AUTOSAR XML (schema 4-2-2)
standard types defined: boolean, sint16, uint16, uint8, Boolean, SInt16, UInt16, UInt8
package /Constants
  34 x constant specification:
    IV_CREPE: value-spec={short-label=IV_CREPE, fields=[0, 0, 0, 0]}
    IV_ChPress: value-spec=0
    IV_ChTemp: value-spec=0
    IV_CompPress: value-spec=0
    IV_CompTemp: value-spec=0
    IV_ERV1Cmd: value-spec={short-label=IV_ERV1Cmd, fields=[FALSE, 0]}
    IV_ERV1State: value-spec={short-label=IV_ERV1State, fields=[0, 0, 0]}
    IV_ERV2Cmd: value-spec={short-label=IV_ERV2Cmd, fields=[FALSE, 0]}
    IV_ERV2State: value-spec={short-label=IV_ERV2State, fields=[0, 0, 0]}
    IV_ERV3Cmd: value-spec={short-label=IV_ERV3Cmd, fields=[FALSE, 0]}
    IV_ERV3State: value-spec={short-label=IV_ERV3State, fields=[0, 0, 0]}
    IV_EVAPPress: value-spec=0
    IV_EVAPTemp: value-spec=0
    IV_EXV1Cmd: value-spec={short-label=IV_EXV1Cmd, fields=[FALSE, 0]}
    IV_EXV1State: value-spec={short-label=IV_EXV1State, fields=[0, 0, 0]}
    IV_EXV2Cmd: value-spec={short-label=IV_EXV2Cmd, fields=[FALSE, 0]}
    IV_EXV2State: value-spec={short-label=IV_EXV2State, fields=[0, 0, 0]}
    IV_EXV3Cmd: value-spec={short-label=IV_EXV3Cmd, fields=[FALSE, 0]}
    IV_EXV3State: value-spec={short-label=IV_EXV3State, fields=[0, 0, 0]}
    IV_EXV4Cmd: value-spec={short-label=IV_EXV4Cmd, fields=[FALSE, 0]}
    IV_EXV4State: value-spec={short-label=IV_EXV4State, fields=[0, 0, 0]}
    IV_Ext: value-spec={short-label=IV_Ext, fields=[0, 0, 0, 0, 0, 0, 0]}
    IV_HTPC_CH: value-spec={short-label=IV_HTPC_CH, fields=[FALSE, 0, 0, 0]}
    IV_HTPC_Comp: value-spec={short-label=IV_HTPC_Comp, fields=[FALSE, FALSE]}
    IV_HTPC_ICDS: value-spec={short-label=IV_HTPC_ICDS, fields=0}
    IV_HTPC_NBI: value-spec={short-label=IV_HTPC_NBI, fields=[0, 0, 0, 0]}
    IV_HTPC_OHX: value-spec={short-label=IV_HTPC_OHX, fields=[FALSE, 0, 0]}
    IV_HVEC2HTPC: value-spec={short-label=IV_HVEC2HTPC, fields=[FALSE, FALSE, 0, 0, 0, 0]}
    IV_HvecCmd: value-spec={short-label=IV_HvecCmd, fields=[FALSE, 0]}
    IV_ICDSPress: value-spec=0
    IV_ICDSTemp: value-spec=0
    IV_OHXPress: value-spec=0
    IV_OHXTemp: value-spec=0
    IV_SUCRE: value-spec={short-label=IV_SUCRE, fields=[FALSE, 0, 0, 0, 0, 0, 0, 0, 0, 0, 0, 0, 0, 0, 0]}
package /DataTypeMappingSets
  237 x data type mapping set:
    DTMS_APDT_AlertState: data-type-map{application-data-type=APDT_AlertState, implementation-data-type=DT_AlertState}
    DTMS_APDT_AvailState: data-type-map{application-data-type=APDT_AvailState, implementation-data-type=DT_AvailState}
    DTMS_APDT_CREPE_rOpFSF: data-type-map{application-data-type=APDT_CREPE_rOpFSF, implementation-data-type=DT_CREPE_rOpFSF}
    DTMS_APDT_CREPE_spdAirEstim: data-type-map{application-data-type=APDT_CREPE_spdAirEstim, implementation-data-type=DT_CREPE_spdAirEstim}
    DTMS_APDT_CREPE_tEstimWaInpChil: data-type-map{application-data-type=APDT_CREPE_tEstimWaInpChil, implementation-data-type=DT_CREPE_tEstimWaInpChil}
    DTMS_APDT_CREPE_volfEstimWaChil: data-type-map{application-data-type=APDT_CREPE_volfEstimWaChil, implementation-data-type=DT_CREPE_volfEstimWaChil}
    DTMS_APDT_ChPress: data-type-map{application-data-type=APDT_ChPress, implementation-data-type=DT_ChPress}
    DTMS_APDT_ChTemp: data-type-map{application-data-type=APDT_ChTemp, implementation-data-type=DT_ChTemp}
    DTMS_APDT_CmptMode: data-type-map{application-data-type=APDT_CmptMode, implementation-data-type=DT_CmptMode}
    DTMS_APDT_CmptMode1: data-type-map{application-data-type=APDT_CmptMode1, implementation-data-type=DT_CmptMode1}
    DTMS_APDT_CmptMode_AcSpport10_del: data-type-map{application-data-type=APDT_CmptMode_AcSpport10_del, implementation-data-type=DT_CmptMode_AcSpport10_del}
    DTMS_APDT_CmptMode_ChSupport12_del: data-type-map{application-data-type=APDT_CmptMode_ChSupport12_del, implementation-data-type=DT_CmptMode_ChSupport12_del}
    DTMS_APDT_CmptMode_Comp4: data-type-map{application-data-type=APDT_CmptMode_Comp4, implementation-data-type=DT_CmptMode_Comp4}
    DTMS_APDT_CmptMode_Erv1_5: data-type-map{application-data-type=APDT_CmptMode_Erv1_5, implementation-data-type=DT_CmptMode_Erv1_5}
    DTMS_APDT_CmptMode_Erv2_6: data-type-map{application-data-type=APDT_CmptMode_Erv2_6, implementation-data-type=DT_CmptMode_Erv2_6}
    DTMS_APDT_CmptMode_Erv3_7: data-type-map{application-data-type=APDT_CmptMode_Erv3_7, implementation-data-type=DT_CmptMode_Erv3_7}
    DTMS_APDT_CmptMode_ExvAc0: data-type-map{application-data-type=APDT_CmptMode_ExvAc0, implementation-data-type=DT_CmptMode_ExvAc0}
    DTMS_APDT_CmptMode_ExvByPass1: data-type-map{application-data-type=APDT_CmptMode_ExvByPass1, implementation-data-type=DT_CmptMode_ExvByPass1}
    DTMS_APDT_CmptMode_ExvCh2: data-type-map{application-data-type=APDT_CmptMode_ExvCh2, implementation-data-type=DT_CmptMode_ExvCh2}
    DTMS_APDT_CmptMode_ExvOhx3: data-type-map{application-data-type=APDT_CmptMode_ExvOhx3, implementation-data-type=DT_CmptMode_ExvOhx3}
    DTMS_APDT_CmptMode_IcdsSupport11: data-type-map{application-data-type=APDT_CmptMode_IcdsSupport11, implementation-data-type=DT_CmptMode_IcdsSupport11}
    DTMS_APDT_CmptMode_Null8: data-type-map{application-data-type=APDT_CmptMode_Null8, implementation-data-type=DT_CmptMode_Null8}
    DTMS_APDT_CmptMode_Null9: data-type-map{application-data-type=APDT_CmptMode_Null9, implementation-data-type=DT_CmptMode_Null9}
    DTMS_APDT_CmptMode_OhxSupport13: data-type-map{application-data-type=APDT_CmptMode_OhxSupport13, implementation-data-type=DT_CmptMode_OhxSupport13}
    DTMS_APDT_CmptUsCapState: data-type-map{application-data-type=APDT_CmptUsCapState, implementation-data-type=DT_CmptUsCapState}
    DTMS_APDT_CmptWorkMode: data-type-map{application-data-type=APDT_CmptWorkMode, implementation-data-type=DT_CmptWorkMode}
    DTMS_APDT_CompPress: data-type-map{application-data-type=APDT_CompPress, implementation-data-type=DT_CompPress}
    DTMS_APDT_CompTemp: data-type-map{application-data-type=APDT_CompTemp, implementation-data-type=DT_CompTemp}
    DTMS_APDT_CpId: data-type-map{application-data-type=APDT_CpId, implementation-data-type=DT_CpId}
    DTMS_APDT_CpPara: data-type-map{application-data-type=APDT_CpPara, implementation-data-type=DT_CpPara}
    DTMS_APDT_CpType: data-type-map{application-data-type=APDT_CpType, implementation-data-type=DT_CpType}
    DTMS_APDT_CpValue: data-type-map{application-data-type=APDT_CpValue, implementation-data-type=DT_CpValue}
    DTMS_APDT_CpValueState: data-type-map{application-data-type=APDT_CpValueState, implementation-data-type=DT_CpValueState}
    DTMS_APDT_CpWorkMode: data-type-map{application-data-type=APDT_CpWorkMode, implementation-data-type=DT_CpWorkMode}
    DTMS_APDT_CtrlMode: data-type-map{application-data-type=APDT_CtrlMode, implementation-data-type=DT_CtrlMode}
    DTMS_APDT_CtrlUsCapState: data-type-map{application-data-type=APDT_CtrlUsCapState, implementation-data-type=DT_CtrlUsCapState}
    DTMS_APDT_EVAPPress: data-type-map{application-data-type=APDT_EVAPPress, implementation-data-type=DT_EVAPPress}
    DTMS_APDT_EVAPTemp: data-type-map{application-data-type=APDT_EVAPTemp, implementation-data-type=DT_EVAPTemp}
    DTMS_APDT_Ext_bHeatPmpCf1: data-type-map{application-data-type=APDT_Ext_bHeatPmpCf1, implementation-data-type=DT_Ext_bHeatPmpCf1}
    DTMS_APDT_Ext_bPwrlimitCmpr: data-type-map{application-data-type=APDT_Ext_bPwrlimitCmpr, implementation-data-type=DT_Ext_bPwrlimitCmpr}
    DTMS_APDT_Ext_bStallCmpr: data-type-map{application-data-type=APDT_Ext_bStallCmpr, implementation-data-type=DT_Ext_bStallCmpr}
    DTMS_APDT_Ext_iCmpr: data-type-map{application-data-type=APDT_Ext_iCmpr, implementation-data-type=DT_Ext_iCmpr}
    DTMS_APDT_Ext_mfAirFanEvapEst: data-type-map{application-data-type=APDT_Ext_mfAirFanEvapEst, implementation-data-type=DT_Ext_mfAirFanEvapEst}
    DTMS_APDT_Ext_mfAirFanICndsEst: data-type-map{application-data-type=APDT_Ext_mfAirFanICndsEst, implementation-data-type=DT_Ext_mfAirFanICndsEst}
    DTMS_APDT_Ext_nCmpr: data-type-map{application-data-type=APDT_Ext_nCmpr, implementation-data-type=DT_Ext_nCmpr}
    DTMS_APDT_Ext_rERV{1..3}Mes: data-type-map{application-data-type=APDT_Ext_rERV{1..3}Mes, implementation-data-type=DT_Ext_rERV{1..3}Mes}
    DTMS_APDT_Ext_rEXV{1..4}Mes: data-type-map{application-data-type=APDT_Ext_rEXV{1..4}Mes, implementation-data-type=DT_Ext_rEXV{1..4}Mes}
    DTMS_APDT_Ext_stERV{1..3}: data-type-map{application-data-type=APDT_Ext_stERV{1..3}, implementation-data-type=DT_Ext_stERV{1..3}}
    DTMS_APDT_Ext_stEXV{1..4}: data-type-map{application-data-type=APDT_Ext_stEXV{1..4}, implementation-data-type=DT_Ext_stEXV{1..4}}
    DTMS_APDT_Ext_stHeatPmpTypCf: data-type-map{application-data-type=APDT_Ext_stHeatPmpTypCf, implementation-data-type=DT_Ext_stHeatPmpTypCf}
    DTMS_APDT_Ext_stRefriTypCf: data-type-map{application-data-type=APDT_Ext_stRefriTypCf, implementation-data-type=DT_Ext_stRefriTypCf}
    DTMS_APDT_Ext_stRefriTypCf1: data-type-map{application-data-type=APDT_Ext_stRefriTypCf1, implementation-data-type=DT_Ext_stRefriTypCf1}
    DTMS_APDT_Ext_tAirInpEvaEst: data-type-map{application-data-type=APDT_Ext_tAirInpEvaEst, implementation-data-type=DT_Ext_tAirInpEvaEst}
    DTMS_APDT_Ext_tAirMes: data-type-map{application-data-type=APDT_Ext_tAirMes, implementation-data-type=DT_Ext_tAirMes}
    DTMS_APDT_Ext_tAirMes1: data-type-map{application-data-type=APDT_Ext_tAirMes1, implementation-data-type=DT_Ext_tAirMes1}
    DTMS_APDT_Ext_tInvCmpr: data-type-map{application-data-type=APDT_Ext_tInvCmpr, implementation-data-type=DT_Ext_tInvCmpr}
    DTMS_APDT_Ext_typERV{1..3}: data-type-map{application-data-type=APDT_Ext_typERV{1..3}, implementation-data-type=DT_Ext_typERV{1..3}}
    DTMS_APDT_Ext_typEXV{1..4}: data-type-map{application-data-type=APDT_Ext_typEXV{1..4}, implementation-data-type=DT_Ext_typEXV{1..4}}
    DTMS_APDT_Ext_uCmpr: data-type-map{application-data-type=APDT_Ext_uCmpr, implementation-data-type=DT_Ext_uCmpr}
    DTMS_APDT_Ext_vehspd: data-type-map{application-data-type=APDT_Ext_vehspd, implementation-data-type=DT_Ext_vehspd}
    DTMS_APDT_Ext_vehspd1: data-type-map{application-data-type=APDT_Ext_vehspd1, implementation-data-type=DT_Ext_vehspd1}
    DTMS_APDT_FlowRateEstim: data-type-map{application-data-type=APDT_FlowRateEstim, implementation-data-type=DT_FlowRateEstim}
    DTMS_APDT_FullFilState: data-type-map{application-data-type=APDT_FullFilState, implementation-data-type=DT_FullFilState}
    DTMS_APDT_HTPC_bAcvCmprReq: data-type-map{application-data-type=APDT_HTPC_bAcvCmprReq, implementation-data-type=DT_HTPC_bAcvCmprReq}
    DTMS_APDT_HTPC_bClsFSFReq: data-type-map{application-data-type=APDT_HTPC_bClsFSFReq, implementation-data-type=DT_HTPC_bClsFSFReq}
    DTMS_APDT_HTPC_bDeicingReq: data-type-map{application-data-type=APDT_HTPC_bDeicingReq, implementation-data-type=DT_HTPC_bDeicingReq}
    DTMS_APDT_HTPC_bERV{1..3}InitReq: data-type-map{application-data-type=APDT_HTPC_bERV{1..3}InitReq, implementation-data-type=DT_HTPC_bERV{1..3}InitReq}
    DTMS_APDT_HTPC_bEXV{1..4}InitReq: data-type-map{application-data-type=APDT_HTPC_bEXV{1..4}InitReq, implementation-data-type=DT_HTPC_bEXV{1..4}InitReq}
    DTMS_APDT_HTPC_bHBoostReq: data-type-map{application-data-type=APDT_HTPC_bHBoostReq, implementation-data-type=DT_HTPC_bHBoostReq}
    DTMS_APDT_HTPC_bspdCmprMaxLim: data-type-map{application-data-type=APDT_HTPC_bspdCmprMaxLim, implementation-data-type=DT_HTPC_bspdCmprMaxLim}
    DTMS_APDT_HTPC_bspdCmprMinLim: data-type-map{application-data-type=APDT_HTPC_bspdCmprMinLim, implementation-data-type=DT_HTPC_bspdCmprMinLim}
    DTMS_APDT_HTPC_nCmprSp: data-type-map{application-data-type=APDT_HTPC_nCmprSp, implementation-data-type=DT_HTPC_nCmprSp}
    DTMS_APDT_HTPC_pwrCndsEstim: data-type-map{application-data-type=APDT_HTPC_pwrCndsEstim, implementation-data-type=DT_HTPC_pwrCndsEstim}
    DTMS_APDT_HTPC_pwrEvapEstim: data-type-map{application-data-type=APDT_HTPC_pwrEvapEstim, implementation-data-type=DT_HTPC_pwrEvapEstim}
    DTMS_APDT_HTPC_rERV{1..3}Req: data-type-map{application-data-type=APDT_HTPC_rERV{1..3}Req, implementation-data-type=DT_HTPC_rERV{1..3}Req}
    DTMS_APDT_HTPC_rEXV{1..4}Req: data-type-map{application-data-type=APDT_HTPC_rEXV{1..4}Req, implementation-data-type=DT_HTPC_rEXV{1..4}Req}
    DTMS_APDT_HTPC_rHVWHSp: data-type-map{application-data-type=APDT_HTPC_rHVWHSp, implementation-data-type=DT_HTPC_rHVWHSp}
    DTMS_APDT_HTPC_spdAirCndSp: data-type-map{application-data-type=APDT_HTPC_spdAirCndSp, implementation-data-type=DT_HTPC_spdAirCndSp}
    DTMS_APDT_HTPC_stFctHeatPmp: data-type-map{application-data-type=APDT_HTPC_stFctHeatPmp, implementation-data-type=DT_HTPC_stFctHeatPmp}
    DTMS_APDT_HTPC_stOHXestim: data-type-map{application-data-type=APDT_HTPC_stOHXestim, implementation-data-type=DT_HTPC_stOHXestim}
    DTMS_APDT_HTPC_tAirOutICoEstim: data-type-map{application-data-type=APDT_HTPC_tAirOutICoEstim, implementation-data-type=DT_HTPC_tAirOutICoEstim}
    DTMS_APDT_HTPC_tWaChilInTrg: data-type-map{application-data-type=APDT_HTPC_tWaChilInTrg, implementation-data-type=DT_HTPC_tWaChilInTrg}
    DTMS_APDT_HTPC_volfWaChilSp: data-type-map{application-data-type=APDT_HTPC_volfWaChilSp, implementation-data-type=DT_HTPC_volfWaChilSp}
    DTMS_APDT_ICDSPress: data-type-map{application-data-type=APDT_ICDSPress, implementation-data-type=DT_ICDSPress}
    DTMS_APDT_ICDSTemp: data-type-map{application-data-type=APDT_ICDSTemp, implementation-data-type=DT_ICDSTemp}
    DTMS_APDT_LoadLevel: data-type-map{application-data-type=APDT_LoadLevel, implementation-data-type=DT_LoadLevel}
    DTMS_APDT_LoadLevelState: data-type-map{application-data-type=APDT_LoadLevelState, implementation-data-type=DT_LoadLevelState}
    DTMS_APDT_LoadPwrRuning: data-type-map{application-data-type=APDT_LoadPwrRuning, implementation-data-type=DT_LoadPwrRuning}
    DTMS_APDT_NextMode: data-type-map{application-data-type=APDT_NextMode, implementation-data-type=DT_NextMode}
    DTMS_APDT_NtfDevState: data-type-map{application-data-type=APDT_NtfDevState, implementation-data-type=DT_NtfDevState}
    DTMS_APDT_NtfPosState: data-type-map{application-data-type=APDT_NtfPosState, implementation-data-type=DT_NtfPosState}
    DTMS_APDT_NtfSensorState: data-type-map{application-data-type=APDT_NtfSensorState, implementation-data-type=DT_NtfSensorState}
    DTMS_APDT_NtfSpdState: data-type-map{application-data-type=APDT_NtfSpdState, implementation-data-type=DT_NtfSpdState}
    DTMS_APDT_OHXPress: data-type-map{application-data-type=APDT_OHXPress, implementation-data-type=DT_OHXPress}
    DTMS_APDT_OHXTemp: data-type-map{application-data-type=APDT_OHXTemp, implementation-data-type=DT_OHXTemp}
    DTMS_APDT_OverallCondenPwr: data-type-map{application-data-type=APDT_OverallCondenPwr, implementation-data-type=DT_OverallCondenPwr}
    DTMS_APDT_OverallEvapPwr: data-type-map{application-data-type=APDT_OverallEvapPwr, implementation-data-type=DT_OverallEvapPwr}
    DTMS_APDT_PPos: data-type-map{application-data-type=APDT_PPos, implementation-data-type=DT_PPos}
    DTMS_APDT_PValue: data-type-map{application-data-type=APDT_PValue, implementation-data-type=DT_PValue}
    DTMS_APDT_PidParaId: data-type-map{application-data-type=APDT_PidParaId, implementation-data-type=DT_PidParaId}
    DTMS_APDT_PwrUpperLimit: data-type-map{application-data-type=APDT_PwrUpperLimit, implementation-data-type=DT_PwrUpperLimit}
    DTMS_APDT_RefrigFlowVolEstim: data-type-map{application-data-type=APDT_RefrigFlowVolEstim, implementation-data-type=DT_RefrigFlowVolEstim}
    DTMS_APDT_RefrigLackStatus: data-type-map{application-data-type=APDT_RefrigLackStatus, implementation-data-type=DT_RefrigLackStatus}
    DTMS_APDT_ReqMode: data-type-map{application-data-type=APDT_ReqMode, implementation-data-type=DT_ReqMode}
    DTMS_APDT_SMax: data-type-map{application-data-type=APDT_SMax, implementation-data-type=DT_SMax}
    DTMS_APDT_SMin: data-type-map{application-data-type=APDT_SMin, implementation-data-type=DT_SMin}
    DTMS_APDT_SPos: data-type-map{application-data-type=APDT_SPos, implementation-data-type=DT_SPos}
    DTMS_APDT_SPosLowerLimit: data-type-map{application-data-type=APDT_SPosLowerLimit, implementation-data-type=DT_SPosLowerLimit}
    DTMS_APDT_SPosUpperLimit: data-type-map{application-data-type=APDT_SPosUpperLimit, implementation-data-type=DT_SPosUpperLimit}
    DTMS_APDT_SUCRE_bDeIcingAuthor: data-type-map{application-data-type=APDT_SUCRE_bDeIcingAuthor, implementation-data-type=DT_SUCRE_bDeIcingAuthor}
    DTMS_APDT_SUCRE_fintempsensor: data-type-map{application-data-type=APDT_SUCRE_fintempsensor, implementation-data-type=DT_SUCRE_fintempsensor}
    DTMS_APDT_SUCRE_nCmprMaxSp: data-type-map{application-data-type=APDT_SUCRE_nCmprMaxSp, implementation-data-type=DT_SUCRE_nCmprMaxSp}
    DTMS_APDT_SUCRE_pwrCmprMaxSp: data-type-map{application-data-type=APDT_SUCRE_pwrCmprMaxSp, implementation-data-type=DT_SUCRE_pwrCmprMaxSp}
    DTMS_APDT_SUCRE_pwrHVWHMaxSp: data-type-map{application-data-type=APDT_SUCRE_pwrHVWHMaxSp, implementation-data-type=DT_SUCRE_pwrHVWHMaxSp}
    DTMS_APDT_SUCRE_rHVWHAct: data-type-map{application-data-type=APDT_SUCRE_rHVWHAct, implementation-data-type=DT_SUCRE_rHVWHAct}
    DTMS_APDT_SUCRE_stHeatPmpModReq: data-type-map{application-data-type=APDT_SUCRE_stHeatPmpModReq, implementation-data-type=DT_SUCRE_stHeatPmpModReq}
    DTMS_APDT_SUCRE_tAirOutEvaSp: data-type-map{application-data-type=APDT_SUCRE_tAirOutEvaSp, implementation-data-type=DT_SUCRE_tAirOutEvaSp}
    DTMS_APDT_SUCRE_tAirOutEvapOfs: data-type-map{application-data-type=APDT_SUCRE_tAirOutEvapOfs, implementation-data-type=DT_SUCRE_tAirOutEvapOfs}
    DTMS_APDT_SUCRE_tAirOutICoSp: data-type-map{application-data-type=APDT_SUCRE_tAirOutICoSp, implementation-data-type=DT_SUCRE_tAirOutICoSp}
    DTMS_APDT_SUCRE_tAirOutIEvaMes: data-type-map{application-data-type=APDT_SUCRE_tAirOutIEvaMes, implementation-data-type=DT_SUCRE_tAirOutIEvaMes}
    DTMS_APDT_SUCRE_tWaOutChilMaxSp: data-type-map{application-data-type=APDT_SUCRE_tWaOutChilMaxSp, implementation-data-type=DT_SUCRE_tWaOutChilMaxSp}
    DTMS_APDT_SUCRE_tWaOutChilMes: data-type-map{application-data-type=APDT_SUCRE_tWaOutChilMes, implementation-data-type=DT_SUCRE_tWaOutChilMes}
    DTMS_APDT_SUCRE_tWaOutChilMinSp: data-type-map{application-data-type=APDT_SUCRE_tWaOutChilMinSp, implementation-data-type=DT_SUCRE_tWaOutChilMinSp}
    DTMS_APDT_SUCRE_tWaOutChilSp: data-type-map{application-data-type=APDT_SUCRE_tWaOutChilSp, implementation-data-type=DT_SUCRE_tWaOutChilSp}
    DTMS_APDT_SValue: data-type-map{application-data-type=APDT_SValue, implementation-data-type=DT_SValue}
    DTMS_APDT_TrpId: data-type-map{application-data-type=APDT_TrpId, implementation-data-type=DT_TrpId}
    DTMS_APDT_UsCapState: data-type-map{application-data-type=APDT_UsCapState, implementation-data-type=DT_UsCapState}
    DTMS_APDT_WorkMode: data-type-map{application-data-type=APDT_WorkMode, implementation-data-type=DT_WorkMode}
    DTMS_APDT_WorkMode1: data-type-map{application-data-type=APDT_WorkMode1, implementation-data-type=DT_WorkMode1}
    DTMS_ARDT_BusActCtrlSetElement: data-type-map{application-data-type=ARDT_BusActCtrlSetElement, implementation-data-type=RT_BusActCtrlSetElement}
    DTMS_ARDT_BusActStatusElement: data-type-map{application-data-type=ARDT_BusActStatusElement, implementation-data-type=RT_BusActStatusElement}
    DTMS_ARDT_BusCmptModeElement: data-type-map{application-data-type=ARDT_BusCmptModeElement, implementation-data-type=RT_BusCmptModeElement}
    DTMS_ARDT_BusCpCtrlSetElement: data-type-map{application-data-type=ARDT_BusCpCtrlSetElement, implementation-data-type=RT_BusCpCtrlSetElement}
    DTMS_ARDT_BusCpStElement: data-type-map{application-data-type=ARDT_BusCpStElement, implementation-data-type=RT_BusCpStElement}
    DTMS_ARDT_BusTrpSetElement: data-type-map{application-data-type=ARDT_BusTrpSetElement, implementation-data-type=RT_BusTrpSetElement}
    DTMS_ARDT_BusTrpStateElement: data-type-map{application-data-type=ARDT_BusTrpStateElement, implementation-data-type=RT_BusTrpStateElement}
    DTMS_ARDT_CREPE: data-type-map{application-data-type=ARDT_CREPE, implementation-data-type=RT_CREPE}
    DTMS_ARDT_ERV1Cmd: data-type-map{application-data-type=ARDT_ERV1Cmd, implementation-data-type=RT_ERV1Cmd}
    DTMS_ARDT_ERV1State: data-type-map{application-data-type=ARDT_ERV1State, implementation-data-type=RT_ERV1State}
    DTMS_ARDT_ERV2Cmd: data-type-map{application-data-type=ARDT_ERV2Cmd, implementation-data-type=RT_ERV2Cmd}
    DTMS_ARDT_ERV2State: data-type-map{application-data-type=ARDT_ERV2State, implementation-data-type=RT_ERV2State}
    DTMS_ARDT_ERV3Cmd: data-type-map{application-data-type=ARDT_ERV3Cmd, implementation-data-type=RT_ERV3Cmd}
    DTMS_ARDT_ERV3State: data-type-map{application-data-type=ARDT_ERV3State, implementation-data-type=RT_ERV3State}
    DTMS_ARDT_EXV1Cmd: data-type-map{application-data-type=ARDT_EXV1Cmd, implementation-data-type=RT_EXV1Cmd}
    DTMS_ARDT_EXV1State: data-type-map{application-data-type=ARDT_EXV1State, implementation-data-type=RT_EXV1State}
    DTMS_ARDT_EXV2Cmd: data-type-map{application-data-type=ARDT_EXV2Cmd, implementation-data-type=RT_EXV2Cmd}
    DTMS_ARDT_EXV2State: data-type-map{application-data-type=ARDT_EXV2State, implementation-data-type=RT_EXV2State}
    DTMS_ARDT_EXV3Cmd: data-type-map{application-data-type=ARDT_EXV3Cmd, implementation-data-type=RT_EXV3Cmd}
    DTMS_ARDT_EXV3State: data-type-map{application-data-type=ARDT_EXV3State, implementation-data-type=RT_EXV3State}
    DTMS_ARDT_EXV4Cmd: data-type-map{application-data-type=ARDT_EXV4Cmd, implementation-data-type=RT_EXV4Cmd}
    DTMS_ARDT_EXV4State: data-type-map{application-data-type=ARDT_EXV4State, implementation-data-type=RT_EXV4State}
    DTMS_ARDT_Ext: data-type-map{application-data-type=ARDT_Ext, implementation-data-type=RT_Ext}
    DTMS_ARDT_HTPC_CH: data-type-map{application-data-type=ARDT_HTPC_CH, implementation-data-type=RT_HTPC_CH}
    DTMS_ARDT_HTPC_Comp: data-type-map{application-data-type=ARDT_HTPC_Comp, implementation-data-type=RT_HTPC_Comp}
    DTMS_ARDT_HTPC_CompTpcp19In: data-type-map{application-data-type=ARDT_HTPC_CompTpcp19In, implementation-data-type=RT_HTPC_CompTpcp19In}
    DTMS_ARDT_HTPC_CompTpcp8: data-type-map{application-data-type=ARDT_HTPC_CompTpcp24, implementation-data-type=RT_HTPC_CompTpcp24}
    DTMS_ARDT_HTPC_HpAcSensor0: data-type-map{application-data-type=ARDT_HTPC_HpAcSensor0, implementation-data-type=RT_HTPC_HpAcSensor0}
    DTMS_ARDT_HTPC_HpAcSupportState: data-type-map{application-data-type=ARDT_HTPC_HpAcSupportState, implementation-data-type=RT_HTPC_HpAcSupportState}
    DTMS_ARDT_HTPC_HpAcTpcp4: data-type-map{application-data-type=ARDT_HTPC_HpAcTpcp20, implementation-data-type=RT_HTPC_HpAcTpcp20}
    DTMS_ARDT_HTPC_HpBusActCtrlSet: data-type-map{application-data-type=ARDT_HTPC_HpBusActCtrlSet, implementation-data-type=RT_HTPC_HpBusActCtrlSet}
    DTMS_ARDT_HTPC_HpBusActStatus: data-type-map{application-data-type=ARDT_HTPC_HpBusActStatus, implementation-data-type=RT_HTPC_HpBusActStatus}
    DTMS_ARDT_HTPC_HpBusCmptModeResp: data-type-map{application-data-type=ARDT_HTPC_HpBusCmptModeResp, implementation-data-type=RT_HTPC_HpBusCmptModeResp}
    DTMS_ARDT_HTPC_HpBusCpCtrlSet: data-type-map{application-data-type=ARDT_HTPC_HpBusCpCtrlSet, implementation-data-type=RT_HTPC_HpBusCpCtrlSet}
    DTMS_ARDT_HTPC_HpBusCpSt: data-type-map{application-data-type=ARDT_HTPC_HpBusCpSt, implementation-data-type=RT_HTPC_HpBusCpSt}
    DTMS_ARDT_HTPC_HpBusTrpSet_Cmpt: data-type-map{application-data-type=ARDT_HTPC_HpBusTrpSet_Cmpt, implementation-data-type=RT_HTPC_HpBusTrpSet_Cmpt}
    DTMS_ARDT_HTPC_HpBusTrpSet_Ctrl: data-type-map{application-data-type=ARDT_HTPC_HpBusTrpSet_Ctrl, implementation-data-type=RT_HTPC_HpBusTrpSet_Ctrl}
    DTMS_ARDT_HTPC_HpBusTrpSet_Loop: data-type-map{application-data-type=ARDT_HTPC_HpBusTrpSet_Loop, implementation-data-type=RT_HTPC_HpBusTrpSet_Loop}
    DTMS_ARDT_HTPC_HpBusTrpSet_NBI: data-type-map{application-data-type=ARDT_HTPC_HpBusTrpSet_NBI, implementation-data-type=RT_HTPC_HpBusTrpSet_NBI}
    DTMS_ARDT_HTPC_HpBusTrpSet_Req: data-type-map{application-data-type=ARDT_HTPC_HpBusTrpSet_Req, implementation-data-type=RT_HTPC_HpBusTrpSet_Req}
    DTMS_ARDT_HTPC_HpBusTrpState: data-type-map{application-data-type=ARDT_HTPC_HpBusTrpState, implementation-data-type=RT_HTPC_HpBusTrpState}
    DTMS_ARDT_HTPC_HpChSensor2: data-type-map{application-data-type=ARDT_HTPC_HpChSensor2, implementation-data-type=RT_HTPC_HpChSensor2}
    DTMS_ARDT_HTPC_HpChSupportState: data-type-map{application-data-type=ARDT_HTPC_HpChSupportState, implementation-data-type=RT_HTPC_HpChSupportState}
    DTMS_ARDT_HTPC_HpChTpcp6: data-type-map{application-data-type=ARDT_HTPC_HpChTpcp22, implementation-data-type=RT_HTPC_HpChTpcp22}
    DTMS_ARDT_HTPC_HpCompState: data-type-map{application-data-type=ARDT_HTPC_HpCompState, implementation-data-type=RT_HTPC_HpCompState}
    DTMS_ARDT_HTPC_HpErv{1..3}State: data-type-map{application-data-type=ARDT_HTPC_HpErv{1..3}State, implementation-data-type=RT_HTPC_HpErv{1..3}State}
    DTMS_ARDT_HTPC_HpExvAState: data-type-map{application-data-type=ARDT_HTPC_HpExvAState, implementation-data-type=RT_HTPC_HpExvAState}
    DTMS_ARDT_HTPC_HpExvBState: data-type-map{application-data-type=ARDT_HTPC_HpExvBState, implementation-data-type=RT_HTPC_HpExvBState}
    DTMS_ARDT_HTPC_HpExvByPassState: data-type-map{application-data-type=ARDT_HTPC_HpExvByPassState, implementation-data-type=RT_HTPC_HpExvByPassState}
    DTMS_ARDT_HTPC_HpExvHState: data-type-map{application-data-type=ARDT_HTPC_HpExvHState, implementation-data-type=RT_HTPC_HpExvHState}
    DTMS_ARDT_HTPC_HpIcdsSensor1: data-type-map{application-data-type=ARDT_HTPC_HpIcdsSensor1, implementation-data-type=RT_HTPC_HpIcdsSensor1}
    DTMS_ARDT_HTPC_HpIcdsSupportState: data-type-map{application-data-type=ARDT_HTPC_HpIcdsSupportState, implementation-data-type=RT_HTPC_HpIcdsSupportState}
    DTMS_ARDT_HTPC_HpIcdsTpcp5: data-type-map{application-data-type=ARDT_HTPC_HpIcdsTpcp21, implementation-data-type=RT_HTPC_HpIcdsTpcp21}
    DTMS_ARDT_HTPC_HpOhxSensor3: data-type-map{application-data-type=ARDT_HTPC_HpOhxSensor3, implementation-data-type=RT_HTPC_HpOhxSensor3}
    DTMS_ARDT_HTPC_HpOhxSupportState: data-type-map{application-data-type=ARDT_HTPC_HpOhxSupportState, implementation-data-type=RT_HTPC_HpOhxSupportState}
    DTMS_ARDT_HTPC_HpOhxTpcp18In: data-type-map{application-data-type=ARDT_HTPC_HpOhxTpcp18In, implementation-data-type=RT_HTPC_HpOhxTpcp18In}
    DTMS_ARDT_HTPC_HpOhxTpcp7: data-type-map{application-data-type=ARDT_HTPC_HpOhxTpcp23, implementation-data-type=RT_HTPC_HpOhxTpcp23}
    DTMS_ARDT_HTPC_HpOverallCycleStatus: data-type-map{application-data-type=ARDT_HTPC_HpOverallCycleStatus, implementation-data-type=RT_HTPC_HpOverallCycleStatus}
    DTMS_ARDT_HTPC_ICDS: data-type-map{application-data-type=ARDT_HTPC_ICDS, implementation-data-type=RT_HTPC_ICDS}
    DTMS_ARDT_HTPC_LoopDiversity: data-type-map{application-data-type=ARDT_HTPC_LoopDiversity, implementation-data-type=RT_HTPC_LoopDiversity}
    DTMS_ARDT_HTPC_NBI: data-type-map{application-data-type=ARDT_HTPC_NBI, implementation-data-type=RT_HTPC_NBI}
    DTMS_ARDT_HTPC_OHX: data-type-map{application-data-type=ARDT_HTPC_OHX, implementation-data-type=RT_HTPC_OHX}
    DTMS_ARDT_HTPC_PAcO20: data-type-map{application-data-type=ARDT_HTPC_PAcO10, implementation-data-type=RT_HTPC_PAcO10}
    DTMS_ARDT_HTPC_PChO22: data-type-map{application-data-type=ARDT_HTPC_PChO12, implementation-data-type=RT_HTPC_PChO12}
    DTMS_ARDT_HTPC_PCompIn15: data-type-map{application-data-type=ARDT_HTPC_PCompIn15, implementation-data-type=RT_HTPC_PCompIn15}
    DTMS_ARDT_HTPC_PCompO24: data-type-map{application-data-type=ARDT_HTPC_PCompO14, implementation-data-type=RT_HTPC_PCompO14}
    DTMS_ARDT_HTPC_PIcdsO21: data-type-map{application-data-type=ARDT_HTPC_PIcdsO11, implementation-data-type=RT_HTPC_PIcdsO11}
    DTMS_ARDT_HTPC_POhxIn17: data-type-map{application-data-type=ARDT_HTPC_POhxIn17, implementation-data-type=RT_HTPC_POhxIn17}
    DTMS_ARDT_HTPC_POhxO23: data-type-map{application-data-type=ARDT_HTPC_POhxO13, implementation-data-type=RT_HTPC_POhxO13}
    DTMS_ARDT_HTPC_TAcO10: data-type-map{application-data-type=ARDT_HTPC_TAcO5, implementation-data-type=RT_HTPC_TAcO5}
    DTMS_ARDT_HTPC_TChO12: data-type-map{application-data-type=ARDT_HTPC_TChO7, implementation-data-type=RT_HTPC_TChO7}
    DTMS_ARDT_HTPC_TCompIn4: data-type-map{application-data-type=ARDT_HTPC_TCompIn4, implementation-data-type=RT_HTPC_TCompIn4}
    DTMS_ARDT_HTPC_TCompO14: data-type-map{application-data-type=ARDT_HTPC_TCompO9, implementation-data-type=RT_HTPC_TCompO9}
    DTMS_ARDT_HTPC_TIcdsO11: data-type-map{application-data-type=ARDT_HTPC_TIcdsO6, implementation-data-type=RT_HTPC_TIcdsO6}
    DTMS_ARDT_HTPC_TOhxIn16: data-type-map{application-data-type=ARDT_HTPC_TOhxIn16, implementation-data-type=RT_HTPC_TOhxIn16}
    DTMS_ARDT_HTPC_TOhxO13: data-type-map{application-data-type=ARDT_HTPC_TOhxO8, implementation-data-type=RT_HTPC_TOhxO8}
    DTMS_ARDT_HVEC2HTPC: data-type-map{application-data-type=ARDT_HVEC2HTPC, implementation-data-type=RT_HVEC2HTPC}
    DTMS_ARDT_HvecCmd: data-type-map{application-data-type=ARDT_HvecCmd, implementation-data-type=RT_HvecCmd}
    DTMS_ARDT_SUCRE: data-type-map{application-data-type=ARDT_SUCRE, implementation-data-type=RT_SUCRE}
    DTMS_EcuM_Mode: mode-request-type-map{implementation-data-type=UInt8, mode-group=EcuM_Mode}
    DTMS_RCD_stWkuMainRelSt: mode-request-type-map{implementation-data-type=UInt8, mode-group=RCD_stWkuMainRelSt}
package /DataTypes/ApplicationDataTypes
  154 x app type, all with category=VALUE, compu {phys=raw; unit psa_no_unit}:
    APDT_AlertState: range phys 0..255
    APDT_AvailState: range phys 0..255
    APDT_CREPE_rOpFSF: range phys 0..255
    APDT_CREPE_spdAirEstim: range phys -32768..32767
    APDT_CREPE_tEstimWaInpChil: range phys -32768..32767
    APDT_CREPE_volfEstimWaChil: range phys -32768..32767
    APDT_ChPress: range phys -32768..32767
    APDT_ChTemp: range phys -32768..32767
    APDT_CmptMode: range phys 0..255
    APDT_CmptMode1: range phys 0..255
    APDT_CmptMode_AcSpport10_del: range phys 0..255
    APDT_CmptMode_ChSupport12_del: range phys 0..255
    APDT_CmptMode_Comp4: range phys 0..255
    APDT_CmptMode_Erv1_5: range phys 0..255
    APDT_CmptMode_Erv2_6: range phys 0..255
    APDT_CmptMode_Erv3_7: range phys 0..255
    APDT_CmptMode_ExvAc0: range phys 0..255
    APDT_CmptMode_ExvByPass1: range phys 0..255
    APDT_CmptMode_ExvCh2: range phys 0..255
    APDT_CmptMode_ExvOhx3: range phys 0..255
    APDT_CmptMode_IcdsSupport11: range phys 0..255
    APDT_CmptMode_Null8: range phys 0..255
    APDT_CmptMode_Null9: range phys 0..255
    APDT_CmptMode_OhxSupport13: range phys 0..255
    APDT_CmptUsCapState: range phys 0..255
    APDT_CmptWorkMode: range phys 0..255
    APDT_CompPress: range phys -32768..32767
    APDT_CompTemp: range phys -32768..32767
    APDT_CpId: range phys 0..255
    APDT_CpPara: range phys 0..255
    APDT_CpType: range phys 0..255
    APDT_CpValue: range phys -32768..32767
    APDT_CpValueState: range phys 0..255
    APDT_CpWorkMode: range phys 0..255
    APDT_CtrlMode: range phys 0..255
    APDT_CtrlUsCapState: range phys 0..255
    APDT_EVAPPress: range phys -32768..32767
    APDT_EVAPTemp: range phys -32768..32767
    APDT_Ext_bHeatPmpCf1: range phys 0..255
    APDT_Ext_bPwrlimitCmpr: range phys 0..1
    APDT_Ext_bStallCmpr: range phys 0..1
    APDT_Ext_iCmpr: range phys -32768..32767
    APDT_Ext_mfAirFanEvapEst: range phys -32768..32767
    APDT_Ext_mfAirFanICndsEst: range phys -32768..32767
    APDT_Ext_nCmpr: range phys -32768..32767
    APDT_Ext_rERV{1..3}Mes: range phys 0..65535
    APDT_Ext_rEXV{1..4}Mes: range phys 0..65535
    APDT_Ext_stERV{1..3}: range phys 0..255
    APDT_Ext_stEXV{1..4}: range phys 0..255
    APDT_Ext_stHeatPmpTypCf: range phys 0..255
    APDT_Ext_stRefriTypCf: range phys 0..255
    APDT_Ext_stRefriTypCf1: range phys 0..255
    APDT_Ext_tAirInpEvaEst: range phys -32768..32767
    APDT_Ext_tAirMes: range phys -32768..32767
    APDT_Ext_tAirMes1: range phys -32768..32767
    APDT_Ext_tInvCmpr: range phys -32768..32767
    APDT_Ext_typERV{1..3}: range phys -32768..32767
    APDT_Ext_typEXV{1..4}: range phys -32768..32767
    APDT_Ext_uCmpr: range phys -32768..32767
    APDT_Ext_vehspd: range phys -32768..32767
    APDT_Ext_vehspd1: range phys -32768..32767
    APDT_FlowRateEstim: range phys -32768..32767
    APDT_FullFilState: range phys 0..255
    APDT_HTPC_bAcvCmprReq: range phys 0..1
    APDT_HTPC_bClsFSFReq: range phys 0..1
    APDT_HTPC_bDeicingReq: range phys 0..1
    APDT_HTPC_bERV{1..3}InitReq: range phys 0..1
    APDT_HTPC_bEXV{1..4}InitReq: range phys 0..1
    APDT_HTPC_bHBoostReq: range phys 0..1
    APDT_HTPC_bspdCmprMaxLim: range phys 0..1
    APDT_HTPC_bspdCmprMinLim: range phys 0..1
    APDT_HTPC_nCmprSp: range phys -32768..32767
    APDT_HTPC_pwrCndsEstim: range phys -32768..32767
    APDT_HTPC_pwrEvapEstim: range phys -32768..32767
    APDT_HTPC_rERV{1..3}Req: range phys 0..65535
    APDT_HTPC_rEXV{1..4}Req: range phys 0..65535
    APDT_HTPC_rHVWHSp: range phys 0..255
    APDT_HTPC_spdAirCndSp: range phys -32768..32767
    APDT_HTPC_stFctHeatPmp: range phys 0..255
    APDT_HTPC_stOHXestim: range phys 0..255
    APDT_HTPC_tAirOutICoEstim: range phys -32768..32767
    APDT_HTPC_tWaChilInTrg: range phys -32768..32767
    APDT_HTPC_volfWaChilSp: range phys -32768..32767
    APDT_ICDSPress: range phys -32768..32767
    APDT_ICDSTemp: range phys -32768..32767
    APDT_LoadLevel: range phys 0..255
    APDT_LoadLevelState: range phys 0..255
    APDT_LoadPwrRuning: range phys -32768..32767
    APDT_NextMode: range phys 0..255
    APDT_NtfDevState: range phys -32768..32767
    APDT_NtfPosState: range phys -32768..32767
    APDT_NtfSensorState: range phys -32768..32767
    APDT_NtfSpdState: range phys -32768..32767
    APDT_OHXPress: range phys -32768..32767
    APDT_OHXTemp: range phys -32768..32767
    APDT_OverallCondenPwr: range phys -32768..32767
    APDT_OverallEvapPwr: range phys -32768..32767
    APDT_PPos: range phys -32768..32767
    APDT_PValue: range phys -32768..32767
    APDT_PidParaId: range phys 0..255
    APDT_PwrUpperLimit: range phys -32768..32767
    APDT_RefrigFlowVolEstim: range phys -32768..32767
    APDT_RefrigLackStatus: range phys 0..255
    APDT_ReqMode: range phys 0..255
    APDT_SMax: range phys -32768..32767
    APDT_SMin: range phys -32768..32767
    APDT_SPos: range phys -32768..32767
    APDT_SPosLowerLimit: range phys -32768..32767
    APDT_SPosUpperLimit: range phys -32768..32767
    APDT_SUCRE_bDeIcingAuthor: range phys 0..1
    APDT_SUCRE_fintempsensor: range phys -32768..32767
    APDT_SUCRE_nCmprMaxSp: range phys -32768..32767
    APDT_SUCRE_pwrCmprMaxSp: range phys -32768..32767
    APDT_SUCRE_pwrHVWHMaxSp: range phys -32768..32767
    APDT_SUCRE_rHVWHAct: range phys 0..255
    APDT_SUCRE_stHeatPmpModReq: range phys 0..255
    APDT_SUCRE_tAirOutEvaSp: range phys -32768..32767
    APDT_SUCRE_tAirOutEvapOfs: range phys -32768..32767
    APDT_SUCRE_tAirOutICoSp: range phys -32768..32767
    APDT_SUCRE_tAirOutIEvaMes: range phys -32768..32767
    APDT_SUCRE_tWaOutChilMaxSp: range phys -32768..32767
    APDT_SUCRE_tWaOutChilMes: range phys -32768..32767
    APDT_SUCRE_tWaOutChilMinSp: range phys -32768..32767
    APDT_SUCRE_tWaOutChilSp: range phys -32768..32767
    APDT_SValue: range phys -32768..32767
    APDT_TrpId: range phys 0..255
    APDT_UsCapState: range phys 0..255
    APDT_WorkMode: range phys 0..255
    APDT_WorkMode1: range phys 0..255
  81 x application record data type, all with category=STRUCTURE:
    ARDT_BusActCtrlSetElement
      8 x application record element, all with category=VALUE:
        PidParaId: type=APDT_PidParaId
        CtrlMode: type=APDT_CtrlMode
        TrpId: type=APDT_TrpId
        CpId: type=APDT_CpId
        CmptMode: type=APDT_CmptMode
        PwrUpperLimit: type=APDT_PwrUpperLimit
        SPosUpperLimit: type=APDT_SPosUpperLimit
        SPosLowerLimit: type=APDT_SPosLowerLimit
    ARDT_BusActStatusElement
      7 x application record element, all with category=VALUE:
        CtrlUsCapState: type=APDT_CtrlUsCapState
        CmptUsCapState: type=APDT_CmptUsCapState
        LoadLevelState: type=APDT_LoadLevelState
        PPos: type=APDT_PPos
        SPos: type=APDT_SPos
        FlowRateEstim: type=APDT_FlowRateEstim
        CmptWorkMode: type=APDT_CmptWorkMode
    ARDT_BusCmptModeElement
      14 x application record element, all with category=VALUE:
        CmptMode_ExvAc0: type=APDT_CmptMode_ExvAc0
        CmptMode_ExvByPass1: type=APDT_CmptMode_ExvByPass1
        CmptMode_ExvCh2: type=APDT_CmptMode_ExvCh2
        CmptMode_ExvOhx3: type=APDT_CmptMode_ExvOhx3
        CmptMode_Comp4: type=APDT_CmptMode_Comp4
        CmptMode_Erv1_5: type=APDT_CmptMode_Erv1_5
        CmptMode_Erv2_6: type=APDT_CmptMode_Erv2_6
        CmptMode_Erv3_7: type=APDT_CmptMode_Erv3_7
        CmptMode_Null8: type=APDT_CmptMode_Null8
        CmptMode_Null9: type=APDT_CmptMode_Null9
        CmptMode_AcSpport10_del: type=APDT_CmptMode_AcSpport10_del
        CmptMode_IcdsSupport11: type=APDT_CmptMode_IcdsSupport11
        CmptMode_ChSupport12_del: type=APDT_CmptMode_ChSupport12_del
        CmptMode_OhxSupport13: type=APDT_CmptMode_OhxSupport13
    ARDT_BusCpCtrlSetElement
      application record element CmptMode1: category=VALUE, type=APDT_CmptMode1
      application record element CpPara: category=VALUE, type=APDT_CpPara
    ARDT_BusCpStElement
      4 x application record element, all with category=VALUE:
        CpType: type=APDT_CpType
        CpValueState: type=APDT_CpValueState
        CpWorkMode: type=APDT_CpWorkMode
        CpValue: type=APDT_CpValue
    ARDT_BusTrpSetElement
      5 x application record element, all with category=VALUE:
        SValue: type=APDT_SValue
        SMax: type=APDT_SMax
        SMin: type=APDT_SMin
        ReqMode: type=APDT_ReqMode
        NextMode: type=APDT_NextMode
    ARDT_BusTrpStateElement
      8 x application record element, all with category=VALUE:
        AlertState: type=APDT_AlertState
        AvailState: type=APDT_AvailState
        FullFilState: type=APDT_FullFilState
        UsCapState: type=APDT_UsCapState
        WorkMode1: type=APDT_WorkMode1
        LoadLevel: type=APDT_LoadLevel
        PValue: type=APDT_PValue
        LoadPwrRuning: type=APDT_LoadPwrRuning
    ARDT_CREPE
      4 x application record element, all with category=VALUE:
        CREPE_rOpFSF: type=APDT_CREPE_rOpFSF
        CREPE_spdAirEstim: type=APDT_CREPE_spdAirEstim
        CREPE_tEstimWaInpChil: type=APDT_CREPE_tEstimWaInpChil
        CREPE_volfEstimWaChil: type=APDT_CREPE_volfEstimWaChil
    ARDT_ERV1Cmd
      application record element HTPC_bERV1InitReq: category=VALUE, type=APDT_HTPC_bERV1InitReq
      application record element HTPC_rERV1Req: category=VALUE, type=APDT_HTPC_rERV1Req
    ARDT_ERV1State
      application record element Ext_rERV1Mes: category=VALUE, type=APDT_Ext_rERV1Mes
      application record element Ext_stERV1: category=VALUE, type=APDT_Ext_stERV1
      application record element Ext_typERV1: category=VALUE, type=APDT_Ext_typERV1
    ARDT_ERV2Cmd
      application record element HTPC_bERV2InitReq: category=VALUE, type=APDT_HTPC_bERV2InitReq
      application record element HTPC_rERV2Req: category=VALUE, type=APDT_HTPC_rERV2Req
    ARDT_ERV2State
      application record element Ext_rERV2Mes: category=VALUE, type=APDT_Ext_rERV2Mes
      application record element Ext_stERV2: category=VALUE, type=APDT_Ext_stERV2
      application record element Ext_typERV2: category=VALUE, type=APDT_Ext_typERV2
    ARDT_ERV3Cmd
      application record element HTPC_bERV3InitReq: category=VALUE, type=APDT_HTPC_bERV3InitReq
      application record element HTPC_rERV3Req: category=VALUE, type=APDT_HTPC_rERV3Req
    ARDT_ERV3State
      application record element Ext_rERV3Mes: category=VALUE, type=APDT_Ext_rERV3Mes
      application record element Ext_stERV3: category=VALUE, type=APDT_Ext_stERV3
      application record element Ext_typERV3: category=VALUE, type=APDT_Ext_typERV3
    ARDT_EXV1Cmd
      application record element HTPC_bEXV1InitReq: category=VALUE, type=APDT_HTPC_bEXV1InitReq
      application record element HTPC_rEXV1Req: category=VALUE, type=APDT_HTPC_rEXV1Req
    ARDT_EXV1State
      application record element Ext_rEXV1Mes: category=VALUE, type=APDT_Ext_rEXV1Mes
      application record element Ext_stEXV1: category=VALUE, type=APDT_Ext_stEXV1
      application record element Ext_typEXV1: category=VALUE, type=APDT_Ext_typEXV1
    ARDT_EXV2Cmd
      application record element HTPC_bEXV2InitReq: category=VALUE, type=APDT_HTPC_bEXV2InitReq
      application record element HTPC_rEXV2Req: category=VALUE, type=APDT_HTPC_rEXV2Req
    ARDT_EXV2State
      application record element Ext_rEXV2Mes: category=VALUE, type=APDT_Ext_rEXV2Mes
      application record element Ext_stEXV2: category=VALUE, type=APDT_Ext_stEXV2
      application record element Ext_typEXV2: category=VALUE, type=APDT_Ext_typEXV2
    ARDT_EXV3Cmd
      application record element HTPC_bEXV3InitReq: category=VALUE, type=APDT_HTPC_bEXV3InitReq
      application record element HTPC_rEXV3Req: category=VALUE, type=APDT_HTPC_rEXV3Req
    ARDT_EXV3State
      application record element Ext_rEXV3Mes: category=VALUE, type=APDT_Ext_rEXV3Mes
      application record element Ext_stEXV3: category=VALUE, type=APDT_Ext_stEXV3
      application record element Ext_typEXV3: category=VALUE, type=APDT_Ext_typEXV3
    ARDT_EXV4Cmd
      application record element HTPC_bEXV4InitReq: category=VALUE, type=APDT_HTPC_bEXV4InitReq
      application record element HTPC_rEXV4Req: category=VALUE, type=APDT_HTPC_rEXV4Req
    ARDT_EXV4State
      application record element Ext_rEXV4Mes: category=VALUE, type=APDT_Ext_rEXV4Mes
      application record element Ext_stEXV4: category=VALUE, type=APDT_Ext_stEXV4
      application record element Ext_typEXV4: category=VALUE, type=APDT_Ext_typEXV4
    ARDT_Ext
      7 x application record element, all with category=VALUE:
        Ext_mfAirFanEvapEst: type=APDT_Ext_mfAirFanEvapEst
        Ext_mfAirFanICndsEst: type=APDT_Ext_mfAirFanICndsEst
        Ext_stHeatPmpTypCf: type=APDT_Ext_stHeatPmpTypCf
        Ext_stRefriTypCf: type=APDT_Ext_stRefriTypCf
        Ext_tAirInpEvaEst: type=APDT_Ext_tAirInpEvaEst
        Ext_tAirMes: type=APDT_Ext_tAirMes
        Ext_vehspd: type=APDT_Ext_vehspd
    ARDT_HTPC_CH
      4 x application record element, all with category=VALUE:
        HTPC_bHBoostReq: type=APDT_HTPC_bHBoostReq
        HTPC_rHVWHSp: type=APDT_HTPC_rHVWHSp
        HTPC_tWaChilInTrg: type=APDT_HTPC_tWaChilInTrg
        HTPC_volfWaChilSp: type=APDT_HTPC_volfWaChilSp
    ARDT_HTPC_Comp
      application record element HTPC_bspdCmprMaxLim: category=VALUE, type=APDT_HTPC_bspdCmprMaxLim
      application record element HTPC_bspdCmprMinLim: category=VALUE, type=APDT_HTPC_bspdCmprMinLim
    ARDT_HTPC_CompTpcp19In
      4 x application record element, all with category=VALUE:
        CpType: type=APDT_CpType
        CpValueState: type=APDT_CpValueState
        CpWorkMode: type=APDT_CpWorkMode
        CpValue: type=APDT_CpValue
    ARDT_HTPC_CompTpcp24
      4 x application record element, all with category=VALUE:
        CpType: type=APDT_CpType
        CpValueState: type=APDT_CpValueState
        CpWorkMode: type=APDT_CpWorkMode
        CpValue: type=APDT_CpValue
    ARDT_HTPC_HpAcSensor0
      4 x application record element, all with category=VALUE:
        CpType: type=APDT_CpType
        CpValueState: type=APDT_CpValueState
        CpWorkMode: type=APDT_CpWorkMode
        CpValue: type=APDT_CpValue
    ARDT_HTPC_HpAcSupportState
      7 x application record element, all with category=VALUE:
        CtrlUsCapState: type=APDT_CtrlUsCapState
        CmptUsCapState: type=APDT_CmptUsCapState
        LoadLevelState: type=APDT_LoadLevelState
        PPos: type=APDT_PPos
        SPos: type=APDT_SPos
        FlowRateEstim: type=APDT_FlowRateEstim
        CmptWorkMode: type=APDT_CmptWorkMode
    ARDT_HTPC_HpAcTpcp20
      4 x application record element, all with category=VALUE:
        CpType: type=APDT_CpType
        CpValueState: type=APDT_CpValueState
        CpWorkMode: type=APDT_CpWorkMode
        CpValue: type=APDT_CpValue
    ARDT_HTPC_HpBusActCtrlSet
      14 x application record element, all with category=STRUCTURE, type=ARDT_BusActCtrlSetElement:
        ExvAc0Ctrl
        ExcByPass1Ctrl
        ExvB2Ctrl
        ExvH3Ctrl
        Comp4Ctrl
        Erv1_5Ctrl
        Erv2_6Ctrl
        Erv3_7Ctrl
        null1_8
        null2_9
        AcSupport10
        IcdsSupport11
        ChSupport12
        OhxSupport13
    ARDT_HTPC_HpBusActStatus
      14 x application record element, all with category=STRUCTURE, type=ARDT_BusActStatusElement:
        ExvAc0St
        ExvByPass1St
        ExvB2St
        ExvH3St
        Comp4St
        Erv1_5St
        Erv2_6St
        Erv3_7St
        Null8
        Null9
        AcSupprt10St
        IcdsSupport11St
        ChSupport12St
        OhxSupport13St
    ARDT_HTPC_HpBusCmptModeResp
      application record element CurrentCmptMode: category=STRUCTURE, type=ARDT_BusCmptModeElement
      application record element NextCmptMode: category=STRUCTURE, type=ARDT_BusCmptModeElement
      application record element FailCmptMode: category=STRUCTURE, type=ARDT_BusCmptModeElement
    ARDT_HTPC_HpBusCpCtrlSet
      25 x application record element, all with category=STRUCTURE, type=ARDT_BusCpCtrlSetElement:
        CpCtrlSet0Ac
        CpCtrlSet1Icds
        CpCtrlSet2Ch
        CpCtrlSet3Ohx
        CpCtrlSet4TCompIn
        CpCtrlSet5TAcO
        CpCtrlSet6TIcdsO
        CpCtrlSet7TChO
        CpCtrlSet8TOhxO
        CpCtrlSet9TCompO
        CpCtrlSet10PAcO
        CpCtrlSet11PIcdsO
        CpCtrlSet12PChO
        CpCtrlSet13POhxO
        CpCtrlSet14PCompO
        CpCtrlSet15PCompIn
        CpCtrlSet16TOhxIn
        CpCtrlSet17POhxIn
        CpCtrlSet18OhxTpcpIn
        CpCtrlSet19CompTpcpIn
        CpCtrlSet20AcTpcp
        CpCtrlSet21IcdsTpcp
        CpCtrlSet22ChTpcp
        CpCtrlSet23OhxTpcp
        CpCtrlSet24CompTpcp
    ARDT_HTPC_HpBusCpSt
      25 x application record element, all with category=STRUCTURE, type=ARDT_BusCpStElement:
        CpSt0Ac
        CpSt1Icds
        CpSt2Ch
        CpSt3Ohx
        CpSt4TCompIn  # 20240515 Modify name
        CpSt5TAcO
        CpSt6TIcdsO
        CpSt7TChO
        CpSt8TOhxO
        CpSt9TCompO
        CpSt10PAcO
        CpSt11PIcdsO
        CpSt12PChO
        CpSt13POhxO
        CpSt14PCompO
        CpSt15PCompIn  # 20240515 Modify name
        CpSt16TOhxIn  # 20240515 Modify name
        CpSt17POhxIn  # 20240515 Modify name
        CpSt18OhxTpcpIn  # 20240515 Modify name
        CpSt19CompTpcpIn  # 20240515 Modify name
        CpSt20AcTpcp
        CpSt21IcdsTpcp
        CpSt22ChTpcp
        CpSt23OhxTpcp
        CpSt24CompTpcp
    ARDT_HTPC_HpBusTrpSet_Cmpt
      9 x application record element, all with category=STRUCTURE, type=ARDT_BusTrpSetElement:
        Trp{0..8}
    ARDT_HTPC_HpBusTrpSet_Ctrl
      9 x application record element, all with category=STRUCTURE, type=ARDT_BusTrpSetElement:
        Trp{0..8}
    ARDT_HTPC_HpBusTrpSet_Loop
      9 x application record element, all with category=STRUCTURE, type=ARDT_BusTrpSetElement:
        Trp{0..8}
    ARDT_HTPC_HpBusTrpSet_NBI
      9 x application record element, all with category=STRUCTURE, type=ARDT_BusTrpSetElement:
        Trp{0..8}
    ARDT_HTPC_HpBusTrpSet_Req
      9 x application record element, all with category=STRUCTURE, type=ARDT_BusTrpSetElement:
        Trp{0..8}
    ARDT_HTPC_HpBusTrpState
      9 x application record element, all with category=STRUCTURE, type=ARDT_BusTrpStateElement:
        TrpSt{0..8}
    ARDT_HTPC_HpChSensor2
      4 x application record element, all with category=VALUE:
        CpType: type=APDT_CpType
        CpValueState: type=APDT_CpValueState
        CpWorkMode: type=APDT_CpWorkMode
        CpValue: type=APDT_CpValue
    ARDT_HTPC_HpChSupportState
      7 x application record element, all with category=VALUE:
        CtrlUsCapState: type=APDT_CtrlUsCapState
        CmptUsCapState: type=APDT_CmptUsCapState
        LoadLevelState: type=APDT_LoadLevelState
        PPos: type=APDT_PPos
        SPos: type=APDT_SPos
        FlowRateEstim: type=APDT_FlowRateEstim
        CmptWorkMode: type=APDT_CmptWorkMode
    ARDT_HTPC_HpChTpcp22
      4 x application record element, all with category=VALUE:
        CpType: type=APDT_CpType
        CpValueState: type=APDT_CpValueState
        CpWorkMode: type=APDT_CpWorkMode
        CpValue: type=APDT_CpValue
    ARDT_HTPC_HpCompState
      7 x application record element, all with category=VALUE:
        CtrlUsCapState: type=APDT_CtrlUsCapState
        CmptUsCapState: type=APDT_CmptUsCapState
        LoadLevelState: type=APDT_LoadLevelState
        PPos: type=APDT_PPos
        SPos: type=APDT_SPos
        FlowRateEstim: type=APDT_FlowRateEstim
        CmptWorkMode: type=APDT_CmptWorkMode
    ARDT_HTPC_HpErv1State
      7 x application record element, all with category=VALUE:
        CtrlUsCapState: type=APDT_CtrlUsCapState
        CmptUsCapState: type=APDT_CmptUsCapState
        LoadLevelState: type=APDT_LoadLevelState
        PPos: type=APDT_PPos
        SPos: type=APDT_SPos
        FlowRateEstim: type=APDT_FlowRateEstim
        CmptWorkMode: type=APDT_CmptWorkMode
    ARDT_HTPC_HpErv2State
      7 x application record element, all with category=VALUE:
        CtrlUsCapState: type=APDT_CtrlUsCapState
        CmptUsCapState: type=APDT_CmptUsCapState
        LoadLevelState: type=APDT_LoadLevelState
        PPos: type=APDT_PPos
        SPos: type=APDT_SPos
        FlowRateEstim: type=APDT_FlowRateEstim
        CmptWorkMode: type=APDT_CmptWorkMode
    ARDT_HTPC_HpErv3State
      7 x application record element, all with category=VALUE:
        CtrlUsCapState: type=APDT_CtrlUsCapState
        CmptUsCapState: type=APDT_CmptUsCapState
        LoadLevelState: type=APDT_LoadLevelState
        PPos: type=APDT_PPos
        SPos: type=APDT_SPos
        FlowRateEstim: type=APDT_FlowRateEstim
        CmptWorkMode: type=APDT_CmptWorkMode
    ARDT_HTPC_HpExvAState
      7 x application record element, all with category=VALUE:
        CtrlUsCapState: type=APDT_CtrlUsCapState
        CmptUsCapState: type=APDT_CmptUsCapState
        LoadLevelState: type=APDT_LoadLevelState
        PPos: type=APDT_PPos
        SPos: type=APDT_SPos
        FlowRateEstim: type=APDT_FlowRateEstim
        CmptWorkMode: type=APDT_CmptWorkMode
    ARDT_HTPC_HpExvBState
      7 x application record element, all with category=VALUE:
        CtrlUsCapState: type=APDT_CtrlUsCapState
        CmptUsCapState: type=APDT_CmptUsCapState
        LoadLevelState: type=APDT_LoadLevelState
        PPos: type=APDT_PPos
        SPos: type=APDT_SPos
        FlowRateEstim: type=APDT_FlowRateEstim
        CmptWorkMode: type=APDT_CmptWorkMode
    ARDT_HTPC_HpExvByPassState
      7 x application record element, all with category=VALUE:
        CtrlUsCapState: type=APDT_CtrlUsCapState
        CmptUsCapState: type=APDT_CmptUsCapState
        LoadLevelState: type=APDT_LoadLevelState
        PPos: type=APDT_PPos
        SPos: type=APDT_SPos
        FlowRateEstim: type=APDT_FlowRateEstim
        CmptWorkMode: type=APDT_CmptWorkMode
    ARDT_HTPC_HpExvHState
      7 x application record element, all with category=VALUE:
        CtrlUsCapState: type=APDT_CtrlUsCapState
        CmptUsCapState: type=APDT_CmptUsCapState
        LoadLevelState: type=APDT_LoadLevelState
        PPos: type=APDT_PPos
        SPos: type=APDT_SPos
        FlowRateEstim: type=APDT_FlowRateEstim
        CmptWorkMode: type=APDT_CmptWorkMode
    ARDT_HTPC_HpIcdsSensor1
      4 x application record element, all with category=VALUE:
        CpType: type=APDT_CpType
        CpValueState: type=APDT_CpValueState
        CpWorkMode: type=APDT_CpWorkMode
        CpValue: type=APDT_CpValue
    ARDT_HTPC_HpIcdsSupportState
      7 x application record element, all with category=VALUE:
        CtrlUsCapState: type=APDT_CtrlUsCapState
        CmptUsCapState: type=APDT_CmptUsCapState
        LoadLevelState: type=APDT_LoadLevelState
        PPos: type=APDT_PPos
        SPos: type=APDT_SPos
        FlowRateEstim: type=APDT_FlowRateEstim
        CmptWorkMode: type=APDT_CmptWorkMode
    ARDT_HTPC_HpIcdsTpcp21
      4 x application record element, all with category=VALUE:
        CpType: type=APDT_CpType
        CpValueState: type=APDT_CpValueState
        CpWorkMode: type=APDT_CpWorkMode
        CpValue: type=APDT_CpValue
    ARDT_HTPC_HpOhxSensor3
      4 x application record element, all with category=VALUE:
        CpType: type=APDT_CpType
        CpValueState: type=APDT_CpValueState
        CpWorkMode: type=APDT_CpWorkMode
        CpValue: type=APDT_CpValue
    ARDT_HTPC_HpOhxSupportState
      7 x application record element, all with category=VALUE:
        CtrlUsCapState: type=APDT_CtrlUsCapState
        CmptUsCapState: type=APDT_CmptUsCapState
        LoadLevelState: type=APDT_LoadLevelState
        PPos: type=APDT_PPos
        SPos: type=APDT_SPos
        FlowRateEstim: type=APDT_FlowRateEstim
        CmptWorkMode: type=APDT_CmptWorkMode
    ARDT_HTPC_HpOhxTpcp18In
      4 x application record element, all with category=VALUE:
        CpType: type=APDT_CpType
        CpValueState: type=APDT_CpValueState
        CpWorkMode: type=APDT_CpWorkMode
        CpValue: type=APDT_CpValue
    ARDT_HTPC_HpOhxTpcp23
      4 x application record element, all with category=VALUE:
        CpType: type=APDT_CpType
        CpValueState: type=APDT_CpValueState
        CpWorkMode: type=APDT_CpWorkMode
        CpValue: type=APDT_CpValue
    ARDT_HTPC_HpOverallCycleStatus
      5 x application record element, all with category=VALUE:
        OverallCondenPwr: type=APDT_OverallCondenPwr
        OverallEvapPwr: type=APDT_OverallEvapPwr
        RefrigFlowVolEstim: type=APDT_RefrigFlowVolEstim
        RefrigLackStatus: type=APDT_RefrigLackStatus
        WorkMode: type=APDT_WorkMode
    ARDT_HTPC_ICDS
      application record element HTPC_tAirOutICoEstim: category=VALUE, type=APDT_HTPC_tAirOutICoEstim
    ARDT_HTPC_LoopDiversity
      4 x application record element, all with category=VALUE:
        Ext_stRefriTypCf1: type=APDT_Ext_stRefriTypCf1
        Ext_bHeatPmpCf1: type=APDT_Ext_bHeatPmpCf1
        Ext_tAirMes1: type=APDT_Ext_tAirMes1
        Ext_vehspd1: type=APDT_Ext_vehspd1
    ARDT_HTPC_NBI
      4 x application record element, all with category=VALUE:
        HTPC_pwrCndsEstim: type=APDT_HTPC_pwrCndsEstim
        HTPC_pwrEvapEstim: type=APDT_HTPC_pwrEvapEstim
        HTPC_stFctHeatPmp: type=APDT_HTPC_stFctHeatPmp
        HTPC_stOHXestim: type=APDT_HTPC_stOHXestim
    ARDT_HTPC_OHX
      application record element HTPC_bClsFSFReq: category=VALUE, type=APDT_HTPC_bClsFSFReq
      application record element HTPC_bDeicingReq: category=VALUE, type=APDT_HTPC_bDeicingReq
      application record element HTPC_spdAirCndSp: category=VALUE, type=APDT_HTPC_spdAirCndSp
    ARDT_HTPC_PAcO10
      4 x application record element, all with category=VALUE:
        CpType: type=APDT_CpType
        CpValueState: type=APDT_CpValueState
        CpWorkMode: type=APDT_CpWorkMode
        CpValue: type=APDT_CpValue
    ARDT_HTPC_PChO12
      4 x application record element, all with category=VALUE:
        CpType: type=APDT_CpType
        CpValueState: type=APDT_CpValueState
        CpWorkMode: type=APDT_CpWorkMode
        CpValue: type=APDT_CpValue
    ARDT_HTPC_PCompIn15
      4 x application record element, all with category=VALUE:
        CpType: type=APDT_CpType
        CpValueState: type=APDT_CpValueState
        CpWorkMode: type=APDT_CpWorkMode
        CpValue: type=APDT_CpValue
    ARDT_HTPC_PCompO14
      4 x application record element, all with category=VALUE:
        CpType: type=APDT_CpType
        CpValueState: type=APDT_CpValueState
        CpWorkMode: type=APDT_CpWorkMode
        CpValue: type=APDT_CpValue
    ARDT_HTPC_PIcdsO11
      4 x application record element, all with category=VALUE:
        CpType: type=APDT_CpType
        CpValueState: type=APDT_CpValueState
        CpWorkMode: type=APDT_CpWorkMode
        CpValue: type=APDT_CpValue
    ARDT_HTPC_POhxIn17
      4 x application record element, all with category=VALUE:
        CpType: type=APDT_CpType
        CpValueState: type=APDT_CpValueState
        CpWorkMode: type=APDT_CpWorkMode
        CpValue: type=APDT_CpValue
    ARDT_HTPC_POhxO13
      4 x application record element, all with category=VALUE:
        CpType: type=APDT_CpType
        CpValueState: type=APDT_CpValueState
        CpWorkMode: type=APDT_CpWorkMode
        CpValue: type=APDT_CpValue
    ARDT_HTPC_TAcO5
      4 x application record element, all with category=VALUE:
        CpType: type=APDT_CpType
        CpValueState: type=APDT_CpValueState
        CpWorkMode: type=APDT_CpWorkMode
        CpValue: type=APDT_CpValue
    ARDT_HTPC_TChO7
      4 x application record element, all with category=VALUE:
        CpType: type=APDT_CpType
        CpValueState: type=APDT_CpValueState
        CpWorkMode: type=APDT_CpWorkMode
        CpValue: type=APDT_CpValue
    ARDT_HTPC_TCompIn4
      4 x application record element, all with category=VALUE:
        CpType: type=APDT_CpType
        CpValueState: type=APDT_CpValueState
        CpWorkMode: type=APDT_CpWorkMode
        CpValue: type=APDT_CpValue
    ARDT_HTPC_TCompO9
      4 x application record element, all with category=VALUE:
        CpType: type=APDT_CpType
        CpValueState: type=APDT_CpValueState
        CpWorkMode: type=APDT_CpWorkMode
        CpValue: type=APDT_CpValue
    ARDT_HTPC_TIcdsO6
      4 x application record element, all with category=VALUE:
        CpType: type=APDT_CpType
        CpValueState: type=APDT_CpValueState
        CpWorkMode: type=APDT_CpWorkMode
        CpValue: type=APDT_CpValue
    ARDT_HTPC_TOhxIn16
      4 x application record element, all with category=VALUE:
        CpType: type=APDT_CpType
        CpValueState: type=APDT_CpValueState
        CpWorkMode: type=APDT_CpWorkMode
        CpValue: type=APDT_CpValue
    ARDT_HTPC_TOhxO8
      4 x application record element, all with category=VALUE:
        CpType: type=APDT_CpType
        CpValueState: type=APDT_CpValueState
        CpWorkMode: type=APDT_CpWorkMode
        CpValue: type=APDT_CpValue
    ARDT_HVEC2HTPC
      6 x application record element, all with category=VALUE:
        Ext_bPwrlimitCmpr: type=APDT_Ext_bPwrlimitCmpr
        Ext_bStallCmpr: type=APDT_Ext_bStallCmpr
        Ext_iCmpr: type=APDT_Ext_iCmpr
        Ext_nCmpr: type=APDT_Ext_nCmpr
        Ext_tInvCmpr: type=APDT_Ext_tInvCmpr
        Ext_uCmpr: type=APDT_Ext_uCmpr
    ARDT_HvecCmd
      application record element HTPC_bAcvCmprReq: category=VALUE, type=APDT_HTPC_bAcvCmprReq
      application record element HTPC_nCmprSp: category=VALUE, type=APDT_HTPC_nCmprSp
    ARDT_SUCRE
      15 x application record element, all with category=VALUE:
        SUCRE_bDeIcingAuthor: type=APDT_SUCRE_bDeIcingAuthor
        SUCRE_fintempsensor: type=APDT_SUCRE_fintempsensor
        SUCRE_nCmprMaxSp: type=APDT_SUCRE_nCmprMaxSp
        SUCRE_pwrCmprMaxSp: type=APDT_SUCRE_pwrCmprMaxSp
        SUCRE_pwrHVWHMaxSp: type=APDT_SUCRE_pwrHVWHMaxSp
        SUCRE_rHVWHAct: type=APDT_SUCRE_rHVWHAct
        SUCRE_stHeatPmpModReq: type=APDT_SUCRE_stHeatPmpModReq
        SUCRE_tAirOutEvapOfs: type=APDT_SUCRE_tAirOutEvapOfs
        SUCRE_tAirOutEvaSp: type=APDT_SUCRE_tAirOutEvaSp
        SUCRE_tAirOutICoSp: type=APDT_SUCRE_tAirOutICoSp
        SUCRE_tAirOutIEvaMes: type=APDT_SUCRE_tAirOutIEvaMes
        SUCRE_tWaOutChilMaxSp: type=APDT_SUCRE_tWaOutChilMaxSp
        SUCRE_tWaOutChilMes: type=APDT_SUCRE_tWaOutChilMes
        SUCRE_tWaOutChilMinSp: type=APDT_SUCRE_tWaOutChilMinSp
        SUCRE_tWaOutChilSp: type=APDT_SUCRE_tWaOutChilSp
package /DataTypes/BaseTypes
  sw addr method CODE: memory-allocation-keyword-policy=ADDR-METHOD-SHORT-NAME, section-type=CODE
package /DataTypes/ImplementationDataTypes
  236 x impl type:
    DT_AlertState: implementation-data-type=UInt8
    DT_AvailState: implementation-data-type=UInt8
    DT_CREPE_rOpFSF: implementation-data-type=UInt8
    DT_CREPE_spdAirEstim: implementation-data-type=SInt16
    DT_CREPE_tEstimWaInpChil: implementation-data-type=SInt16
    DT_CREPE_volfEstimWaChil: implementation-data-type=SInt16
    DT_ChPress: implementation-data-type=SInt16
    DT_ChTemp: implementation-data-type=SInt16
    DT_CmptMode: implementation-data-type=UInt8
    DT_CmptMode1: implementation-data-type=UInt8
    DT_CmptMode_AcSpport10_del: implementation-data-type=UInt8
    DT_CmptMode_ChSupport12_del: implementation-data-type=UInt8
    DT_CmptMode_Comp4: implementation-data-type=UInt8
    DT_CmptMode_Erv1_5: implementation-data-type=UInt8
    DT_CmptMode_Erv2_6: implementation-data-type=UInt8
    DT_CmptMode_Erv3_7: implementation-data-type=UInt8
    DT_CmptMode_ExvAc0: implementation-data-type=UInt8
    DT_CmptMode_ExvByPass1: implementation-data-type=UInt8
    DT_CmptMode_ExvCh2: implementation-data-type=UInt8
    DT_CmptMode_ExvOhx3: implementation-data-type=UInt8
    DT_CmptMode_IcdsSupport11: implementation-data-type=UInt8
    DT_CmptMode_Null8: implementation-data-type=UInt8
    DT_CmptMode_Null9: implementation-data-type=UInt8
    DT_CmptMode_OhxSupport13: implementation-data-type=UInt8
    DT_CmptUsCapState: implementation-data-type=UInt8
    DT_CmptWorkMode: implementation-data-type=UInt8
    DT_CompPress: implementation-data-type=SInt16
    DT_CompTemp: implementation-data-type=SInt16
    DT_CpId: implementation-data-type=UInt8
    DT_CpPara: implementation-data-type=UInt8
    DT_CpType: implementation-data-type=UInt8
    DT_CpValue: implementation-data-type=SInt16
    DT_CpValueState: implementation-data-type=UInt8
    DT_CpWorkMode: implementation-data-type=UInt8
    DT_CtrlMode: implementation-data-type=UInt8
    DT_CtrlUsCapState: implementation-data-type=UInt8
    DT_EVAPPress: implementation-data-type=SInt16
    DT_EVAPTemp: implementation-data-type=SInt16
    DT_Ext_bHeatPmpCf1: implementation-data-type=UInt8
    DT_Ext_bPwrlimitCmpr: implementation-data-type=Boolean
    DT_Ext_bStallCmpr: implementation-data-type=Boolean
    DT_Ext_iCmpr: implementation-data-type=SInt16
    DT_Ext_mfAirFanEvapEst: implementation-data-type=SInt16
    DT_Ext_mfAirFanICndsEst: implementation-data-type=SInt16
    DT_Ext_nCmpr: implementation-data-type=SInt16
    DT_Ext_rERV{1..3}Mes: implementation-data-type=UInt16
    DT_Ext_rEXV{1..4}Mes: implementation-data-type=UInt16
    DT_Ext_stERV{1..3}: implementation-data-type=UInt8
    DT_Ext_stEXV{1..4}: implementation-data-type=UInt8
    DT_Ext_stHeatPmpTypCf: implementation-data-type=UInt8
    DT_Ext_stRefriTypCf: implementation-data-type=UInt8
    DT_Ext_stRefriTypCf1: implementation-data-type=UInt8
    DT_Ext_tAirInpEvaEst: implementation-data-type=SInt16
    DT_Ext_tAirMes: implementation-data-type=SInt16
    DT_Ext_tAirMes1: implementation-data-type=SInt16
    DT_Ext_tInvCmpr: implementation-data-type=SInt16
    DT_Ext_typERV{1..3}: implementation-data-type=SInt16
    DT_Ext_typEXV{1..4}: implementation-data-type=SInt16
    DT_Ext_uCmpr: implementation-data-type=SInt16
    DT_Ext_vehspd: implementation-data-type=SInt16
    DT_Ext_vehspd1: implementation-data-type=SInt16
    DT_FlowRateEstim: implementation-data-type=SInt16
    DT_FullFilState: implementation-data-type=UInt8
    DT_HTPC_bAcvCmprReq: implementation-data-type=Boolean
    DT_HTPC_bClsFSFReq: implementation-data-type=Boolean
    DT_HTPC_bDeicingReq: implementation-data-type=UInt8
    DT_HTPC_bERV{1..3}InitReq: implementation-data-type=Boolean
    DT_HTPC_bEXV{1..4}InitReq: implementation-data-type=Boolean
    DT_HTPC_bHBoostReq: implementation-data-type=Boolean
    DT_HTPC_bspdCmprMaxLim: implementation-data-type=Boolean
    DT_HTPC_bspdCmprMinLim: implementation-data-type=Boolean
    DT_HTPC_nCmprSp: implementation-data-type=SInt16
    DT_HTPC_pwrCndsEstim: implementation-data-type=SInt16
    DT_HTPC_pwrEvapEstim: implementation-data-type=SInt16
    DT_HTPC_rERV{1..3}Req: implementation-data-type=UInt16
    DT_HTPC_rEXV{1..4}Req: implementation-data-type=UInt16
    DT_HTPC_rHVWHSp: implementation-data-type=UInt8
    DT_HTPC_spdAirCndSp: implementation-data-type=SInt16
    DT_HTPC_stFctHeatPmp: implementation-data-type=UInt8
    DT_HTPC_stOHXestim: implementation-data-type=UInt8
    DT_HTPC_tAirOutICoEstim: implementation-data-type=SInt16
    DT_HTPC_tWaChilInTrg: implementation-data-type=SInt16
    DT_HTPC_volfWaChilSp: implementation-data-type=SInt16
    DT_ICDSPress: implementation-data-type=SInt16
    DT_ICDSTemp: implementation-data-type=SInt16
    DT_LoadLevel: implementation-data-type=UInt8
    DT_LoadLevelState: implementation-data-type=UInt8
    DT_LoadPwrRuning: implementation-data-type=SInt16
    DT_NextMode: implementation-data-type=UInt8
    DT_NtfDevState: implementation-data-type=SInt16
    DT_NtfPosState: implementation-data-type=SInt16
    DT_NtfSensorState: implementation-data-type=SInt16
    DT_NtfSpdState: implementation-data-type=SInt16
    DT_OHXPress: implementation-data-type=SInt16
    DT_OHXTemp: implementation-data-type=SInt16
    DT_OverallCondenPwr: implementation-data-type=SInt16
    DT_OverallEvapPwr: implementation-data-type=SInt16
    DT_PPos: implementation-data-type=SInt16
    DT_PValue: implementation-data-type=SInt16
    DT_PidParaId: implementation-data-type=UInt8
    DT_PwrUpperLimit: implementation-data-type=SInt16
    DT_RefrigFlowVolEstim: implementation-data-type=SInt16
    DT_RefrigLackStatus: implementation-data-type=UInt8
    DT_ReqMode: implementation-data-type=UInt8
    DT_SMax: implementation-data-type=SInt16
    DT_SMin: implementation-data-type=SInt16
    DT_SPos: implementation-data-type=SInt16
    DT_SPosLowerLimit: implementation-data-type=SInt16
    DT_SPosUpperLimit: implementation-data-type=SInt16
    DT_SUCRE_bDeIcingAuthor: implementation-data-type=Boolean
    DT_SUCRE_fintempsensor: implementation-data-type=SInt16
    DT_SUCRE_nCmprMaxSp: implementation-data-type=SInt16
    DT_SUCRE_pwrCmprMaxSp: implementation-data-type=SInt16
    DT_SUCRE_pwrHVWHMaxSp: implementation-data-type=SInt16
    DT_SUCRE_rHVWHAct: implementation-data-type=UInt8
    DT_SUCRE_stHeatPmpModReq: implementation-data-type=UInt8
    DT_SUCRE_tAirOutEvaSp: implementation-data-type=SInt16
    DT_SUCRE_tAirOutEvapOfs: implementation-data-type=SInt16
    DT_SUCRE_tAirOutICoSp: implementation-data-type=SInt16
    DT_SUCRE_tAirOutIEvaMes: implementation-data-type=SInt16
    DT_SUCRE_tWaOutChilMaxSp: implementation-data-type=SInt16
    DT_SUCRE_tWaOutChilMes: implementation-data-type=SInt16
    DT_SUCRE_tWaOutChilMinSp: implementation-data-type=SInt16
    DT_SUCRE_tWaOutChilSp: implementation-data-type=SInt16
    DT_SValue: implementation-data-type=SInt16
    DT_TrpId: implementation-data-type=UInt8
    DT_UsCapState: implementation-data-type=UInt8
    DT_WorkMode: implementation-data-type=UInt8
    DT_WorkMode1: implementation-data-type=UInt8
    Dem_EventStatusType: compu {0x00=DEM_EVENT_STATUS_PASSED, 0x01=DEM_EVENT_STATUS_FAILED, 0x02=DEM_EVENT_STATUS_PREPASSED, 0x03=DEM_EVENT_STATUS_PREFAILED, 0x20=DEM_EVENT_STATUS_INIT}, range raw 0x00..0x20, implementation-data-type=UInt8
    RT_BusActCtrlSetElement: category=STRUCTURE
      8 x element, all with category=TYPE_REFERENCE:
        PidParaId: implementation-data-type=UInt8
        CtrlMode: implementation-data-type=UInt8
        TrpId: implementation-data-type=UInt8
        CpId: implementation-data-type=UInt8
        CmptMode: implementation-data-type=UInt8
        PwrUpperLimit: implementation-data-type=SInt16
        SPosUpperLimit: implementation-data-type=SInt16
        SPosLowerLimit: implementation-data-type=SInt16
    RT_BusActStatusElement: category=STRUCTURE
      7 x element, all with category=TYPE_REFERENCE:
        CtrlUsCapState: implementation-data-type=UInt8
        CmptUsCapState: implementation-data-type=UInt8
        LoadLevelState: implementation-data-type=UInt8
        PPos: implementation-data-type=SInt16
        SPos: implementation-data-type=SInt16
        FlowRateEstim: implementation-data-type=SInt16
        CmptWorkMode: implementation-data-type=UInt8
    RT_BusCmptModeElement: category=STRUCTURE
      14 x element, all with category=TYPE_REFERENCE, implementation-data-type=UInt8:
        CmptMode_ExvAc0
        CmptMode_ExvByPass1
        CmptMode_ExvCh2
        CmptMode_ExvOhx3
        CmptMode_Comp4
        CmptMode_Erv1_5
        CmptMode_Erv2_6
        CmptMode_Erv3_7
        CmptMode_Null8
        CmptMode_Null9
        CmptMode_AcSpport10_del
        CmptMode_IcdsSupport11
        CmptMode_ChSupport12_del
        CmptMode_OhxSupport13
    RT_BusCpCtrlSetElement: category=STRUCTURE
      element CmptMode1: implementation-data-type=UInt8
      element CpPara: implementation-data-type=UInt8
    RT_BusCpStElement: category=STRUCTURE
      4 x element, all with category=TYPE_REFERENCE:
        CpType: implementation-data-type=UInt8
        CpValueState: implementation-data-type=UInt8
        CpWorkMode: implementation-data-type=UInt8
        CpValue: implementation-data-type=SInt16
    RT_BusTrpSetElement: category=STRUCTURE
      5 x element, all with category=TYPE_REFERENCE:
        SValue: implementation-data-type=SInt16
        SMax: implementation-data-type=SInt16
        SMin: implementation-data-type=SInt16
        ReqMode: implementation-data-type=UInt8
        NextMode: implementation-data-type=UInt8
    RT_BusTrpStateElement: category=STRUCTURE
      8 x element, all with category=TYPE_REFERENCE:
        AlertState: implementation-data-type=UInt8
        AvailState: implementation-data-type=UInt8
        FullFilState: implementation-data-type=UInt8
        UsCapState: implementation-data-type=UInt8
        WorkMode1: implementation-data-type=UInt8
        LoadLevel: implementation-data-type=UInt8
        PValue: implementation-data-type=SInt16
        LoadPwrRuning: implementation-data-type=SInt16
    RT_CREPE: category=STRUCTURE
      4 x element, all with category=TYPE_REFERENCE:
        CREPE_rOpFSF: implementation-data-type=UInt8
        CREPE_spdAirEstim: implementation-data-type=SInt16
        CREPE_tEstimWaInpChil: implementation-data-type=SInt16
        CREPE_volfEstimWaChil: implementation-data-type=SInt16
    RT_ERV1Cmd: category=STRUCTURE
      element HTPC_bERV1InitReq: implementation-data-type=Boolean
      element HTPC_rERV1Req: implementation-data-type=UInt16
    RT_ERV1State: category=STRUCTURE
      element Ext_rERV1Mes: implementation-data-type=UInt16
      element Ext_stERV1: implementation-data-type=UInt8
      element Ext_typERV1: implementation-data-type=SInt16
    RT_ERV2Cmd: category=STRUCTURE
      element HTPC_bERV2InitReq: implementation-data-type=Boolean
      element HTPC_rERV2Req: implementation-data-type=UInt16
    RT_ERV2State: category=STRUCTURE
      element Ext_rERV2Mes: implementation-data-type=UInt16
      element Ext_stERV2: implementation-data-type=UInt8
      element Ext_typERV2: implementation-data-type=SInt16
    RT_ERV3Cmd: category=STRUCTURE
      element HTPC_bERV3InitReq: implementation-data-type=Boolean
      element HTPC_rERV3Req: implementation-data-type=UInt16
    RT_ERV3State: category=STRUCTURE
      element Ext_rERV3Mes: implementation-data-type=UInt16
      element Ext_stERV3: implementation-data-type=UInt8
      element Ext_typERV3: implementation-data-type=SInt16
    RT_EXV1Cmd: category=STRUCTURE
      element HTPC_bEXV1InitReq: implementation-data-type=Boolean
      element HTPC_rEXV1Req: implementation-data-type=UInt16
    RT_EXV1State: category=STRUCTURE
      element Ext_rEXV1Mes: implementation-data-type=UInt16
      element Ext_stEXV1: implementation-data-type=UInt8
      element Ext_typEXV1: implementation-data-type=SInt16
    RT_EXV2Cmd: category=STRUCTURE
      element HTPC_bEXV2InitReq: implementation-data-type=Boolean
      element HTPC_rEXV2Req: implementation-data-type=UInt16
    RT_EXV2State: category=STRUCTURE
      element Ext_rEXV2Mes: implementation-data-type=UInt16
      element Ext_stEXV2: implementation-data-type=UInt8
      element Ext_typEXV2: implementation-data-type=SInt16
    RT_EXV3Cmd: category=STRUCTURE
      element HTPC_bEXV3InitReq: implementation-data-type=Boolean
      element HTPC_rEXV3Req: implementation-data-type=UInt16
    RT_EXV3State: category=STRUCTURE
      element Ext_rEXV3Mes: implementation-data-type=UInt16
      element Ext_stEXV3: implementation-data-type=UInt8
      element Ext_typEXV3: implementation-data-type=SInt16
    RT_EXV4Cmd: category=STRUCTURE
      element HTPC_bEXV4InitReq: implementation-data-type=Boolean
      element HTPC_rEXV4Req: implementation-data-type=UInt16
    RT_EXV4State: category=STRUCTURE
      element Ext_rEXV4Mes: implementation-data-type=UInt16
      element Ext_stEXV4: implementation-data-type=UInt8
      element Ext_typEXV4: implementation-data-type=SInt16
    RT_Ext: category=STRUCTURE
      7 x element, all with category=TYPE_REFERENCE:
        Ext_mfAirFanEvapEst: implementation-data-type=SInt16
        Ext_mfAirFanICndsEst: implementation-data-type=SInt16
        Ext_stHeatPmpTypCf: implementation-data-type=UInt8
        Ext_stRefriTypCf: implementation-data-type=UInt8
        Ext_tAirInpEvaEst: implementation-data-type=SInt16
        Ext_tAirMes: implementation-data-type=SInt16
        Ext_vehspd: implementation-data-type=SInt16
    RT_HTPC_CH: category=STRUCTURE
      4 x element, all with category=TYPE_REFERENCE:
        HTPC_bHBoostReq: implementation-data-type=Boolean
        HTPC_rHVWHSp: implementation-data-type=UInt8
        HTPC_tWaChilInTrg: implementation-data-type=SInt16
        HTPC_volfWaChilSp: implementation-data-type=SInt16
    RT_HTPC_Comp: category=STRUCTURE
      element HTPC_bspdCmprMaxLim: implementation-data-type=Boolean
      element HTPC_bspdCmprMinLim: implementation-data-type=Boolean
    RT_HTPC_CompTpcp19In: category=STRUCTURE
      4 x element, all with category=TYPE_REFERENCE:
        CpType: implementation-data-type=UInt8
        CpValueState: implementation-data-type=UInt8
        CpWorkMode: implementation-data-type=UInt8
        CpValue: implementation-data-type=SInt16
    RT_HTPC_CompTpcp24: category=STRUCTURE
      4 x element, all with category=TYPE_REFERENCE:
        CpType: implementation-data-type=UInt8
        CpValueState: implementation-data-type=UInt8
        CpWorkMode: implementation-data-type=UInt8
        CpValue: implementation-data-type=SInt16
    RT_HTPC_HpAcSensor0: category=STRUCTURE
      4 x element, all with category=TYPE_REFERENCE:
        CpType: implementation-data-type=UInt8
        CpValueState: implementation-data-type=UInt8
        CpWorkMode: implementation-data-type=UInt8
        CpValue: implementation-data-type=SInt16
    RT_HTPC_HpAcSupportState: category=STRUCTURE
      7 x element, all with category=TYPE_REFERENCE:
        CtrlUsCapState: implementation-data-type=UInt8
        CmptUsCapState: implementation-data-type=UInt8
        LoadLevelState: implementation-data-type=UInt8
        PPos: implementation-data-type=SInt16
        SPos: implementation-data-type=SInt16
        FlowRateEstim: implementation-data-type=SInt16
        CmptWorkMode: implementation-data-type=UInt8
    RT_HTPC_HpAcTpcp20: category=STRUCTURE
      4 x element, all with category=TYPE_REFERENCE:
        CpType: implementation-data-type=UInt8
        CpValueState: implementation-data-type=UInt8
        CpWorkMode: implementation-data-type=UInt8
        CpValue: implementation-data-type=SInt16
    RT_HTPC_HpBusActCtrlSet: category=STRUCTURE
      14 x element, all with category=TYPE_REFERENCE, implementation-data-type=RT_BusActCtrlSetElement:
        ExvAc0Ctrl
        ExcByPass1Ctrl
        ExvB2Ctrl
        ExvH3Ctrl
        Comp4Ctrl
        Erv1_5Ctrl
        Erv2_6Ctrl
        Erv3_7Ctrl
        null1_8
        null2_9
        AcSupport10
        IcdsSupport11
        ChSupport12
        OhxSupport13
    RT_HTPC_HpBusActStatus: category=STRUCTURE
      14 x element, all with category=TYPE_REFERENCE, implementation-data-type=RT_BusActStatusElement:
        ExvAc0St
        ExvByPass1St
        ExvB2St
        ExvH3St
        Comp4St
        Erv1_5St
        Erv2_6St
        Erv3_7St
        Null8
        Null9
        AcSupprt10St
        IcdsSupport11St
        ChSupport12St
        OhxSupport13St
    RT_HTPC_HpBusCmptModeResp: category=STRUCTURE
      element CurrentCmptMode: implementation-data-type=RT_BusCmptModeElement
      element NextCmptMode: implementation-data-type=RT_BusCmptModeElement
      element FailCmptMode: implementation-data-type=RT_BusCmptModeElement
    RT_HTPC_HpBusCpCtrlSet: category=STRUCTURE
      25 x element, all with category=TYPE_REFERENCE, implementation-data-type=RT_BusCpCtrlSetElement:
        CpCtrlSet0Ac
        CpCtrlSet1Icds
        CpCtrlSet2Ch
        CpCtrlSet3Ohx
        CpCtrlSet4TCompIn
        CpCtrlSet5TAcO
        CpCtrlSet6TIcdsO
        CpCtrlSet7TChO
        CpCtrlSet8TOhxO
        CpCtrlSet9TCompO
        CpCtrlSet10PAcO
        CpCtrlSet11PIcdsO
        CpCtrlSet12PChO
        CpCtrlSet13POhxO
        CpCtrlSet14PCompO
        CpCtrlSet15PCompIn
        CpCtrlSet16TOhxIn
        CpCtrlSet17POhxIn
        CpCtrlSet18OhxTpcpIn
        CpCtrlSet19CompTpcpIn
        CpCtrlSet20AcTpcp
        CpCtrlSet21IcdsTpcp
        CpCtrlSet22ChTpcp
        CpCtrlSet23OhxTpcp
        CpCtrlSet24CompTpcp
    RT_HTPC_HpBusCpSt: category=STRUCTURE
      25 x element, all with category=TYPE_REFERENCE, implementation-data-type=RT_BusCpStElement:
        CpSt0Ac
        CpSt1Icds
        CpSt2Ch
        CpSt3Ohx
        CpSt4TCompIn
        CpSt5TAcO
        CpSt6TIcdsO
        CpSt7TChO
        CpSt8TOhxO
        CpSt9TCompO
        CpSt10PAcO
        CpSt11PIcdsO
        CpSt12PChO
        CpSt13POhxO
        CpSt14PCompO
        CpSt15PCompIn
        CpSt16TOhxIn
        CpSt17POhxIn
        CpSt18OhxTpcpIn
        CpSt19CompTpcpIn
        CpSt20AcTpcp
        CpSt21IcdsTpcp
        CpSt22ChTpcp
        CpSt23OhxTpcp
        CpSt24CompTpcp
    RT_HTPC_HpBusTrpSet_Cmpt: category=STRUCTURE
      9 x element, all with category=TYPE_REFERENCE, implementation-data-type=RT_BusTrpSetElement:
        Trp{0..8}
    RT_HTPC_HpBusTrpSet_Ctrl: category=STRUCTURE
      9 x element, all with category=TYPE_REFERENCE, implementation-data-type=RT_BusTrpSetElement:
        Trp{0..8}
    RT_HTPC_HpBusTrpSet_Loop: category=STRUCTURE
      9 x element, all with category=TYPE_REFERENCE, implementation-data-type=RT_BusTrpSetElement:
        Trp{0..8}
    RT_HTPC_HpBusTrpSet_NBI: category=STRUCTURE
      9 x element, all with category=TYPE_REFERENCE, implementation-data-type=RT_BusTrpSetElement:
        Trp{0..8}
    RT_HTPC_HpBusTrpSet_Req: category=STRUCTURE
      9 x element, all with category=TYPE_REFERENCE, implementation-data-type=RT_BusTrpSetElement:
        Trp{0..8}
    RT_HTPC_HpBusTrpState: category=STRUCTURE
      9 x element, all with category=TYPE_REFERENCE, implementation-data-type=RT_BusTrpStateElement:
        TrpSt{0..8}
    RT_HTPC_HpChSensor2: category=STRUCTURE
      4 x element, all with category=TYPE_REFERENCE:
        CpType: implementation-data-type=UInt8
        CpValueState: implementation-data-type=UInt8
        CpWorkMode: implementation-data-type=UInt8
        CpValue: implementation-data-type=SInt16
    RT_HTPC_HpChSupportState: category=STRUCTURE
      7 x element, all with category=TYPE_REFERENCE:
        CtrlUsCapState: implementation-data-type=UInt8
        CmptUsCapState: implementation-data-type=UInt8
        LoadLevelState: implementation-data-type=UInt8
        PPos: implementation-data-type=SInt16
        SPos: implementation-data-type=SInt16
        FlowRateEstim: implementation-data-type=SInt16
        CmptWorkMode: implementation-data-type=UInt8
    RT_HTPC_HpChTpcp22: category=STRUCTURE
      4 x element, all with category=TYPE_REFERENCE:
        CpType: implementation-data-type=UInt8
        CpValueState: implementation-data-type=UInt8
        CpWorkMode: implementation-data-type=UInt8
        CpValue: implementation-data-type=SInt16
    RT_HTPC_HpCompState: category=STRUCTURE
      7 x element, all with category=TYPE_REFERENCE:
        CtrlUsCapState: implementation-data-type=UInt8
        CmptUsCapState: implementation-data-type=UInt8
        LoadLevelState: implementation-data-type=UInt8
        PPos: implementation-data-type=SInt16
        SPos: implementation-data-type=SInt16
        FlowRateEstim: implementation-data-type=SInt16
        CmptWorkMode: implementation-data-type=UInt8
    RT_HTPC_HpErv1State: category=STRUCTURE
      7 x element, all with category=TYPE_REFERENCE:
        CtrlUsCapState: implementation-data-type=UInt8
        CmptUsCapState: implementation-data-type=UInt8
        LoadLevelState: implementation-data-type=UInt8
        PPos: implementation-data-type=SInt16
        SPos: implementation-data-type=SInt16
        FlowRateEstim: implementation-data-type=SInt16
        CmptWorkMode: implementation-data-type=UInt8
    RT_HTPC_HpErv2State: category=STRUCTURE
      7 x element, all with category=TYPE_REFERENCE:
        CtrlUsCapState: implementation-data-type=UInt8
        CmptUsCapState: implementation-data-type=UInt8
        LoadLevelState: implementation-data-type=UInt8
        PPos: implementation-data-type=SInt16
        SPos: implementation-data-type=SInt16
        FlowRateEstim: implementation-data-type=SInt16
        CmptWorkMode: implementation-data-type=UInt8
    RT_HTPC_HpErv3State: category=STRUCTURE
      7 x element, all with category=TYPE_REFERENCE:
        CtrlUsCapState: implementation-data-type=UInt8
        CmptUsCapState: implementation-data-type=UInt8
        LoadLevelState: implementation-data-type=UInt8
        PPos: implementation-data-type=SInt16
        SPos: implementation-data-type=SInt16
        FlowRateEstim: implementation-data-type=SInt16
        CmptWorkMode: implementation-data-type=UInt8
    RT_HTPC_HpExvAState: category=STRUCTURE
      7 x element, all with category=TYPE_REFERENCE:
        CtrlUsCapState: implementation-data-type=UInt8
        CmptUsCapState: implementation-data-type=UInt8
        LoadLevelState: implementation-data-type=UInt8
        PPos: implementation-data-type=SInt16
        SPos: implementation-data-type=SInt16
        FlowRateEstim: implementation-data-type=SInt16
        CmptWorkMode: implementation-data-type=UInt8
    RT_HTPC_HpExvBState: category=STRUCTURE
      7 x element, all with category=TYPE_REFERENCE:
        CtrlUsCapState: implementation-data-type=UInt8
        CmptUsCapState: implementation-data-type=UInt8
        LoadLevelState: implementation-data-type=UInt8
        PPos: implementation-data-type=SInt16
        SPos: implementation-data-type=SInt16
        FlowRateEstim: implementation-data-type=SInt16
        CmptWorkMode: implementation-data-type=UInt8
    RT_HTPC_HpExvByPassState: category=STRUCTURE
      7 x element, all with category=TYPE_REFERENCE:
        CtrlUsCapState: implementation-data-type=UInt8
        CmptUsCapState: implementation-data-type=UInt8
        LoadLevelState: implementation-data-type=UInt8
        PPos: implementation-data-type=SInt16
        SPos: implementation-data-type=SInt16
        FlowRateEstim: implementation-data-type=SInt16
        CmptWorkMode: implementation-data-type=UInt8
    RT_HTPC_HpExvHState: category=STRUCTURE
      7 x element, all with category=TYPE_REFERENCE:
        CtrlUsCapState: implementation-data-type=UInt8
        CmptUsCapState: implementation-data-type=UInt8
        LoadLevelState: implementation-data-type=UInt8
        PPos: implementation-data-type=SInt16
        SPos: implementation-data-type=SInt16
        FlowRateEstim: implementation-data-type=SInt16
        CmptWorkMode: implementation-data-type=UInt8
    RT_HTPC_HpIcdsSensor1: category=STRUCTURE
      4 x element, all with category=TYPE_REFERENCE:
        CpType: implementation-data-type=UInt8
        CpValueState: implementation-data-type=UInt8
        CpWorkMode: implementation-data-type=UInt8
        CpValue: implementation-data-type=SInt16
    RT_HTPC_HpIcdsSupportState: category=STRUCTURE
      7 x element, all with category=TYPE_REFERENCE:
        CtrlUsCapState: implementation-data-type=UInt8
        CmptUsCapState: implementation-data-type=UInt8
        LoadLevelState: implementation-data-type=UInt8
        PPos: implementation-data-type=SInt16
        SPos: implementation-data-type=SInt16
        FlowRateEstim: implementation-data-type=SInt16
        CmptWorkMode: implementation-data-type=UInt8
    RT_HTPC_HpIcdsTpcp21: category=STRUCTURE
      4 x element, all with category=TYPE_REFERENCE:
        CpType: implementation-data-type=UInt8
        CpValueState: implementation-data-type=UInt8
        CpWorkMode: implementation-data-type=UInt8
        CpValue: implementation-data-type=SInt16
    RT_HTPC_HpOhxSensor3: category=STRUCTURE
      4 x element, all with category=TYPE_REFERENCE:
        CpType: implementation-data-type=UInt8
        CpValueState: implementation-data-type=UInt8
        CpWorkMode: implementation-data-type=UInt8
        CpValue: implementation-data-type=SInt16
    RT_HTPC_HpOhxSupportState: category=STRUCTURE
      7 x element, all with category=TYPE_REFERENCE:
        CtrlUsCapState: implementation-data-type=UInt8
        CmptUsCapState: implementation-data-type=UInt8
        LoadLevelState: implementation-data-type=UInt8
        PPos: implementation-data-type=SInt16
        SPos: implementation-data-type=SInt16
        FlowRateEstim: implementation-data-type=SInt16
        CmptWorkMode: implementation-data-type=UInt8
    RT_HTPC_HpOhxTpcp18In: category=STRUCTURE
      4 x element, all with category=TYPE_REFERENCE:
        CpType: implementation-data-type=UInt8
        CpValueState: implementation-data-type=UInt8
        CpWorkMode: implementation-data-type=UInt8
        CpValue: implementation-data-type=SInt16
    RT_HTPC_HpOhxTpcp23: category=STRUCTURE
      4 x element, all with category=TYPE_REFERENCE:
        CpType: implementation-data-type=UInt8
        CpValueState: implementation-data-type=UInt8
        CpWorkMode: implementation-data-type=UInt8
        CpValue: implementation-data-type=SInt16
    RT_HTPC_HpOverallCycleStatus: category=STRUCTURE
      5 x element, all with category=TYPE_REFERENCE:
        OverallCondenPwr: implementation-data-type=SInt16
        OverallEvapPwr: implementation-data-type=SInt16
        RefrigFlowVolEstim: implementation-data-type=SInt16
        RefrigLackStatus: implementation-data-type=UInt8
        WorkMode: implementation-data-type=UInt8
    RT_HTPC_ICDS: category=STRUCTURE
      element HTPC_tAirOutICoEstim: implementation-data-type=SInt16
    RT_HTPC_LoopDiversity: category=STRUCTURE
      4 x element, all with category=TYPE_REFERENCE:
        Ext_stRefriTypCf1: implementation-data-type=UInt8
        Ext_bHeatPmpCf1: implementation-data-type=UInt8
        Ext_tAirMes1: implementation-data-type=SInt16
        Ext_vehspd1: implementation-data-type=SInt16
    RT_HTPC_NBI: category=STRUCTURE
      4 x element, all with category=TYPE_REFERENCE:
        HTPC_pwrCndsEstim: implementation-data-type=SInt16
        HTPC_pwrEvapEstim: implementation-data-type=SInt16
        HTPC_stFctHeatPmp: implementation-data-type=UInt8
        HTPC_stOHXestim: implementation-data-type=UInt8
    RT_HTPC_OHX: category=STRUCTURE
      element HTPC_bClsFSFReq: implementation-data-type=Boolean
      element HTPC_bDeicingReq: implementation-data-type=UInt8
      element HTPC_spdAirCndSp: implementation-data-type=SInt16
    RT_HTPC_PAcO10: category=STRUCTURE
      4 x element, all with category=TYPE_REFERENCE:
        CpType: implementation-data-type=UInt8
        CpValueState: implementation-data-type=UInt8
        CpWorkMode: implementation-data-type=UInt8
        CpValue: implementation-data-type=SInt16
    RT_HTPC_PChO12: category=STRUCTURE
      4 x element, all with category=TYPE_REFERENCE:
        CpType: implementation-data-type=UInt8
        CpValueState: implementation-data-type=UInt8
        CpWorkMode: implementation-data-type=UInt8
        CpValue: implementation-data-type=SInt16
    RT_HTPC_PCompIn15: category=STRUCTURE
      4 x element, all with category=TYPE_REFERENCE:
        CpType: implementation-data-type=UInt8
        CpValueState: implementation-data-type=UInt8
        CpWorkMode: implementation-data-type=UInt8
        CpValue: implementation-data-type=SInt16
    RT_HTPC_PCompO14: category=STRUCTURE
      4 x element, all with category=TYPE_REFERENCE:
        CpType: implementation-data-type=UInt8
        CpValueState: implementation-data-type=UInt8
        CpWorkMode: implementation-data-type=UInt8
        CpValue: implementation-data-type=SInt16
    RT_HTPC_PIcdsO11: category=STRUCTURE
      4 x element, all with category=TYPE_REFERENCE:
        CpType: implementation-data-type=UInt8
        CpValueState: implementation-data-type=UInt8
        CpWorkMode: implementation-data-type=UInt8
        CpValue: implementation-data-type=SInt16
    RT_HTPC_POhxIn17: category=STRUCTURE
      4 x element, all with category=TYPE_REFERENCE:
        CpType: implementation-data-type=UInt8
        CpValueState: implementation-data-type=UInt8
        CpWorkMode: implementation-data-type=UInt8
        CpValue: implementation-data-type=SInt16
    RT_HTPC_POhxO13: category=STRUCTURE
      4 x element, all with category=TYPE_REFERENCE:
        CpType: implementation-data-type=UInt8
        CpValueState: implementation-data-type=UInt8
        CpWorkMode: implementation-data-type=UInt8
        CpValue: implementation-data-type=SInt16
    RT_HTPC_TAcO5: category=STRUCTURE
      4 x element, all with category=TYPE_REFERENCE:
        CpType: implementation-data-type=UInt8
        CpValueState: implementation-data-type=UInt8
        CpWorkMode: implementation-data-type=UInt8
        CpValue: implementation-data-type=SInt16
    RT_HTPC_TChO7: category=STRUCTURE
      4 x element, all with category=TYPE_REFERENCE:
        CpType: implementation-data-type=UInt8
        CpValueState: implementation-data-type=UInt8
        CpWorkMode: implementation-data-type=UInt8
        CpValue: implementation-data-type=SInt16
    RT_HTPC_TCompIn4: category=STRUCTURE
      4 x element, all with category=TYPE_REFERENCE:
        CpType: implementation-data-type=UInt8
        CpValueState: implementation-data-type=UInt8
        CpWorkMode: implementation-data-type=UInt8
        CpValue: implementation-data-type=SInt16
    RT_HTPC_TCompO9: category=STRUCTURE
      4 x element, all with category=TYPE_REFERENCE:
        CpType: implementation-data-type=UInt8
        CpValueState: implementation-data-type=UInt8
        CpWorkMode: implementation-data-type=UInt8
        CpValue: implementation-data-type=SInt16
    RT_HTPC_TIcdsO6: category=STRUCTURE
      4 x element, all with category=TYPE_REFERENCE:
        CpType: implementation-data-type=UInt8
        CpValueState: implementation-data-type=UInt8
        CpWorkMode: implementation-data-type=UInt8
        CpValue: implementation-data-type=SInt16
    RT_HTPC_TOhxIn16: category=STRUCTURE
      4 x element, all with category=TYPE_REFERENCE:
        CpType: implementation-data-type=UInt8
        CpValueState: implementation-data-type=UInt8
        CpWorkMode: implementation-data-type=UInt8
        CpValue: implementation-data-type=SInt16
    RT_HTPC_TOhxO8: category=STRUCTURE
      4 x element, all with category=TYPE_REFERENCE:
        CpType: implementation-data-type=UInt8
        CpValueState: implementation-data-type=UInt8
        CpWorkMode: implementation-data-type=UInt8
        CpValue: implementation-data-type=SInt16
    RT_HVEC2HTPC: category=STRUCTURE
      6 x element, all with category=TYPE_REFERENCE:
        Ext_bPwrlimitCmpr: implementation-data-type=Boolean
        Ext_bStallCmpr: implementation-data-type=Boolean
        Ext_iCmpr: implementation-data-type=SInt16
        Ext_nCmpr: implementation-data-type=SInt16
        Ext_tInvCmpr: implementation-data-type=SInt16
        Ext_uCmpr: implementation-data-type=SInt16
    RT_HvecCmd: category=STRUCTURE
      element HTPC_bAcvCmprReq: implementation-data-type=Boolean
      element HTPC_nCmprSp: implementation-data-type=SInt16
    RT_SUCRE: category=STRUCTURE
      15 x element, all with category=TYPE_REFERENCE:
        SUCRE_bDeIcingAuthor: implementation-data-type=Boolean
        SUCRE_fintempsensor: implementation-data-type=SInt16
        SUCRE_nCmprMaxSp: implementation-data-type=SInt16
        SUCRE_pwrCmprMaxSp: implementation-data-type=SInt16
        SUCRE_pwrHVWHMaxSp: implementation-data-type=SInt16
        SUCRE_rHVWHAct: implementation-data-type=UInt8
        SUCRE_stHeatPmpModReq: implementation-data-type=UInt8
        SUCRE_tAirOutEvapOfs: implementation-data-type=SInt16
        SUCRE_tAirOutEvaSp: implementation-data-type=SInt16
        SUCRE_tAirOutICoSp: implementation-data-type=SInt16
        SUCRE_tAirOutIEvaMes: implementation-data-type=SInt16
        SUCRE_tWaOutChilMaxSp: implementation-data-type=SInt16
        SUCRE_tWaOutChilMes: implementation-data-type=SInt16
        SUCRE_tWaOutChilMinSp: implementation-data-type=SInt16
        SUCRE_tWaOutChilSp: implementation-data-type=SInt16
package /DataTypes/ModeManagement
  mode declaration group EcuM_Mode: initial-mode=STARTUP
    6 x mode:
      STARTUP
      RUN
      POST_RUN
      SLEEP
      WAKE_SLEEP
      SHUTDOWN
  mode declaration group RCD_stWkuMainRelSt: initial-mode=PreMainWakeUp
    4 x mode:
      PreMainWakeUp
      Invalid
      MainWakeUp
      PostMainWakeUp
package /DataTypes/Units
  unit psa_no_unit: factor-si-to-unit=1, offset-si-to-unit=0
package /SoftwareTypes/ComponentTypes
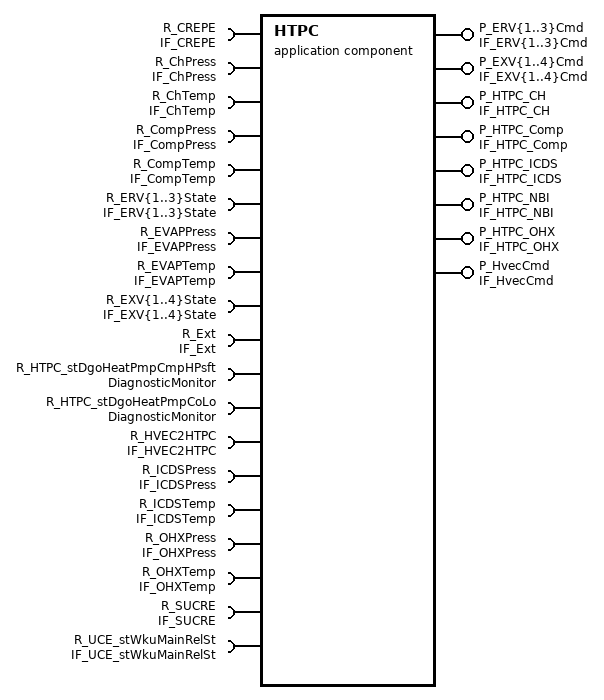
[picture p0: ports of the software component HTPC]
  application sw component type HTPC
    13 x provide port:
      P_ERV{1..3}Cmd: nonqueued-sender-com-spec{data-element=ERV{1..3}Cmd, init-value=constant-reference={short-label=IV_ERV{1..3}Cmd, constant=IV_ERV{1..3}Cmd}}, provided-interface=IF_ERV{1..3}Cmd
      P_EXV{1..4}Cmd: nonqueued-sender-com-spec{data-element=EXV{1..4}Cmd, init-value=constant-reference={short-label=IV_EXV{1..4}Cmd, constant=IV_EXV{1..4}Cmd}}, provided-interface=IF_EXV{1..4}Cmd
      P_HTPC_CH: nonqueued-sender-com-spec{data-element=HTPC_CH, init-value=constant-reference={short-label=IV_HTPC_CH, constant=IV_HTPC_CH}}, provided-interface=IF_HTPC_CH
      P_HTPC_Comp: nonqueued-sender-com-spec{data-element=HTPC_Comp, init-value=constant-reference={short-label=IV_HTPC_Comp, constant=IV_HTPC_Comp}}, provided-interface=IF_HTPC_Comp
      P_HTPC_ICDS: nonqueued-sender-com-spec{data-element=HTPC_ICDS, init-value=constant-reference={short-label=IV_HTPC_ICDS, constant=IV_HTPC_ICDS}}, provided-interface=IF_HTPC_ICDS
      P_HTPC_NBI: nonqueued-sender-com-spec{data-element=HTPC_NBI, init-value=constant-reference={short-label=IV_HTPC_NBI, constant=IV_HTPC_NBI}}, provided-interface=IF_HTPC_NBI
      P_HTPC_OHX: nonqueued-sender-com-spec{data-element=HTPC_OHX, init-value=constant-reference={short-label=IV_HTPC_CH, constant=IV_HTPC_OHX}}, provided-interface=IF_HTPC_OHX
      P_HvecCmd: nonqueued-sender-com-spec{data-element=HvecCmd, init-value=constant-reference={short-label=IV_HvecCmd, constant=IV_HvecCmd}}, provided-interface=IF_HvecCmd
    24 x require port:
      R_CREPE: nonqueued-receiver-com-spec{data-element=CREPE, init-value=constant-reference={short-label=IV_CREPE, constant=IV_CREPE}}, required-interface=IF_CREPE
      R_ChPress: nonqueued-receiver-com-spec{data-element=ChPress, init-value=constant-reference={short-label=IV_ChPress, constant=IV_ChPress}}, required-interface=IF_ChPress
      R_ChTemp: nonqueued-receiver-com-spec{data-element=ChTemp, init-value=constant-reference={short-label=IV_ChTemp, constant=IV_ChTemp}}, required-interface=IF_ChTemp
      R_CompPress: nonqueued-receiver-com-spec{data-element=CompPress, init-value=constant-reference={short-label=IV_CompPress, constant=IV_CompPress}}, required-interface=IF_CompPress  # NtfAcOPress
      R_CompTemp: nonqueued-receiver-com-spec{data-element=CompTemp, init-value=constant-reference={short-label=IV_CompTemp, constant=IV_CompTemp}}, required-interface=IF_CompTemp
      R_ERV{1..3}State: nonqueued-receiver-com-spec{data-element=ERV{1..3}State, init-value=constant-reference={short-label=IV_ERV{1..3}State, constant=IV_ERV{1..3}State}}, required-interface=IF_ERV{1..3}State
      R_EVAPPress: nonqueued-receiver-com-spec{data-element=EVAPPress, init-value=constant-reference={short-label=IV_EVAPPress, constant=IV_EVAPPress}}, required-interface=IF_EVAPPress
      R_EVAPTemp: nonqueued-receiver-com-spec{data-element=EVAPTemp, init-value=constant-reference={short-label=IV_EVAPTemp, constant=IV_EVAPTemp}}, required-interface=IF_EVAPTemp
      R_EXV{1..4}State: nonqueued-receiver-com-spec{data-element=EXV{1..4}State, init-value=constant-reference={short-label=IV_EXV{1..4}State, constant=IV_EXV{1..4}State}}, required-interface=IF_EXV{1..4}State
      R_Ext: nonqueued-receiver-com-spec{data-element=Ext, init-value=constant-reference={short-label=IV_Ext, constant=IV_Ext}}, required-interface=IF_Ext  # NBI_Ext
      R_HTPC_stDgoHeatPmpCmpHPsft: required-interface=DiagnosticMonitor
      R_HTPC_stDgoHeatPmpCoLo: required-interface=DiagnosticMonitor
      R_HVEC2HTPC: nonqueued-receiver-com-spec{data-element=HVEC2HTPC, init-value=constant-reference={short-label=IV_HVEC2HTPC, constant=IV_HVEC2HTPC}}, required-interface=IF_HVEC2HTPC
      R_ICDSPress: nonqueued-receiver-com-spec{data-element=ICDSPress, init-value=constant-reference={short-label=IV_ICDSPress, constant=IV_ICDSPress}}, required-interface=IF_ICDSPress
      R_ICDSTemp: nonqueued-receiver-com-spec{data-element=ICDSTemp, init-value=constant-reference={short-label=IV_ICDSTemp, constant=IV_ICDSTemp}}, required-interface=IF_ICDSTemp
      R_OHXPress: nonqueued-receiver-com-spec{data-element=OHXPress, init-value=constant-reference={short-label=IV_OHXPress, constant=IV_OHXPress}}, required-interface=IF_OHXPress
      R_OHXTemp: nonqueued-receiver-com-spec{data-element=OHXTemp, init-value=constant-reference={short-label=IV_OHXTemp, constant=IV_OHXTemp}}, required-interface=IF_OHXTemp
      R_SUCRE: nonqueued-receiver-com-spec{data-element=SUCRE, init-value=constant-reference={short-label=IV_SUCRE, constant=IV_SUCRE}}, required-interface=IF_SUCRE  # NBI_SUCRE
      R_UCE_stWkuMainRelSt: required-interface=IF_UCE_stWkuMainRelSt
    behavior IB_HTPC: data-type-mapping=[DTMS_APDT_AlertState, DTMS_APDT_AvailState, DTMS_APDT_CREPE_rOpFSF, DTMS_APDT_CREPE_spdAirEstim, DTMS_APDT_CREPE_tEstimWaInpChil, DTMS_APDT_CREPE_volfEstimWaChil, DTMS_APDT_ChPress, DTMS_APDT_ChTemp, DTMS_APDT_CmptMode, DTMS_APDT_CmptMode1, DTMS_APDT_CmptMode_AcSpport10_del, DTMS_APDT_CmptMode_ChSupport12_del, DTMS_APDT_CmptMode_Comp4, DTMS_APDT_CmptMode_Erv1_5, DTMS_APDT_CmptMode_Erv2_6, DTMS_APDT_CmptMode_Erv3_7, DTMS_APDT_CmptMode_ExvAc0, DTMS_APDT_CmptMode_ExvByPass1, DTMS_APDT_CmptMode_ExvCh2, DTMS_APDT_CmptMode_ExvOhx3, DTMS_APDT_CmptMode_IcdsSupport11, DTMS_APDT_CmptMode_Null8, DTMS_APDT_CmptMode_Null9, DTMS_APDT_CmptMode_OhxSupport13, DTMS_APDT_CmptUsCapState, DTMS_APDT_CmptWorkMode, DTMS_APDT_CompPress, DTMS_APDT_CompTemp, DTMS_APDT_CpId, DTMS_APDT_CpPara, DTMS_APDT_CpType, DTMS_APDT_CpValue, DTMS_APDT_CpValueState, DTMS_APDT_CpWorkMode, DTMS_APDT_CtrlMode, DTMS_APDT_CtrlUsCapState, DTMS_APDT_EVAPPress, DTMS_APDT_EVAPTemp, DTMS_APDT_Ext_bHeatPmpCf1, DTMS_APDT_Ext_bPwrlimitCmpr, DTMS_APDT_Ext_bStallCmpr, DTMS_APDT_Ext_iCmpr, DTMS_APDT_Ext_mfAirFanEvapEst, DTMS_APDT_Ext_mfAirFanICndsEst, DTMS_APDT_Ext_nCmpr, DTMS_APDT_Ext_rERV1Mes, DTMS_APDT_Ext_rERV2Mes, DTMS_APDT_Ext_rERV3Mes, DTMS_APDT_Ext_rEXV1Mes, DTMS_APDT_Ext_rEXV2Mes, DTMS_APDT_Ext_rEXV3Mes, DTMS_APDT_Ext_rEXV4Mes, DTMS_APDT_Ext_stERV1, DTMS_APDT_Ext_stERV2, DTMS_APDT_Ext_stERV3, DTMS_APDT_Ext_stEXV1, DTMS_APDT_Ext_stEXV2, DTMS_APDT_Ext_stEXV3, DTMS_APDT_Ext_stEXV4, DTMS_APDT_Ext_stHeatPmpTypCf, DTMS_APDT_Ext_stRefriTypCf, DTMS_APDT_Ext_stRefriTypCf1, DTMS_APDT_Ext_tAirInpEvaEst, DTMS_APDT_Ext_tAirMes, DTMS_APDT_Ext_tAirMes1, DTMS_APDT_Ext_tInvCmpr, DTMS_APDT_Ext_typERV1, DTMS_APDT_Ext_typERV2, DTMS_APDT_Ext_typERV3, DTMS_APDT_Ext_typEXV1, DTMS_APDT_Ext_typEXV2, DTMS_APDT_Ext_typEXV3, DTMS_APDT_Ext_typEXV4, DTMS_APDT_Ext_uCmpr, DTMS_APDT_Ext_vehspd, DTMS_APDT_Ext_vehspd1, DTMS_APDT_FlowRateEstim, DTMS_APDT_FullFilState, DTMS_APDT_HTPC_bAcvCmprReq, DTMS_APDT_HTPC_bClsFSFReq, DTMS_APDT_HTPC_bDeicingReq, DTMS_APDT_HTPC_bERV1InitReq, DTMS_APDT_HTPC_bERV2InitReq, DTMS_APDT_HTPC_bERV3InitReq, DTMS_APDT_HTPC_bEXV1InitReq, DTMS_APDT_HTPC_bEXV2InitReq, DTMS_APDT_HTPC_bEXV3InitReq, DTMS_APDT_HTPC_bEXV4InitReq, DTMS_APDT_HTPC_bHBoostReq, DTMS_APDT_HTPC_bspdCmprMaxLim, DTMS_APDT_HTPC_bspdCmprMinLim, DTMS_APDT_HTPC_nCmprSp, DTMS_APDT_HTPC_pwrCndsEstim, DTMS_APDT_HTPC_pwrEvapEstim, DTMS_APDT_HTPC_rERV1Req, DTMS_APDT_HTPC_rERV2Req, DTMS_APDT_HTPC_rERV3Req, DTMS_APDT_HTPC_rEXV1Req, DTMS_APDT_HTPC_rEXV2Req, DTMS_APDT_HTPC_rEXV3Req, DTMS_APDT_HTPC_rEXV4Req, DTMS_APDT_HTPC_rHVWHSp, DTMS_APDT_HTPC_spdAirCndSp, DTMS_APDT_HTPC_stFctHeatPmp, DTMS_APDT_HTPC_stOHXestim, DTMS_APDT_HTPC_tAirOutICoEstim, DTMS_APDT_HTPC_tWaChilInTrg, DTMS_APDT_HTPC_volfWaChilSp, DTMS_APDT_ICDSPress, DTMS_APDT_ICDSTemp, DTMS_APDT_LoadLevel, DTMS_APDT_LoadLevelState, DTMS_APDT_LoadPwrRuning, DTMS_APDT_NextMode, DTMS_APDT_NtfDevState, DTMS_APDT_NtfPosState, DTMS_APDT_NtfSensorState, DTMS_APDT_NtfSpdState, DTMS_APDT_OHXPress, DTMS_APDT_OHXTemp, DTMS_APDT_OverallCondenPwr, DTMS_APDT_OverallEvapPwr, DTMS_APDT_PPos, DTMS_APDT_PValue, DTMS_APDT_PidParaId, DTMS_APDT_PwrUpperLimit, DTMS_APDT_RefrigFlowVolEstim, DTMS_APDT_RefrigLackStatus, DTMS_APDT_ReqMode, DTMS_APDT_SMax, DTMS_APDT_SMin, DTMS_APDT_SPos, DTMS_APDT_SPosLowerLimit, DTMS_APDT_SPosUpperLimit, DTMS_APDT_SUCRE_bDeIcingAuthor, DTMS_APDT_SUCRE_fintempsensor, DTMS_APDT_SUCRE_nCmprMaxSp, DTMS_APDT_SUCRE_pwrCmprMaxSp, DTMS_APDT_SUCRE_pwrHVWHMaxSp, DTMS_APDT_SUCRE_rHVWHAct, DTMS_APDT_SUCRE_stHeatPmpModReq, DTMS_APDT_SUCRE_tAirOutEvaSp, DTMS_APDT_SUCRE_tAirOutEvapOfs, DTMS_APDT_SUCRE_tAirOutICoSp, DTMS_APDT_SUCRE_tAirOutIEvaMes, DTMS_APDT_SUCRE_tWaOutChilMaxSp, DTMS_APDT_SUCRE_tWaOutChilMes, DTMS_APDT_SUCRE_tWaOutChilMinSp, DTMS_APDT_SUCRE_tWaOutChilSp, DTMS_APDT_SValue, DTMS_APDT_TrpId, DTMS_APDT_UsCapState, DTMS_APDT_WorkMode, DTMS_APDT_WorkMode1, DTMS_ARDT_BusActCtrlSetElement, DTMS_ARDT_BusActStatusElement, DTMS_ARDT_BusCmptModeElement, DTMS_ARDT_BusCpCtrlSetElement, DTMS_ARDT_BusCpStElement, DTMS_ARDT_BusTrpSetElement, DTMS_ARDT_BusTrpStateElement, DTMS_ARDT_CREPE, DTMS_ARDT_ERV1Cmd, DTMS_ARDT_ERV1State, DTMS_ARDT_ERV2Cmd, DTMS_ARDT_ERV2State, DTMS_ARDT_ERV3Cmd, DTMS_ARDT_ERV3State, DTMS_ARDT_EXV1Cmd, DTMS_ARDT_EXV1State, DTMS_ARDT_EXV2Cmd, DTMS_ARDT_EXV2State, DTMS_ARDT_EXV3Cmd, DTMS_ARDT_EXV3State, DTMS_ARDT_EXV4Cmd, DTMS_ARDT_EXV4State, DTMS_ARDT_Ext, DTMS_ARDT_HTPC_CH, DTMS_ARDT_HTPC_Comp, DTMS_ARDT_HTPC_CompTpcp19In, DTMS_ARDT_HTPC_CompTpcp8, DTMS_ARDT_HTPC_HpAcSensor0, DTMS_ARDT_HTPC_HpAcSupportState, DTMS_ARDT_HTPC_HpAcTpcp4, DTMS_ARDT_HTPC_HpBusActCtrlSet, DTMS_ARDT_HTPC_HpBusActStatus, DTMS_ARDT_HTPC_HpBusCmptModeResp, DTMS_ARDT_HTPC_HpBusCpCtrlSet, DTMS_ARDT_HTPC_HpBusCpSt, DTMS_ARDT_HTPC_HpBusTrpSet_Cmpt, DTMS_ARDT_HTPC_HpBusTrpSet_Ctrl, DTMS_ARDT_HTPC_HpBusTrpSet_Loop, DTMS_ARDT_HTPC_HpBusTrpSet_NBI, DTMS_ARDT_HTPC_HpBusTrpSet_Req, DTMS_ARDT_HTPC_HpBusTrpState, DTMS_ARDT_HTPC_HpChSensor2, DTMS_ARDT_HTPC_HpChSupportState, DTMS_ARDT_HTPC_HpChTpcp6, DTMS_ARDT_HTPC_HpCompState, DTMS_ARDT_HTPC_HpErv1State, DTMS_ARDT_HTPC_HpErv2State, DTMS_ARDT_HTPC_HpErv3State, DTMS_ARDT_HTPC_HpExvAState, DTMS_ARDT_HTPC_HpExvBState, DTMS_ARDT_HTPC_HpExvByPassState, DTMS_ARDT_HTPC_HpExvHState, DTMS_ARDT_HTPC_HpIcdsSensor1, DTMS_ARDT_HTPC_HpIcdsSupportState, DTMS_ARDT_HTPC_HpIcdsTpcp5, DTMS_ARDT_HTPC_HpOhxSensor3, DTMS_ARDT_HTPC_HpOhxSupportState, DTMS_ARDT_HTPC_HpOhxTpcp18In, DTMS_ARDT_HTPC_HpOhxTpcp7, DTMS_ARDT_HTPC_HpOverallCycleStatus, DTMS_ARDT_HTPC_ICDS, DTMS_ARDT_HTPC_LoopDiversity, DTMS_ARDT_HTPC_NBI, DTMS_ARDT_HTPC_OHX, DTMS_ARDT_HTPC_PAcO20, DTMS_ARDT_HTPC_PChO22, DTMS_ARDT_HTPC_PCompIn15, DTMS_ARDT_HTPC_PCompO24, DTMS_ARDT_HTPC_PIcdsO21, DTMS_ARDT_HTPC_POhxIn17, DTMS_ARDT_HTPC_POhxO23, DTMS_ARDT_HTPC_TAcO10, DTMS_ARDT_HTPC_TChO12, DTMS_ARDT_HTPC_TCompIn4, DTMS_ARDT_HTPC_TCompO14, DTMS_ARDT_HTPC_TIcdsO11, DTMS_ARDT_HTPC_TOhxIn16, DTMS_ARDT_HTPC_TOhxO13, DTMS_ARDT_HVEC2HTPC, DTMS_ARDT_HvecCmd, DTMS_ARDT_SUCRE, DTMS_EcuM_Mode, DTMS_RCD_stWkuMainRelSt], handle-termination-and-restart=NO-SUPPORT
      init event EV_HTPC_000_TEV: start-on-event=RE_HTPC_000_TEV  # Init Event
      43 x timing event, all with disabled-mode=R_UCE_stWkuMainRelSt.RCD_stWkuMainRelSt.Invalid, period=1:
        EV_HTPC_001_TEV: start-on-event=RE_HTPC_001_TEV  # NBI
        EV_HTPC_100_TEV: start-on-event=RE_HTPC_100_TEV  # SyncAcSensor0
        EV_HTPC_101_TEV: start-on-event=RE_HTPC_101_TEV  # SyncIcdsSensor1
        EV_HTPC_102_TEV: start-on-event=RE_HTPC_102_TEV  # SyncChSensor2
        EV_HTPC_103_TEV: start-on-event=RE_HTPC_103_TEV  # SyncOhxSensor3
        EV_HTPC_104_TEV: start-on-event=RE_HTPC_104_TEV  # SyncTIcdsO
        EV_HTPC_105_TEV: start-on-event=RE_HTPC_105_TEV  # SyncTAcO
        EV_HTPC_106_TEV: start-on-event=RE_HTPC_106_TEV  # SyncTIcdsO
        EV_HTPC_107_TEV: start-on-event=RE_HTPC_107_TEV  # SyncTChO
        EV_HTPC_108_TEV: start-on-event=RE_HTPC_108_TEV  # SyncTOhxO
        EV_HTPC_109_TEV: start-on-event=RE_HTPC_109_TEV  # SyncTCompO
        EV_HTPC_110_TEV: start-on-event=RE_HTPC_110_TEV  # SyncPAcO
        EV_HTPC_111_TEV: start-on-event=RE_HTPC_111_TEV  # SyncPIcdsO
        EV_HTPC_112_TEV: start-on-event=RE_HTPC_112_TEV  # SyncPChO
        EV_HTPC_113_TEV: start-on-event=RE_HTPC_113_TEV  # SyncPOhxO
        EV_HTPC_114_TEV: start-on-event=RE_HTPC_114_TEV  # SyncPCompO
        EV_HTPC_115_TEV: start-on-event=RE_HTPC_115_TEV  # SyncIcdsSensor1
        EV_HTPC_116_TEV: start-on-event=RE_HTPC_116_TEV  # SyncChSensor2
        EV_HTPC_117_TEV: start-on-event=RE_HTPC_117_TEV  # SyncOhxSensor3
        EV_HTPC_118_TEV: start-on-event=RE_HTPC_118_TEV  # SyncAcSensor0
        EV_HTPC_119_TEV: start-on-event=RE_HTPC_119_TEV  # SyncTAcO
        EV_HTPC_120_TEV: start-on-event=RE_HTPC_120_TEV  # SyncAcTpcp4
        EV_HTPC_121_TEV: start-on-event=RE_HTPC_121_TEV  # SyncIcdsTpcp5
        EV_HTPC_122_TEV: start-on-event=RE_HTPC_122_TEV  # SyncChPttc
        EV_HTPC_123_TEV: start-on-event=RE_HTPC_123_TEV  # SyncOhxTpcp7
        EV_HTPC_124_TEV: start-on-event=RE_HTPC_124_TEV  # SyncCompTpcp8
        EV_HTPC_300_TEV: start-on-event=RE_HTPC_300_TEV  # CycleStatus
        EV_HTPC_410_TEV: start-on-event=RE_HTPC_410_TEV  # CalcHpReqMode
        EV_HTPC_420_TEV: start-on-event=RE_HTPC_420_TEV  # CalcHpLoopMode
        EV_HTPC_430_TEV: start-on-event=RE_HTPC_430_TEV  # CalcCmptMode
        EV_HTPC_440_TEV: start-on-event=RE_HTPC_440_TEV  # CalcCtrlMode
        EV_HTPC_600_TEV: start-on-event=RE_HTPC_600_TEV  # CtrlExvAcClcp
        EV_HTPC_601_TEV: start-on-event=RE_HTPC_601_TEV  # CtrlErv4
        EV_HTPC_602_TEV: start-on-event=RE_HTPC_602_TEV  # CtrlExvChClcp
        EV_HTPC_603_TEV: start-on-event=RE_HTPC_603_TEV  # CtrlExvOhxClcp
        EV_HTPC_604_TEV: start-on-event=RE_HTPC_604_TEV  # CtrlCompClcp
        EV_HTPC_605_TEV: start-on-event=RE_HTPC_605_TEV  # CtrlErv1
        EV_HTPC_606_TEV: start-on-event=RE_HTPC_606_TEV  # CtrlErv2
        EV_HTPC_607_TEV: start-on-event=RE_HTPC_607_TEV  # CtrlErv3
        EV_HTPC_610_TEV: start-on-event=RE_HTPC_610_TEV  # CtrlAcSupport
        EV_HTPC_611_TEV: start-on-event=RE_HTPC_611_TEV  # CtrlIcdsSupport
        EV_HTPC_612_TEV: start-on-event=RE_HTPC_612_TEV  # CtrlChSupport
        EV_HTPC_613_TEV: start-on-event=RE_HTPC_613_TEV  # CtrlOhxSupport
      explicit-inter-runnable-variables:
        50 x data, all with sw-calibration-access=READ-ONLY:
          HTPC_CompTpcp19In: type=ARDT_HTPC_CompTpcp19In, init-value={short-label=IV_HTPC_CompTpcpIn19, fields=[0, 0, 0, 0]}  # 20240516
          HTPC_CompTpcp24: type=ARDT_HTPC_CompTpcp24, init-value={short-label=IV_HTPC_CompTpcp24, fields=[0, 0, 0, 0]}
          HTPC_HpAcSensor0: type=ARDT_HTPC_HpAcSensor0, init-value={short-label=IV_HTPC_HpAcSensor0, fields=[0, 0, 0, 0]}  # HpAcSensor0
          HTPC_HpAcSupportState: type=ARDT_HTPC_HpAcSupportState, init-value={short-label=IV_HTPC_HpAcSupportState, fields=[0, 0, 0, 0, 0, 0, 0]}  # HpAcSupportState
          HTPC_HpAcTpcp20: type=ARDT_HTPC_HpAcTpcp20, init-value={short-label=IV_HTPC_HpAcTpcp20, fields=[0, 0, 0, 0]}
          HTPC_HpBusActCtrlSet: type=ARDT_HTPC_HpBusActCtrlSet, init-value={short-label=IV_HTPC_HpBusActCtrlSet, fields=[{short-label=DefaultInitValue_ARDT_BusActCtrlSetElement, fields=[0, 0, 0, 0, 0, 0, 0, 0]}, {short-label=DefaultInitValue_ARDT_BusActCtrlSetElement, fields=[0, 0, 0, 0, 0, 0, 0, 0]}, {short-label=DefaultInitValue_ARDT_BusActCtrlSetElement, fields=[0, 0, 0, 0, 0, 0, 0, 0]}, {short-label=DefaultInitValue_ARDT_BusActCtrlSetElement, fields=[0, 0, 0, 0, 0, 0, 0, 0]}, {short-label=DefaultInitValue_ARDT_BusActCtrlSetElement, fields=[0, 0, 0, 0, 0, 0, 0, 0]}, {short-label=DefaultInitValue_ARDT_BusActCtrlSetElement, fields=[0, 0, 0, 0, 0, 0, 0, 0]}, {short-label=DefaultInitValue_ARDT_BusActCtrlSetElement, fields=[0, 0, 0, 0, 0, 0, 0, 0]}, {short-label=DefaultInitValue_ARDT_BusActCtrlSetElement, fields=[0, 0, 0, 0, 0, 0, 0, 0]}, {short-label=DefaultInitValue_ARDT_BusActCtrlSetElement, fields=[0, 0, 0, 0, 0, 0, 0, 0]}, {short-label=DefaultInitValue_ARDT_BusActCtrlSetElement, fields=[0, 0, 0, 0, 0, 0, 0, 0]}, {short-label=DefaultInitValue_ARDT_BusActCtrlSetElement, fields=[0, 0, 0, 0, 0, 0, 0, 0]}, {short-label=DefaultInitValue_ARDT_BusActCtrlSetElement, fields=[0, 0, 0, 0, 0, 0, 0, 0]}, {short-label=DefaultInitValue_ARDT_BusActCtrlSetElement, fields=[0, 0, 0, 0, 0, 0, 0, 0]}, {short-label=DefaultInitValue_ARDT_BusActCtrlSetElement, fields=[0, 0, 0, 0, 0, 0, 0, 0]}]}
          HTPC_HpBusActStatus: type=ARDT_HTPC_HpBusActStatus, init-value={short-label=IV_HTPC_HpBusActStatus, fields=[{short-label=DefaultInitValue_ARDT_BusActStatusElement, fields=[0, 0, 0, 0, 0, 0, 0]}, {short-label=DefaultInitValue_ARDT_BusActStatusElement, fields=[0, 0, 0, 0, 0, 0, 0]}, {short-label=DefaultInitValue_ARDT_BusActStatusElement, fields=[0, 0, 0, 0, 0, 0, 0]}, {short-label=DefaultInitValue_ARDT_BusActStatusElement, fields=[0, 0, 0, 0, 0, 0, 0]}, {short-label=DefaultInitValue_ARDT_BusActStatusElement, fields=[0, 0, 0, 0, 0, 0, 0]}, {short-label=DefaultInitValue_ARDT_BusActStatusElement, fields=[0, 0, 0, 0, 0, 0, 0]}, {short-label=DefaultInitValue_ARDT_BusActStatusElement, fields=[0, 0, 0, 0, 0, 0, 0]}, {short-label=DefaultInitValue_ARDT_BusActStatusElement, fields=[0, 0, 0, 0, 0, 0, 0]}, {short-label=DefaultInitValue_ARDT_BusActStatusElement, fields=[0, 0, 0, 0, 0, 0, 0]}, {short-label=DefaultInitValue_ARDT_BusActStatusElement, fields=[0, 0, 0, 0, 0, 0, 0]}, {short-label=DefaultInitValue_ARDT_BusActStatusElement, fields=[0, 0, 0, 0, 0, 0, 0]}, {short-label=DefaultInitValue_ARDT_BusActStatusElement, fields=[0, 0, 0, 0, 0, 0, 0]}, {short-label=DefaultInitValue_ARDT_BusActStatusElement, fields=[0, 0, 0, 0, 0, 0, 0]}, {short-label=DefaultInitValue_ARDT_BusActStatusElement, fields=[0, 0, 0, 0, 0, 0, 0]}]}
          HTPC_HpBusCmptModeResp: type=ARDT_HTPC_HpBusCmptModeResp, init-value={short-label=IV_HTPC_HpBusCmptModeResp, fields=[{short-label=DefaultInitValue_ARDT_BusCmptModeElement, fields=[0, 0, 0, 0, 0, 0, 0, 0, 0, 0, 0, 0, 0, 0]}, {short-label=DefaultInitValue_ARDT_BusCmptModeElement, fields=[0, 0, 0, 0, 0, 0, 0, 0, 0, 0, 0, 0, 0, 0]}, {short-label=DefaultInitValue_ARDT_BusCmptModeElement, fields=[0, 0, 0, 0, 0, 0, 0, 0, 0, 0, 0, 0, 0, 0]}]}
          HTPC_HpBusCpCtrlSet: type=ARDT_HTPC_HpBusCpCtrlSet, init-value={short-label=IV_HTPC_HpBusCpCtrlSet, fields=[{short-label=DefaultInitValue_ARDT_BusCpCtrlSetElement, fields=[0, 0]}, {short-label=DefaultInitValue_ARDT_BusCpCtrlSetElement, fields=[0, 0]}, {short-label=DefaultInitValue_ARDT_BusCpCtrlSetElement, fields=[0, 0]}, {short-label=DefaultInitValue_ARDT_BusCpCtrlSetElement, fields=[0, 0]}, {short-label=DefaultInitValue_ARDT_BusCpCtrlSetElement, fields=[0, 0]}, {short-label=DefaultInitValue_ARDT_BusCpCtrlSetElement, fields=[0, 0]}, {short-label=DefaultInitValue_ARDT_BusCpCtrlSetElement, fields=[0, 0]}, {short-label=DefaultInitValue_ARDT_BusCpCtrlSetElement, fields=[0, 0]}, {short-label=DefaultInitValue_ARDT_BusCpCtrlSetElement, fields=[0, 0]}, {short-label=DefaultInitValue_ARDT_BusCpCtrlSetElement, fields=[0, 0]}, {short-label=DefaultInitValue_ARDT_BusCpCtrlSetElement, fields=[0, 0]}, {short-label=DefaultInitValue_ARDT_BusCpCtrlSetElement, fields=[0, 0]}, {short-label=DefaultInitValue_ARDT_BusCpCtrlSetElement, fields=[0, 0]}, {short-label=DefaultInitValue_ARDT_BusCpCtrlSetElement, fields=[0, 0]}, {short-label=DefaultInitValue_ARDT_BusCpCtrlSetElement, fields=[0, 0]}, {short-label=DefaultInitValue_ARDT_BusCpCtrlSetElement, fields=[0, 0]}, {short-label=DefaultInitValue_ARDT_BusCpCtrlSetElement, fields=[0, 0]}, {short-label=DefaultInitValue_ARDT_BusCpCtrlSetElement, fields=[0, 0]}, {short-label=DefaultInitValue_ARDT_BusCpCtrlSetElement, fields=[0, 0]}, {short-label=DefaultInitValue_ARDT_BusCpCtrlSetElement, fields=[0, 0]}, {short-label=DefaultInitValue_ARDT_BusCpCtrlSetElement, fields=[0, 0]}, {short-label=DefaultInitValue_ARDT_BusCpCtrlSetElement, fields=[0, 0]}, {short-label=DefaultInitValue_ARDT_BusCpCtrlSetElement, fields=[0, 0]}, {short-label=DefaultInitValue_ARDT_BusCpCtrlSetElement, fields=[0, 0]}, {short-label=DefaultInitValue_ARDT_BusCpCtrlSetElement, fields=[0, 0]}]}
          HTPC_HpBusCpSt: type=ARDT_HTPC_HpBusCpSt, init-value={short-label=IV_HTPC_HpBusCpSt, fields=[{short-label=DefaultInitValue_ARDT_BusCpStElement, fields=[0, 0, 0, 0]}, {short-label=DefaultInitValue_ARDT_BusCpStElement, fields=[0, 0, 0, 0]}, {short-label=DefaultInitValue_ARDT_BusCpStElement, fields=[0, 0, 0, 0]}, {short-label=DefaultInitValue_ARDT_BusCpStElement, fields=[0, 0, 0, 0]}, {short-label=DefaultInitValue_ARDT_BusCpStElement, fields=[0, 0, 0, 0]}, {short-label=DefaultInitValue_ARDT_BusCpStElement, fields=[0, 0, 0, 0]}, {short-label=DefaultInitValue_ARDT_BusCpStElement, fields=[0, 0, 0, 0]}, {short-label=DefaultInitValue_ARDT_BusCpStElement, fields=[0, 0, 0, 0]}, {short-label=DefaultInitValue_ARDT_BusCpStElement, fields=[0, 0, 0, 0]}, {short-label=DefaultInitValue_ARDT_BusCpStElement, fields=[0, 0, 0, 0]}, {short-label=DefaultInitValue_ARDT_BusCpStElement, fields=[0, 0, 0, 0]}, {short-label=DefaultInitValue_ARDT_BusCpStElement, fields=[0, 0, 0, 0]}, {short-label=DefaultInitValue_ARDT_BusCpStElement, fields=[0, 0, 0, 0]}, {short-label=DefaultInitValue_ARDT_BusCpStElement, fields=[0, 0, 0, 0]}, {short-label=DefaultInitValue_ARDT_BusCpStElement, fields=[0, 0, 0, 0]}, {short-label=DefaultInitValue_ARDT_BusCpStElement, fields=[0, 0, 0, 0]}, {short-label=DefaultInitValue_ARDT_BusCpStElement, fields=[0, 0, 0, 0]}, {short-label=DefaultInitValue_ARDT_BusCpStElement, fields=[0, 0, 0, 0]}, {short-label=DefaultInitValue_ARDT_BusCpStElement, fields=[0, 0, 0, 0]}, {short-label=DefaultInitValue_ARDT_BusCpStElement, fields=[0, 0, 0, 0]}, {short-label=DefaultInitValue_ARDT_BusCpStElement, fields=[0, 0, 0, 0]}, {short-label=DefaultInitValue_ARDT_BusCpStElement, fields=[0, 0, 0, 0]}, {short-label=DefaultInitValue_ARDT_BusCpStElement, fields=[0, 0, 0, 0]}, {short-label=DefaultInitValue_ARDT_BusCpStElement, fields=[0, 0, 0, 0]}, {short-label=DefaultInitValue_ARDT_BusCpStElement, fields=[0, 0, 0, 0]}]}
          HTPC_HpBusTrpSet_Cmpt: type=ARDT_HTPC_HpBusTrpSet_Cmpt, init-value={short-label=IV_HTPC_HpBusTrpSet_Cmpt, fields=[{short-label=DefaultInitValue_ARDT_BusTrpSetElement, fields=[0, 0, 0, 0, 0]}, {short-label=DefaultInitValue_ARDT_BusTrpSetElement, fields=[0, 0, 0, 0, 0]}, {short-label=DefaultInitValue_ARDT_BusTrpSetElement, fields=[0, 0, 0, 0, 0]}, {short-label=DefaultInitValue_ARDT_BusTrpSetElement, fields=[0, 0, 0, 0, 0]}, {short-label=DefaultInitValue_ARDT_BusTrpSetElement, fields=[0, 0, 0, 0, 0]}, {short-label=DefaultInitValue_ARDT_BusTrpSetElement, fields=[0, 0, 0, 0, 0]}, {short-label=DefaultInitValue_ARDT_BusTrpSetElement, fields=[0, 0, 0, 0, 0]}, {short-label=DefaultInitValue_ARDT_BusTrpSetElement, fields=[0, 0, 0, 0, 0]}, {short-label=DefaultInitValue_ARDT_BusTrpSetElement, fields=[0, 0, 0, 0, 0]}]}
          HTPC_HpBusTrpSet_Ctrl: type=ARDT_HTPC_HpBusTrpSet_Ctrl, init-value={short-label=IV_HTPC_HpBusTrpSet_Ctrl, fields=[{short-label=DefaultInitValue_ARDT_BusTrpSetElement, fields=[0, 0, 0, 0, 0]}, {short-label=DefaultInitValue_ARDT_BusTrpSetElement, fields=[0, 0, 0, 0, 0]}, {short-label=DefaultInitValue_ARDT_BusTrpSetElement, fields=[0, 0, 0, 0, 0]}, {short-label=DefaultInitValue_ARDT_BusTrpSetElement, fields=[0, 0, 0, 0, 0]}, {short-label=DefaultInitValue_ARDT_BusTrpSetElement, fields=[0, 0, 0, 0, 0]}, {short-label=DefaultInitValue_ARDT_BusTrpSetElement, fields=[0, 0, 0, 0, 0]}, {short-label=DefaultInitValue_ARDT_BusTrpSetElement, fields=[0, 0, 0, 0, 0]}, {short-label=DefaultInitValue_ARDT_BusTrpSetElement, fields=[0, 0, 0, 0, 0]}, {short-label=DefaultInitValue_ARDT_BusTrpSetElement, fields=[0, 0, 0, 0, 0]}]}
          HTPC_HpBusTrpSet_Loop: type=ARDT_HTPC_HpBusTrpSet_Loop, init-value={short-label=IV_HTPC_HpBusTrpSet_Loop, fields=[{short-label=DefaultInitValue_ARDT_BusTrpSetElement, fields=[0, 0, 0, 0, 0]}, {short-label=DefaultInitValue_ARDT_BusTrpSetElement, fields=[0, 0, 0, 0, 0]}, {short-label=DefaultInitValue_ARDT_BusTrpSetElement, fields=[0, 0, 0, 0, 0]}, {short-label=DefaultInitValue_ARDT_BusTrpSetElement, fields=[0, 0, 0, 0, 0]}, {short-label=DefaultInitValue_ARDT_BusTrpSetElement, fields=[0, 0, 0, 0, 0]}, {short-label=DefaultInitValue_ARDT_BusTrpSetElement, fields=[0, 0, 0, 0, 0]}, {short-label=DefaultInitValue_ARDT_BusTrpSetElement, fields=[0, 0, 0, 0, 0]}, {short-label=DefaultInitValue_ARDT_BusTrpSetElement, fields=[0, 0, 0, 0, 0]}, {short-label=DefaultInitValue_ARDT_BusTrpSetElement, fields=[0, 0, 0, 0, 0]}]}
          HTPC_HpBusTrpSet_NBI: type=ARDT_HTPC_HpBusTrpSet_NBI, init-value={short-label=IV_HTPC_HpBusTrpSet_NBI, fields=[{short-label=DefaultInitValue_ARDT_BusTrpSetElement, fields=[0, 0, 0, 0, 0]}, {short-label=DefaultInitValue_ARDT_BusTrpSetElement, fields=[0, 0, 0, 0, 0]}, {short-label=DefaultInitValue_ARDT_BusTrpSetElement, fields=[0, 0, 0, 0, 0]}, {short-label=DefaultInitValue_ARDT_BusTrpSetElement, fields=[0, 0, 0, 0, 0]}, {short-label=DefaultInitValue_ARDT_BusTrpSetElement, fields=[0, 0, 0, 0, 0]}, {short-label=DefaultInitValue_ARDT_BusTrpSetElement, fields=[0, 0, 0, 0, 0]}, {short-label=DefaultInitValue_ARDT_BusTrpSetElement, fields=[0, 0, 0, 0, 0]}, {short-label=DefaultInitValue_ARDT_BusTrpSetElement, fields=[0, 0, 0, 0, 0]}, {short-label=DefaultInitValue_ARDT_BusTrpSetElement, fields=[0, 0, 0, 0, 0]}]}
          HTPC_HpBusTrpSet_Req: type=ARDT_HTPC_HpBusTrpSet_Req, init-value={short-label=IV_HTPC_HpBusTrpSet_Req, fields=[{short-label=DefaultInitValue_ARDT_BusTrpSetElement, fields=[0, 0, 0, 0, 0]}, {short-label=DefaultInitValue_ARDT_BusTrpSetElement, fields=[0, 0, 0, 0, 0]}, {short-label=DefaultInitValue_ARDT_BusTrpSetElement, fields=[0, 0, 0, 0, 0]}, {short-label=DefaultInitValue_ARDT_BusTrpSetElement, fields=[0, 0, 0, 0, 0]}, {short-label=DefaultInitValue_ARDT_BusTrpSetElement, fields=[0, 0, 0, 0, 0]}, {short-label=DefaultInitValue_ARDT_BusTrpSetElement, fields=[0, 0, 0, 0, 0]}, {short-label=DefaultInitValue_ARDT_BusTrpSetElement, fields=[0, 0, 0, 0, 0]}, {short-label=DefaultInitValue_ARDT_BusTrpSetElement, fields=[0, 0, 0, 0, 0]}, {short-label=DefaultInitValue_ARDT_BusTrpSetElement, fields=[0, 0, 0, 0, 0]}]}
          HTPC_HpBusTrpState: type=ARDT_HTPC_HpBusTrpState, init-value={short-label=IV_HTPC_HpBusTrpState, fields=[{short-label=DefaultInitValue_ARDT_BusTrpStateElement, fields=[0, 0, 0, 0, 0, 0, 0, 0]}, {short-label=DefaultInitValue_ARDT_BusTrpStateElement, fields=[0, 0, 0, 0, 0, 0, 0, 0]}, {short-label=DefaultInitValue_ARDT_BusTrpStateElement, fields=[0, 0, 0, 0, 0, 0, 0, 0]}, {short-label=DefaultInitValue_ARDT_BusTrpStateElement, fields=[0, 0, 0, 0, 0, 0, 0, 0]}, {short-label=DefaultInitValue_ARDT_BusTrpStateElement, fields=[0, 0, 0, 0, 0, 0, 0, 0]}, {short-label=DefaultInitValue_ARDT_BusTrpStateElement, fields=[0, 0, 0, 0, 0, 0, 0, 0]}, {short-label=DefaultInitValue_ARDT_BusTrpStateElement, fields=[0, 0, 0, 0, 0, 0, 0, 0]}, {short-label=DefaultInitValue_ARDT_BusTrpStateElement, fields=[0, 0, 0, 0, 0, 0, 0, 0]}, {short-label=DefaultInitValue_ARDT_BusTrpStateElement, fields=[0, 0, 0, 0, 0, 0, 0, 0]}]}
          HTPC_HpChSensor2: type=ARDT_HTPC_HpChSensor2, init-value={short-label=IV_HTPC_HpChSensor2, fields=[0, 0, 0, 0]}
          HTPC_HpChSupportState: type=ARDT_HTPC_HpChSupportState, init-value={short-label=IV_HTPC_HpChSupportState, fields=[0, 0, 0, 0, 0, 0, 0]}
          HTPC_HpChTpcp22: type=ARDT_HTPC_HpChTpcp22, init-value={short-label=IV_HTPC_HpChTpcp22, fields=[0, 0, 0, 0]}
          HTPC_HpCompState: type=ARDT_HTPC_HpCompState, init-value={short-label=IV_HTPC_HpCompState, fields=[0, 0, 0, 0, 0, 0, 0]}
          HTPC_HpErv{1..3}State: type=ARDT_HTPC_HpErv{1..3}State, init-value={short-label=IV_HTPC_HpErv{1..3}State, fields=[0, 0, 0, 0, 0, 0, 0]}
          HTPC_HpExvAState: type=ARDT_HTPC_HpExvAState, init-value={short-label=IV_HTPC_HpExvAState, fields=[0, 0, 0, 0, 0, 0, 0]}
          HTPC_HpExvBState: type=ARDT_HTPC_HpExvBState, init-value={short-label=IV_HTPC_HpExvBState, fields=[0, 0, 0, 0, 0, 0, 0]}
          HTPC_HpExvByPassState: type=ARDT_HTPC_HpExvByPassState, init-value={short-label=IV_HTPC_HpExvByPassState, fields=[0, 0, 0, 0, 0, 0, 0]}
          HTPC_HpExvHState: type=ARDT_HTPC_HpExvHState, init-value={short-label=IV_HTPC_HpExvHState, fields=[0, 0, 0, 0, 0, 0, 0]}
          HTPC_HpIcdsSensor1: type=ARDT_HTPC_HpIcdsSensor1, init-value={short-label=IV_HTPC_HpIcdsSensor1, fields=[0, 0, 0, 0]}
          HTPC_HpIcdsSupportState: type=ARDT_HTPC_HpIcdsSupportState, init-value={short-label=IV_HTPC_HpIcdsSupportState, fields=[0, 0, 0, 0, 0, 0, 0]}
          HTPC_HpIcdsTpcp21: type=ARDT_HTPC_HpIcdsTpcp21, init-value={short-label=IV_HTPC_HpIcdsTpcp21, fields=[0, 0, 0, 0]}
          HTPC_HpOhxSensor3: type=ARDT_HTPC_HpOhxSensor3, init-value={short-label=IV_HTPC_HpOhxSensor3, fields=[0, 0, 0, 0]}
          HTPC_HpOhxSupportState: type=ARDT_HTPC_HpOhxSupportState, init-value={short-label=IV_HTPC_HpOhxSupportState, fields=[0, 0, 0, 0, 0, 0, 0]}
          HTPC_HpOhxTpcp18In: type=ARDT_HTPC_HpOhxTpcp18In, init-value={short-label=IV_HTPC_HpOhxTpcpIn18, fields=[0, 0, 0, 0]}  # 20240516
          HTPC_HpOhxTpcp23: type=ARDT_HTPC_HpOhxTpcp23, init-value={short-label=IV_HTPC_HpOhxTpcp23, fields=[0, 0, 0, 0]}
          HTPC_HpOverallCycleStatus: type=ARDT_HTPC_HpOverallCycleStatus, init-value={short-label=IV_HTPC_HpOverallCycleStatus, fields=[0, 0, 0, 0, 0]}
          HTPC_LoopDiversity: type=ARDT_HTPC_LoopDiversity, init-value={short-label=IV_HTPC_LoopDiversity, fields=[0, 0, 0, 0]}
          HTPC_PAcO10: type=ARDT_HTPC_PAcO10, init-value={short-label=IV_HTPC_PAcO10, fields=[0, 0, 0, 0]}
          HTPC_PChO12: type=ARDT_HTPC_PChO12, init-value={short-label=IV_HTPC_PChO12, fields=[0, 0, 0, 0]}
          HTPC_PCompIn15: type=ARDT_HTPC_PCompIn15, init-value={short-label=IV_HTPC_PCompIn15, fields=[0, 0, 0, 0]}  # 20240516
          HTPC_PCompO14: type=ARDT_HTPC_PCompO14, init-value={short-label=IV_HTPC_PCompO14, fields=[0, 0, 0, 0]}
          HTPC_PIcdsO11: type=ARDT_HTPC_PIcdsO11, init-value={short-label=IV_HTPC_PIcdsO11, fields=[0, 0, 0, 0]}
          HTPC_POhxIn17: type=ARDT_HTPC_POhxIn17, init-value={short-label=IV_HTPC_POhxIn17, fields=[0, 0, 0, 0]}  # 20240516
          HTPC_POhxO13: type=ARDT_HTPC_POhxO13, init-value={short-label=IV_HTPC_POhxO13, fields=[0, 0, 0, 0]}
          HTPC_TAcO5: type=ARDT_HTPC_TAcO5, init-value={short-label=IV_HTPC_TAcO5, fields=[0, 0, 0, 0]}
          HTPC_TChO7: type=ARDT_HTPC_TChO7, init-value={short-label=IV_HTPC_TChO7, fields=[0, 0, 0, 0]}
          HTPC_TCompIn4: type=ARDT_HTPC_TCompIn4, init-value={short-label=IV_HTPC_TCompIn4, fields=[0, 0, 0, 0]}  # 20240516
          HTPC_TCompO9: type=ARDT_HTPC_TCompO9, init-value={short-label=IV_HTPC_TCompO9, fields=[0, 0, 0, 0]}
          HTPC_TIcdsO6: type=ARDT_HTPC_TIcdsO6, init-value={short-label=IV_HTPC_TIcdsO6, fields=[0, 0, 0, 0]}
          HTPC_TOhxIn16: type=ARDT_HTPC_TOhxIn16, init-value={short-label=IV_HTPC_TOhxIn16, fields=[0, 0, 0, 0]}  # 20040516
          HTPC_TOhxO8: type=ARDT_HTPC_TOhxO8, init-value={short-label=IV_HTPC_TOhxO8, fields=[0, 0, 0, 0]}
      44 x runnable, all with sw-addr-method=CODE:
        RE_HTPC_000_TEV  # Init
        RE_HTPC_001_TEV  # NBI
          data-receive-point-by-arguments:
            access dr_Ext: accessed-variable=R_Ext.Ext
            access dr_SUCRE: accessed-variable=R_SUCRE.SUCRE
          data-send-points:
            access ds_HTPC_NBI: accessed-variable=P_HTPC_NBI.HTPC_NBI
          read-local-variables:
            access HTPC_HpBusTrpState: accessed-variable=HTPC_HpBusTrpState
            access HTPC_HpOverallCycleStatus: accessed-variable=HTPC_HpOverallCycleStatus
          sync call sc_SetEventStatus: operation=R_HTPC_stDgoHeatPmpCmpHPsft.SetEventStatus, timeout=0
          written-local-variables:
            access HTPC_HpBusTrpSet_NBI: accessed-variable=HTPC_HpBusTrpSet_NBI
            access HTPC_LoopDiversity: accessed-variable=HTPC_LoopDiversity
        RE_HTPC_100_TEV  # SyncAcSensor0
          data-receive-point-by-arguments:
            access dr_SUCRE: accessed-variable=R_SUCRE.SUCRE
          read-local-variables:
            4 x access:
              HTPC_HpBusCpCtrlSet: accessed-variable=HTPC_HpBusCpCtrlSet
              HTPC_HpBusCpSt: accessed-variable=HTPC_HpBusCpSt
              HTPC_HpBusTrpState: accessed-variable=HTPC_HpBusTrpState
              HTPC_LoopDiversity: accessed-variable=HTPC_LoopDiversity
          sync call sc_SetEventStatus: operation=R_HTPC_stDgoHeatPmpCmpHPsft.SetEventStatus, timeout=0
          written-local-variables:
            access HTPC_HpAcSensor0: accessed-variable=HTPC_HpAcSensor0
        RE_HTPC_101_TEV  # SyncIcdsSensor1
          data-receive-point-by-arguments:
            access dr_SUCRE: accessed-variable=R_SUCRE.SUCRE
          data-send-points:
            access ds_HTPC_ICDS: accessed-variable=P_HTPC_ICDS.HTPC_ICDS
          read-local-variables:
            4 x access:
              HTPC_HpBusCpCtrlSet: accessed-variable=HTPC_HpBusCpCtrlSet
              HTPC_HpBusCpSt: accessed-variable=HTPC_HpBusCpSt
              HTPC_HpBusTrpState: accessed-variable=HTPC_HpBusTrpState
              HTPC_LoopDiversity: accessed-variable=HTPC_LoopDiversity
          sync call sc_SetEventStatus: operation=R_HTPC_stDgoHeatPmpCmpHPsft.SetEventStatus, timeout=0
          written-local-variables:
            access HTPC_HpIcdsSensor1: accessed-variable=HTPC_HpIcdsSensor1
        RE_HTPC_102_TEV  # SyncChSensor2
          data-receive-point-by-arguments:
            access dr_SUCRE: accessed-variable=R_SUCRE.SUCRE
          read-local-variables:
            4 x access:
              HTPC_HpBusCpCtrlSet: accessed-variable=HTPC_HpBusCpCtrlSet
              HTPC_HpBusCpSt: accessed-variable=HTPC_HpBusCpSt
              HTPC_HpBusTrpState: accessed-variable=HTPC_HpBusTrpState
              HTPC_LoopDiversity: accessed-variable=HTPC_LoopDiversity
          sync call sc_SetEventStatus: operation=R_HTPC_stDgoHeatPmpCmpHPsft.SetEventStatus, timeout=0
          written-local-variables:
            access HTPC_HpChSensor2: accessed-variable=HTPC_HpChSensor2
        RE_HTPC_103_TEV  # SyncOhxSensor3
          data-receive-point-by-arguments:
            access dr_Ext: accessed-variable=R_Ext.Ext
          read-local-variables:
            4 x access:
              HTPC_HpBusCpCtrlSet: accessed-variable=HTPC_HpBusCpCtrlSet
              HTPC_HpBusCpSt: accessed-variable=HTPC_HpBusCpSt
              HTPC_HpBusTrpState: accessed-variable=HTPC_HpBusTrpState
              HTPC_LoopDiversity: accessed-variable=HTPC_LoopDiversity
          sync call sc_SetEventStatus: operation=R_HTPC_stDgoHeatPmpCmpHPsft.SetEventStatus, timeout=0
          written-local-variables:
            access HTPC_HpOhxSensor3: accessed-variable=HTPC_HpOhxSensor3
        RE_HTPC_104_TEV  # SyncTCompIn 20240516
          data-receive-point-by-arguments:
            access dr_CompTemp: accessed-variable=R_CompTemp.CompTemp
          read-local-variables:
            4 x access:
              HTPC_HpBusCpCtrlSet: accessed-variable=HTPC_HpBusCpCtrlSet
              HTPC_HpBusCpSt: accessed-variable=HTPC_HpBusCpSt
              HTPC_HpBusTrpState: accessed-variable=HTPC_HpBusTrpState
              HTPC_LoopDiversity: accessed-variable=HTPC_LoopDiversity
          sync call sc_SetEventStatus: operation=R_HTPC_stDgoHeatPmpCmpHPsft.SetEventStatus, timeout=0
          written-local-variables:
            access HTPC_TCompIn4: accessed-variable=HTPC_TCompIn4
        RE_HTPC_105_TEV  # SyncTAcO
          data-receive-point-by-arguments:
            access dr_EVAPTemp: accessed-variable=R_EVAPTemp.EVAPTemp
          read-local-variables:
            4 x access:
              HTPC_HpBusCpCtrlSet: accessed-variable=HTPC_HpBusCpCtrlSet
              HTPC_HpBusCpSt: accessed-variable=HTPC_HpBusCpSt
              HTPC_HpBusTrpState: accessed-variable=HTPC_HpBusTrpState
              HTPC_LoopDiversity: accessed-variable=HTPC_LoopDiversity
          sync call sc_SetEventStatus: operation=R_HTPC_stDgoHeatPmpCmpHPsft.SetEventStatus, timeout=0
          written-local-variables:
            access HTPC_TAcO5: accessed-variable=HTPC_TAcO5
        RE_HTPC_106_TEV  # SyncTIcdsO
          data-receive-point-by-arguments:
            access dr_ICDSTemp: accessed-variable=R_ICDSTemp.ICDSTemp
          read-local-variables:
            4 x access:
              HTPC_HpBusCpCtrlSet: accessed-variable=HTPC_HpBusCpCtrlSet
              HTPC_HpBusCpSt: accessed-variable=HTPC_HpBusCpSt
              HTPC_HpBusTrpState: accessed-variable=HTPC_HpBusTrpState
              HTPC_LoopDiversity: accessed-variable=HTPC_LoopDiversity
          sync call sc_SetEventStatus: operation=R_HTPC_stDgoHeatPmpCmpHPsft.SetEventStatus, timeout=0
          written-local-variables:
            access HTPC_TIcdsO6: accessed-variable=HTPC_TIcdsO6
        RE_HTPC_107_TEV  # SyncTChO
          data-receive-point-by-arguments:
            access dr_ChTemp: accessed-variable=R_ChTemp.ChTemp
          read-local-variables:
            4 x access:
              HTPC_HpBusCpCtrlSet: accessed-variable=HTPC_HpBusCpCtrlSet
              HTPC_HpBusCpSt: accessed-variable=HTPC_HpBusCpSt
              HTPC_HpBusTrpState: accessed-variable=HTPC_HpBusTrpState
              HTPC_LoopDiversity: accessed-variable=HTPC_LoopDiversity
          sync call sc_SetEventStatus: operation=R_HTPC_stDgoHeatPmpCmpHPsft.SetEventStatus, timeout=0
          written-local-variables:
            access HTPC_TChO7: accessed-variable=HTPC_TChO7
        RE_HTPC_108_TEV  # SyncTOhxO
          data-receive-point-by-arguments:
            access dr_OHXTemp: accessed-variable=R_OHXTemp.OHXTemp
          read-local-variables:
            4 x access:
              HTPC_HpBusCpCtrlSet: accessed-variable=HTPC_HpBusCpCtrlSet
              HTPC_HpBusCpSt: accessed-variable=HTPC_HpBusCpSt
              HTPC_HpBusTrpState: accessed-variable=HTPC_HpBusTrpState
              HTPC_LoopDiversity: accessed-variable=HTPC_LoopDiversity
          sync call sc_SetEventStatus: operation=R_HTPC_stDgoHeatPmpCmpHPsft.SetEventStatus, timeout=0
          written-local-variables:
            access HTPC_TOhxO8: accessed-variable=HTPC_TOhxO8
        RE_HTPC_109_TEV  # SyncTCompO
          data-receive-point-by-arguments:
            access dr_CompTemp: accessed-variable=R_CompTemp.CompTemp
          read-local-variables:
            4 x access:
              HTPC_HpBusCpCtrlSet: accessed-variable=HTPC_HpBusCpCtrlSet
              HTPC_HpBusCpSt: accessed-variable=HTPC_HpBusCpSt
              HTPC_HpBusTrpState: accessed-variable=HTPC_HpBusTrpState
              HTPC_LoopDiversity: accessed-variable=HTPC_LoopDiversity
          sync call sc_SetEventStatus: operation=R_HTPC_stDgoHeatPmpCmpHPsft.SetEventStatus, timeout=0
          written-local-variables:
            access HTPC_TCompO9: accessed-variable=HTPC_TCompO9
        RE_HTPC_110_TEV  # SyncPAcO
          data-receive-point-by-arguments:
            access dr_EVAPPress: accessed-variable=R_EVAPPress.EVAPPress
            access dr_EVAPTemp: accessed-variable=R_EVAPTemp.EVAPTemp
          read-local-variables:
            4 x access:
              HTPC_HpBusCpCtrlSet: accessed-variable=HTPC_HpBusCpCtrlSet
              HTPC_HpBusCpSt: accessed-variable=HTPC_HpBusCpSt
              HTPC_HpBusTrpState: accessed-variable=HTPC_HpBusTrpState
              HTPC_LoopDiversity: accessed-variable=HTPC_LoopDiversity
          sync call sc_SetEventStatus: operation=R_HTPC_stDgoHeatPmpCmpHPsft.SetEventStatus, timeout=0
          written-local-variables:
            access HTPC_PAcO10: accessed-variable=HTPC_PAcO10
        RE_HTPC_111_TEV  # SyncPIcdsO
          data-receive-point-by-arguments:
            access dr_ICDSPress: accessed-variable=R_ICDSPress.ICDSPress
            access dr_ICDSTemp: accessed-variable=R_ICDSTemp.ICDSTemp
          read-local-variables:
            4 x access:
              HTPC_HpBusCpCtrlSet: accessed-variable=HTPC_HpBusCpCtrlSet
              HTPC_HpBusCpSt: accessed-variable=HTPC_HpBusCpSt
              HTPC_HpBusTrpState: accessed-variable=HTPC_HpBusTrpState
              HTPC_LoopDiversity: accessed-variable=HTPC_LoopDiversity
          sync call sc_SetEventStatus: operation=R_HTPC_stDgoHeatPmpCmpHPsft.SetEventStatus, timeout=0
          written-local-variables:
            access HTPC_PIcdsO11: accessed-variable=HTPC_PIcdsO11
        RE_HTPC_112_TEV  # SyncPChO
          data-receive-point-by-arguments:
            access dr_ChPress: accessed-variable=R_ChPress.ChPress
            access dr_ChTemp: accessed-variable=R_ChTemp.ChTemp
          read-local-variables:
            4 x access:
              HTPC_HpBusCpCtrlSet: accessed-variable=HTPC_HpBusCpCtrlSet
              HTPC_HpBusCpSt: accessed-variable=HTPC_HpBusCpSt
              HTPC_HpBusTrpState: accessed-variable=HTPC_HpBusTrpState
              HTPC_LoopDiversity: accessed-variable=HTPC_LoopDiversity
          sync call sc_SetEventStatus: operation=R_HTPC_stDgoHeatPmpCmpHPsft.SetEventStatus, timeout=0
          written-local-variables:
            access HTPC_PChO12: accessed-variable=HTPC_PChO12
        RE_HTPC_113_TEV  # SyncPOhxO
          data-receive-point-by-arguments:
            access dr_OHXPress: accessed-variable=R_OHXPress.OHXPress
            access dr_OHXTemp: accessed-variable=R_OHXTemp.OHXTemp
          read-local-variables:
            4 x access:
              HTPC_HpBusCpCtrlSet: accessed-variable=HTPC_HpBusCpCtrlSet
              HTPC_HpBusCpSt: accessed-variable=HTPC_HpBusCpSt
              HTPC_HpBusTrpState: accessed-variable=HTPC_HpBusTrpState
              HTPC_LoopDiversity: accessed-variable=HTPC_LoopDiversity
          sync call sc_SetEventStatus: operation=R_HTPC_stDgoHeatPmpCmpHPsft.SetEventStatus, timeout=0
          written-local-variables:
            access HTPC_POhxO13: accessed-variable=HTPC_POhxO13
        RE_HTPC_114_TEV  # SyncPCompO
          data-receive-point-by-arguments:
            access dr_CompPress: accessed-variable=R_CompPress.CompPress
            access dr_CompTemp: accessed-variable=R_CompTemp.CompTemp
          read-local-variables:
            4 x access:
              HTPC_HpBusCpCtrlSet: accessed-variable=HTPC_HpBusCpCtrlSet
              HTPC_HpBusCpSt: accessed-variable=HTPC_HpBusCpSt
              HTPC_HpBusTrpState: accessed-variable=HTPC_HpBusTrpState
              HTPC_LoopDiversity: accessed-variable=HTPC_LoopDiversity
          sync call sc_SetEventStatus: operation=R_HTPC_stDgoHeatPmpCmpHPsft.SetEventStatus, timeout=0
          written-local-variables:
            access HTPC_PCompO14: accessed-variable=HTPC_PCompO14
        RE_HTPC_115_TEV  # SyncPCompIn 20240516
          data-receive-point-by-arguments:
            access dr_CompPress: accessed-variable=R_CompPress.CompPress
            access dr_CompTemp: accessed-variable=R_CompTemp.CompTemp
          read-local-variables:
            4 x access:
              HTPC_HpBusCpCtrlSet: accessed-variable=HTPC_HpBusCpCtrlSet
              HTPC_HpBusCpSt: accessed-variable=HTPC_HpBusCpSt
              HTPC_HpBusTrpState: accessed-variable=HTPC_HpBusTrpState
              HTPC_LoopDiversity: accessed-variable=HTPC_LoopDiversity
          sync call sc_SetEventStatus: operation=R_HTPC_stDgoHeatPmpCmpHPsft.SetEventStatus, timeout=0
          written-local-variables:
            access HTPC_PCompIn15: accessed-variable=HTPC_PCompIn15
        RE_HTPC_116_TEV  # SyncTOhxIn 20140516
          data-receive-point-by-arguments:
            access dr_OHXTemp: accessed-variable=R_OHXTemp.OHXTemp
          read-local-variables:
            4 x access:
              HTPC_HpBusCpCtrlSet: accessed-variable=HTPC_HpBusCpCtrlSet
              HTPC_HpBusCpSt: accessed-variable=HTPC_HpBusCpSt
              HTPC_HpBusTrpState: accessed-variable=HTPC_HpBusTrpState
              HTPC_LoopDiversity: accessed-variable=HTPC_LoopDiversity
          sync call sc_SetEventStatus: operation=R_HTPC_stDgoHeatPmpCmpHPsft.SetEventStatus, timeout=0
          written-local-variables:
            access HTPC_TOhxIn16: accessed-variable=HTPC_TOhxIn16
        RE_HTPC_117_TEV  # SyncPOhxIn 20240516
          data-receive-point-by-arguments:
            access dr_OHXPress: accessed-variable=R_OHXPress.OHXPress
            access dr_OHXTemp: accessed-variable=R_OHXTemp.OHXTemp
          read-local-variables:
            4 x access:
              HTPC_HpBusCpCtrlSet: accessed-variable=HTPC_HpBusCpCtrlSet
              HTPC_HpBusCpSt: accessed-variable=HTPC_HpBusCpSt
              HTPC_HpBusTrpState: accessed-variable=HTPC_HpBusTrpState
              HTPC_LoopDiversity: accessed-variable=HTPC_LoopDiversity
          sync call sc_SetEventStatus: operation=R_HTPC_stDgoHeatPmpCmpHPsft.SetEventStatus, timeout=0
          written-local-variables:
            access HTPC_POhxIn17: accessed-variable=HTPC_POhxIn17
        RE_HTPC_118_TEV  # SyncOhxTpcpIn 20240516
          read-local-variables:
            6 x access:
              HTPC_HpBusCpCtrlSet: accessed-variable=HTPC_HpBusCpCtrlSet
              HTPC_HpBusCpSt: accessed-variable=HTPC_HpBusCpSt
              HTPC_HpBusTrpState: accessed-variable=HTPC_HpBusTrpState
              HTPC_LoopDiversity: accessed-variable=HTPC_LoopDiversity
              HTPC_POhxIn17: accessed-variable=HTPC_POhxIn17
              HTPC_TOhxIn16: accessed-variable=HTPC_TOhxIn16
          sync call sc_SetEventStatus: operation=R_HTPC_stDgoHeatPmpCmpHPsft.SetEventStatus, timeout=0
          written-local-variables:
            access HTPC_HpOhxTpcp18In: accessed-variable=HTPC_HpOhxTpcp18In
        RE_HTPC_119_TEV  # SyncCompTpcpIn 20240516
          read-local-variables:
            6 x access:
              HTPC_HpBusCpCtrlSet: accessed-variable=HTPC_HpBusCpCtrlSet
              HTPC_HpBusCpSt: accessed-variable=HTPC_HpBusCpSt
              HTPC_HpBusTrpState: accessed-variable=HTPC_HpBusTrpState
              HTPC_LoopDiversity: accessed-variable=HTPC_LoopDiversity
              HTPC_PCompIn15: accessed-variable=HTPC_PCompIn15
              HTPC_TCompIn4: accessed-variable=HTPC_TCompIn4
          sync call sc_SetEventStatus: operation=R_HTPC_stDgoHeatPmpCmpHPsft.SetEventStatus, timeout=0
          written-local-variables:
            access HTPC_CompTpcp19In: accessed-variable=HTPC_CompTpcp19In
        RE_HTPC_120_TEV  # SyncAcTpcp
          read-local-variables:
            6 x access:
              HTPC_HpBusCpCtrlSet: accessed-variable=HTPC_HpBusCpCtrlSet
              HTPC_HpBusCpSt: accessed-variable=HTPC_HpBusCpSt
              HTPC_HpBusTrpState: accessed-variable=HTPC_HpBusTrpState
              HTPC_LoopDiversity: accessed-variable=HTPC_LoopDiversity
              HTPC_PAcO10: accessed-variable=HTPC_PAcO10
              HTPC_TAcO5: accessed-variable=HTPC_TAcO5
          sync call sc_SetEventStatus: operation=R_HTPC_stDgoHeatPmpCmpHPsft.SetEventStatus, timeout=0
          written-local-variables:
            access HTPC_HpAcTpcp20: accessed-variable=HTPC_HpAcTpcp20
        RE_HTPC_121_TEV  # SyncIcdsTpcp
          read-local-variables:
            6 x access:
              HTPC_HpBusCpCtrlSet: accessed-variable=HTPC_HpBusCpCtrlSet
              HTPC_HpBusCpSt: accessed-variable=HTPC_HpBusCpSt
              HTPC_HpBusTrpState: accessed-variable=HTPC_HpBusTrpState
              HTPC_LoopDiversity: accessed-variable=HTPC_LoopDiversity
              HTPC_PIcdsO11: accessed-variable=HTPC_PIcdsO11
              HTPC_TIcdsO6: accessed-variable=HTPC_TIcdsO6
          sync call sc_SetEventStatus: operation=R_HTPC_stDgoHeatPmpCmpHPsft.SetEventStatus, timeout=0
          written-local-variables:
            access HTPC_HpIcdsTpcp21: accessed-variable=HTPC_HpIcdsTpcp21
        RE_HTPC_122_TEV  # SyncChTpcp
          read-local-variables:
            6 x access:
              HTPC_HpBusCpCtrlSet: accessed-variable=HTPC_HpBusCpCtrlSet
              HTPC_HpBusCpSt: accessed-variable=HTPC_HpBusCpSt
              HTPC_HpBusTrpState: accessed-variable=HTPC_HpBusTrpState
              HTPC_LoopDiversity: accessed-variable=HTPC_LoopDiversity
              HTPC_PChO12: accessed-variable=HTPC_PChO12
              HTPC_TChO7: accessed-variable=HTPC_TChO7
          sync call sc_SetEventStatus: operation=R_HTPC_stDgoHeatPmpCmpHPsft.SetEventStatus, timeout=0
          written-local-variables:
            access HTPC_HpChTpcp22: accessed-variable=HTPC_HpChTpcp22
        RE_HTPC_123_TEV  # SyncOhxTpcp
          read-local-variables:
            6 x access:
              HTPC_HpBusCpCtrlSet: accessed-variable=HTPC_HpBusCpCtrlSet
              HTPC_HpBusCpSt: accessed-variable=HTPC_HpBusCpSt
              HTPC_HpBusTrpState: accessed-variable=HTPC_HpBusTrpState
              HTPC_LoopDiversity: accessed-variable=HTPC_LoopDiversity
              HTPC_POhxO13: accessed-variable=HTPC_POhxO13
              HTPC_TOhxO8: accessed-variable=HTPC_TOhxO8
          sync call sc_SetEventStatus: operation=R_HTPC_stDgoHeatPmpCmpHPsft.SetEventStatus, timeout=0
          written-local-variables:
            access HTPC_HpOhxTpcp23: accessed-variable=HTPC_HpOhxTpcp23
        RE_HTPC_124_TEV  # SyncCompTpcp
          read-local-variables:
            6 x access:
              HTPC_HpBusCpCtrlSet: accessed-variable=HTPC_HpBusCpCtrlSet
              HTPC_HpBusCpSt: accessed-variable=HTPC_HpBusCpSt
              HTPC_HpBusTrpState: accessed-variable=HTPC_HpBusTrpState
              HTPC_LoopDiversity: accessed-variable=HTPC_LoopDiversity
              HTPC_PCompO14: accessed-variable=HTPC_PCompO14
              HTPC_TCompO9: accessed-variable=HTPC_TCompO9
          sync call sc_SetEventStatus: operation=R_HTPC_stDgoHeatPmpCmpHPsft.SetEventStatus, timeout=0
          written-local-variables:
            access HTPC_CompTpcp24: accessed-variable=HTPC_CompTpcp24
        RE_HTPC_300_TEV  # SyncThermoCycleStatus
          read-local-variables:
            38 x access:
              HTPC_CompTpcp19In: accessed-variable=HTPC_CompTpcp19In
              HTPC_CompTpcp24: accessed-variable=HTPC_CompTpcp24
              HTPC_HpAcSensor0: accessed-variable=HTPC_HpAcSensor0
              HTPC_HpAcSupportState: accessed-variable=HTPC_HpAcSupportState
              HTPC_HpAcTpcp20: accessed-variable=HTPC_HpAcTpcp20
              HTPC_HpBusTrpSet_Loop: accessed-variable=HTPC_HpBusTrpSet_Loop  # 20240516 data access and name modify from HTPC_HpBusTrpSet_NBI to HTPC_HpBusTrpSet_Loop
              HTPC_HpChSensor2: accessed-variable=HTPC_HpChSensor2
              HTPC_HpChSupportState: accessed-variable=HTPC_HpChSupportState
              HTPC_HpChTpcp22: accessed-variable=HTPC_HpChTpcp22
              HTPC_HpCompState: accessed-variable=HTPC_HpCompState
              HTPC_HpErv{1..3}State: accessed-variable=HTPC_HpErv{1..3}State
              HTPC_HpExvAState: accessed-variable=HTPC_HpExvAState
              HTPC_HpExvBState: accessed-variable=HTPC_HpExvBState
              HTPC_HpExvByPassState: accessed-variable=HTPC_HpExvByPassState
              HTPC_HpExvHState: accessed-variable=HTPC_HpExvHState
              HTPC_HpIcdsSensor1: accessed-variable=HTPC_HpIcdsSensor1
              HTPC_HpIcdsSupportState: accessed-variable=HTPC_HpIcdsSupportState
              HTPC_HpIcdsTpcp21: accessed-variable=HTPC_HpIcdsTpcp21
              HTPC_HpOhxSensor3: accessed-variable=HTPC_HpOhxSensor3
              HTPC_HpOhxSupportState: accessed-variable=HTPC_HpOhxSupportState
              HTPC_HpOhxTpcp18In: accessed-variable=HTPC_HpOhxTpcp18In
              HTPC_HpOhxTpcp23: accessed-variable=HTPC_HpOhxTpcp23
              HTPC_PAcO10: accessed-variable=HTPC_PAcO10
              HTPC_PChO12: accessed-variable=HTPC_PChO12
              HTPC_PCompIn15: accessed-variable=HTPC_PCompIn15
              HTPC_PCompO14: accessed-variable=HTPC_PCompO14
              HTPC_PIcdsO11: accessed-variable=HTPC_PIcdsO11
              HTPC_POhxIn17: accessed-variable=HTPC_POhxIn17
              HTPC_POhxO13: accessed-variable=HTPC_POhxO13
              HTPC_TAcO5: accessed-variable=HTPC_TAcO5
              HTPC_TChO7: accessed-variable=HTPC_TChO7
              HTPC_TCompIn4: accessed-variable=HTPC_TCompIn4
              HTPC_TCompO9: accessed-variable=HTPC_TCompO9
              HTPC_TIcdsO6: accessed-variable=HTPC_TIcdsO6
              HTPC_TOhxIn16: accessed-variable=HTPC_TOhxIn16
              HTPC_TOhxO8: accessed-variable=HTPC_TOhxO8
          sync call sc_SetEventStatus: operation=R_HTPC_stDgoHeatPmpCmpHPsft.SetEventStatus, timeout=0
          written-local-variables:
            4 x access:
              HTPC_HpBusActStatus: accessed-variable=HTPC_HpBusActStatus
              HTPC_HpBusCpSt: accessed-variable=HTPC_HpBusCpSt
              HTPC_HpBusTrpState: accessed-variable=HTPC_HpBusTrpState
              HTPC_HpOverallCycleStatus: accessed-variable=HTPC_HpOverallCycleStatus
        RE_HTPC_410_TEV  # CalcHpReqMode
          read-local-variables:
            access HTPC_HpBusCpSt: accessed-variable=HTPC_HpBusCpSt
            access HTPC_HpBusTrpSet_NBI: accessed-variable=HTPC_HpBusTrpSet_NBI
            access HTPC_HpBusTrpState: accessed-variable=HTPC_HpBusTrpState
          sync call sc_SetEventStatus: operation=R_HTPC_stDgoHeatPmpCmpHPsft.SetEventStatus, timeout=0
          written-local-variables:
            access HTPC_HpBusTrpSet_Req: accessed-variable=HTPC_HpBusTrpSet_Req
        RE_HTPC_420_TEV  # CalcHpLoopMode
          read-local-variables:
            5 x access:
              HTPC_HpBusActStatus: accessed-variable=HTPC_HpBusActStatus
              HTPC_HpBusCmptModeResp: accessed-variable=HTPC_HpBusCmptModeResp
              HTPC_HpBusTrpSet_Req: accessed-variable=HTPC_HpBusTrpSet_Req
              HTPC_HpBusTrpState: accessed-variable=HTPC_HpBusTrpState
              HTPC_LoopDiversity: accessed-variable=HTPC_LoopDiversity
          sync call sc_SetEventStatus: operation=R_HTPC_stDgoHeatPmpCmpHPsft.SetEventStatus, timeout=0
          written-local-variables:
            access HTPC_HpBusTrpSet_Loop: accessed-variable=HTPC_HpBusTrpSet_Loop
        RE_HTPC_430_TEV  # CalcHpCmptMode
          read-local-variables:
            5 x access:
              HTPC_HpBusActCtrlSet: accessed-variable=HTPC_HpBusActCtrlSet
              HTPC_HpBusActStatus: accessed-variable=HTPC_HpBusActStatus
              HTPC_HpBusCpSt: accessed-variable=HTPC_HpBusCpSt
              HTPC_HpBusTrpSet_Loop: accessed-variable=HTPC_HpBusTrpSet_Loop
              HTPC_LoopDiversity: accessed-variable=HTPC_LoopDiversity
          sync call sc_SetEventStatus: operation=R_HTPC_stDgoHeatPmpCmpHPsft.SetEventStatus, timeout=0
          written-local-variables:
            access HTPC_HpBusCmptModeResp: accessed-variable=HTPC_HpBusCmptModeResp
            access HTPC_HpBusTrpSet_Cmpt: accessed-variable=HTPC_HpBusTrpSet_Cmpt
        RE_HTPC_440_TEV  # CalcHpCtrlMode
          read-local-variables:
            6 x access:
              HTPC_HpBusActStatus: accessed-variable=HTPC_HpBusActStatus
              HTPC_HpBusCmptModeResp: accessed-variable=HTPC_HpBusCmptModeResp
              HTPC_HpBusCpSt: accessed-variable=HTPC_HpBusCpSt
              HTPC_HpBusTrpSet_Cmpt: accessed-variable=HTPC_HpBusTrpSet_Cmpt
              HTPC_HpBusTrpState: accessed-variable=HTPC_HpBusTrpState
              HTPC_LoopDiversity: accessed-variable=HTPC_LoopDiversity
          sync call sc_SetEventStatus: operation=R_HTPC_stDgoHeatPmpCmpHPsft.SetEventStatus, timeout=0
          written-local-variables:
            access HTPC_HpBusActCtrlSet: accessed-variable=HTPC_HpBusActCtrlSet
            access HTPC_HpBusCpCtrlSet: accessed-variable=HTPC_HpBusCpCtrlSet
            access HTPC_HpBusTrpSet_Ctrl: accessed-variable=HTPC_HpBusTrpSet_Ctrl
        RE_HTPC_600_TEV  # CtrlExvA
          data-receive-point-by-arguments:
            access dr_EXV3State: accessed-variable=R_EXV3State.EXV3State
          data-send-points:
            access ds_EXV3Cmd: accessed-variable=P_EXV3Cmd.EXV3Cmd
          read-local-variables:
            6 x access:
              HTPC_HpBusActCtrlSet: accessed-variable=HTPC_HpBusActCtrlSet
              HTPC_HpBusActStatus: accessed-variable=HTPC_HpBusActStatus
              HTPC_HpBusCpSt: accessed-variable=HTPC_HpBusCpSt
              HTPC_HpBusTrpSet_Ctrl: accessed-variable=HTPC_HpBusTrpSet_Ctrl
              HTPC_HpBusTrpState: accessed-variable=HTPC_HpBusTrpState
              HTPC_LoopDiversity: accessed-variable=HTPC_LoopDiversity
          sync call sc_SetEventStatus: operation=R_HTPC_stDgoHeatPmpCmpHPsft.SetEventStatus, timeout=0
          written-local-variables:
            access HTPC_HpExvAState: accessed-variable=HTPC_HpExvAState
        RE_HTPC_601_TEV  # CtrlExvByPass
          data-receive-point-by-arguments:
            access dr_EXV4State: accessed-variable=R_EXV4State.EXV4State
          data-send-points:
            access ds_EXV4Cmd: accessed-variable=P_EXV4Cmd.EXV4Cmd
          read-local-variables:
            6 x access:
              HTPC_HpBusActCtrlSet: accessed-variable=HTPC_HpBusActCtrlSet
              HTPC_HpBusActStatus: accessed-variable=HTPC_HpBusActStatus
              HTPC_HpBusCpSt: accessed-variable=HTPC_HpBusCpSt
              HTPC_HpBusTrpSet_Ctrl: accessed-variable=HTPC_HpBusTrpSet_Ctrl
              HTPC_HpBusTrpState: accessed-variable=HTPC_HpBusTrpState
              HTPC_LoopDiversity: accessed-variable=HTPC_LoopDiversity
          sync call sc_SetEventStatus: operation=R_HTPC_stDgoHeatPmpCmpHPsft.SetEventStatus, timeout=0
          written-local-variables:
            access HTPC_HpExvByPassState: accessed-variable=HTPC_HpExvByPassState
        RE_HTPC_602_TEV  # CtrlExvB
          data-receive-point-by-arguments:
            access dr_EXV1State: accessed-variable=R_EXV1State.EXV1State
          data-send-points:
            access ds_EXV1Cmd: accessed-variable=P_EXV1Cmd.EXV1Cmd
          read-local-variables:
            6 x access:
              HTPC_HpBusActCtrlSet: accessed-variable=HTPC_HpBusActCtrlSet
              HTPC_HpBusActStatus: accessed-variable=HTPC_HpBusActStatus
              HTPC_HpBusCpSt: accessed-variable=HTPC_HpBusCpSt
              HTPC_HpBusTrpSet_Ctrl: accessed-variable=HTPC_HpBusTrpSet_Ctrl
              HTPC_HpBusTrpState: accessed-variable=HTPC_HpBusTrpState
              HTPC_LoopDiversity: accessed-variable=HTPC_LoopDiversity
          sync call sc_SetEventStatus: operation=R_HTPC_stDgoHeatPmpCmpHPsft.SetEventStatus, timeout=0
          written-local-variables:
            access HTPC_HpExvBState: accessed-variable=HTPC_HpExvBState
        RE_HTPC_603_TEV  # CtrlExvH
          data-receive-point-by-arguments:
            access dr_EXV2State: accessed-variable=R_EXV2State.EXV2State
          data-send-points:
            access ds_EXV2Cmd: accessed-variable=P_EXV2Cmd.EXV2Cmd
          read-local-variables:
            6 x access:
              HTPC_HpBusActCtrlSet: accessed-variable=HTPC_HpBusActCtrlSet
              HTPC_HpBusActStatus: accessed-variable=HTPC_HpBusActStatus
              HTPC_HpBusCpSt: accessed-variable=HTPC_HpBusCpSt
              HTPC_HpBusTrpSet_Ctrl: accessed-variable=HTPC_HpBusTrpSet_Ctrl
              HTPC_HpBusTrpState: accessed-variable=HTPC_HpBusTrpState
              HTPC_LoopDiversity: accessed-variable=HTPC_LoopDiversity
          sync call sc_SetEventStatus: operation=R_HTPC_stDgoHeatPmpCmpHPsft.SetEventStatus, timeout=0
          written-local-variables:
            access HTPC_HpExvHState: accessed-variable=HTPC_HpExvHState
        RE_HTPC_604_TEV  # CtrlComp
          data-receive-point-by-arguments:
            access dr_HVEC2HTPC: accessed-variable=R_HVEC2HTPC.HVEC2HTPC
            access dr_SUCRE: accessed-variable=R_SUCRE.SUCRE
          data-send-points:
            access ds_HTPC_Comp: accessed-variable=P_HTPC_Comp.HTPC_Comp
            access ds_HvecCmd: accessed-variable=P_HvecCmd.HvecCmd
          read-local-variables:
            6 x access:
              HTPC_HpBusActCtrlSet: accessed-variable=HTPC_HpBusActCtrlSet
              HTPC_HpBusActStatus: accessed-variable=HTPC_HpBusActStatus
              HTPC_HpBusCpSt: accessed-variable=HTPC_HpBusCpSt
              HTPC_HpBusTrpSet_Ctrl: accessed-variable=HTPC_HpBusTrpSet_Ctrl
              HTPC_HpBusTrpState: accessed-variable=HTPC_HpBusTrpState
              HTPC_LoopDiversity: accessed-variable=HTPC_LoopDiversity
          sync call sc_SetEventStatus: operation=R_HTPC_stDgoHeatPmpCmpHPsft.SetEventStatus, timeout=0
          written-local-variables:
            access HTPC_HpCompState: accessed-variable=HTPC_HpCompState
        RE_HTPC_605_TEV  # CtrlErv1
          data-receive-point-by-arguments:
            access dr_ERV1State: accessed-variable=R_ERV1State.ERV1State
          data-send-points:
            access ds_ERV1Cmd: accessed-variable=P_ERV1Cmd.ERV1Cmd
          read-local-variables:
            6 x access:
              HTPC_HpBusActCtrlSet: accessed-variable=HTPC_HpBusActCtrlSet
              HTPC_HpBusActStatus: accessed-variable=HTPC_HpBusActStatus
              HTPC_HpBusCpSt: accessed-variable=HTPC_HpBusCpSt
              HTPC_HpBusTrpSet_Ctrl: accessed-variable=HTPC_HpBusTrpSet_Ctrl
              HTPC_HpBusTrpState: accessed-variable=HTPC_HpBusTrpState
              HTPC_LoopDiversity: accessed-variable=HTPC_LoopDiversity
          sync call sc_SetEventStatus: operation=R_HTPC_stDgoHeatPmpCmpHPsft.SetEventStatus, timeout=0
          written-local-variables:
            access HTPC_HpErv1State: accessed-variable=HTPC_HpErv1State
        RE_HTPC_606_TEV  # CtrlErv2
          data-receive-point-by-arguments:
            access dr_ERV2State: accessed-variable=R_ERV2State.ERV2State
          data-send-points:
            access ds_ERV2Cmd: accessed-variable=P_ERV2Cmd.ERV2Cmd
          read-local-variables:
            6 x access:
              HTPC_HpBusActCtrlSet: accessed-variable=HTPC_HpBusActCtrlSet
              HTPC_HpBusActStatus: accessed-variable=HTPC_HpBusActStatus
              HTPC_HpBusCpSt: accessed-variable=HTPC_HpBusCpSt
              HTPC_HpBusTrpSet_Ctrl: accessed-variable=HTPC_HpBusTrpSet_Ctrl
              HTPC_HpBusTrpState: accessed-variable=HTPC_HpBusTrpState
              HTPC_LoopDiversity: accessed-variable=HTPC_LoopDiversity
          sync call sc_SetEventStatus: operation=R_HTPC_stDgoHeatPmpCmpHPsft.SetEventStatus, timeout=0
          written-local-variables:
            access HTPC_HpErv2State: accessed-variable=HTPC_HpErv2State
        RE_HTPC_607_TEV  # CtrlErv3
          data-receive-point-by-arguments:
            access dr_ERV3State: accessed-variable=R_ERV3State.ERV3State
          data-send-points:
            access ds_ERV3Cmd: accessed-variable=P_ERV3Cmd.ERV3Cmd
          read-local-variables:
            6 x access:
              HTPC_HpBusActCtrlSet: accessed-variable=HTPC_HpBusActCtrlSet
              HTPC_HpBusActStatus: accessed-variable=HTPC_HpBusActStatus
              HTPC_HpBusCpSt: accessed-variable=HTPC_HpBusCpSt
              HTPC_HpBusTrpSet_Ctrl: accessed-variable=HTPC_HpBusTrpSet_Ctrl
              HTPC_HpBusTrpState: accessed-variable=HTPC_HpBusTrpState
              HTPC_LoopDiversity: accessed-variable=HTPC_LoopDiversity
          sync call sc_SetEventStatus: operation=R_HTPC_stDgoHeatPmpCmpHPsft.SetEventStatus, timeout=0
          written-local-variables:
            access HTPC_HpErv3State: accessed-variable=HTPC_HpErv3State
        RE_HTPC_610_TEV  # CtrlAcSupport
          data-receive-point-by-arguments:
            access dr_Ext: accessed-variable=R_Ext.Ext
          read-local-variables:
            6 x access:
              HTPC_HpBusActCtrlSet: accessed-variable=HTPC_HpBusActCtrlSet
              HTPC_HpBusActStatus: accessed-variable=HTPC_HpBusActStatus
              HTPC_HpBusCpSt: accessed-variable=HTPC_HpBusCpSt
              HTPC_HpBusTrpSet_Ctrl: accessed-variable=HTPC_HpBusTrpSet_Ctrl
              HTPC_HpBusTrpState: accessed-variable=HTPC_HpBusTrpState
              HTPC_LoopDiversity: accessed-variable=HTPC_LoopDiversity
          sync call sc_SetEventStatus: operation=R_HTPC_stDgoHeatPmpCmpHPsft.SetEventStatus, timeout=0
          written-local-variables:
            access HTPC_HpAcSupportState: accessed-variable=HTPC_HpAcSupportState
        RE_HTPC_611_TEV  # CtrlIcdsSupport
          data-receive-point-by-arguments:
            access dr_Ext: accessed-variable=R_Ext.Ext
          read-local-variables:
            6 x access:
              HTPC_HpBusActCtrlSet: accessed-variable=HTPC_HpBusActCtrlSet
              HTPC_HpBusActStatus: accessed-variable=HTPC_HpBusActStatus
              HTPC_HpBusCpSt: accessed-variable=HTPC_HpBusCpSt
              HTPC_HpBusTrpSet_Ctrl: accessed-variable=HTPC_HpBusTrpSet_Ctrl
              HTPC_HpBusTrpState: accessed-variable=HTPC_HpBusTrpState
              HTPC_LoopDiversity: accessed-variable=HTPC_LoopDiversity
          sync call sc_SetEventStatus: operation=R_HTPC_stDgoHeatPmpCmpHPsft.SetEventStatus, timeout=0
          written-local-variables:
            access HTPC_HpIcdsSupportState: accessed-variable=HTPC_HpIcdsSupportState
        RE_HTPC_612_TEV  # CtrlChSupport
          data-receive-point-by-arguments:
            access dr_CREPE: accessed-variable=R_CREPE.CREPE
            access dr_SUCRE: accessed-variable=R_SUCRE.SUCRE
          data-send-points:
            access ds_HTPC_CH: accessed-variable=P_HTPC_CH.HTPC_CH
          read-local-variables:
            6 x access:
              HTPC_HpBusActCtrlSet: accessed-variable=HTPC_HpBusActCtrlSet
              HTPC_HpBusActStatus: accessed-variable=HTPC_HpBusActStatus
              HTPC_HpBusCpSt: accessed-variable=HTPC_HpBusCpSt
              HTPC_HpBusTrpSet_Ctrl: accessed-variable=HTPC_HpBusTrpSet_Ctrl
              HTPC_HpBusTrpState: accessed-variable=HTPC_HpBusTrpState
              HTPC_LoopDiversity: accessed-variable=HTPC_LoopDiversity
          sync call sc_SetEventStatus: operation=R_HTPC_stDgoHeatPmpCmpHPsft.SetEventStatus, timeout=0
          written-local-variables:
            access HTPC_HpChSupportState: accessed-variable=HTPC_HpChSupportState
        RE_HTPC_613_TEV  # CtrlOhxSupport
          data-receive-point-by-arguments:
            access dr_CREPE: accessed-variable=R_CREPE.CREPE
            access dr_SUCRE: accessed-variable=R_SUCRE.SUCRE
          data-send-points:
            access ds_HTPC_OHX: accessed-variable=P_HTPC_OHX.HTPC_OHX
          read-local-variables:
            6 x access:
              HTPC_HpBusActCtrlSet: accessed-variable=HTPC_HpBusActCtrlSet
              HTPC_HpBusActStatus: accessed-variable=HTPC_HpBusActStatus
              HTPC_HpBusCpSt: accessed-variable=HTPC_HpBusCpSt
              HTPC_HpBusTrpSet_Ctrl: accessed-variable=HTPC_HpBusTrpSet_Ctrl
              HTPC_HpBusTrpState: accessed-variable=HTPC_HpBusTrpState
              HTPC_LoopDiversity: accessed-variable=HTPC_LoopDiversity
          sync call sc_SetEventStatus: operation=R_HTPC_stDgoHeatPmpCmpHPsft.SetEventStatus, timeout=0
          written-local-variables:
            access HTPC_HpOhxSupportState: accessed-variable=HTPC_HpOhxSupportState
package /SoftwareTypes/Interfaces
  client server interface DiagnosticMonitor: is-service=true
    4 x operation, all with possible-error=[E_NOT_OK, E_OK]:
      ClearPrestoredFreezeFrame
      PrestoreFreezeFrame
      ResetEventStatus
      SetEventStatus
        arg EventStatus: type=Dem_EventStatusType, direction=IN
    error E_NOT_OK: error-code=1
    error E_OK: error-code=0  # Operation successful
  mode switch interface IF_UCE_stWkuMainRelSt: is-service=true
    mode group RCD_stWkuMainRelSt: sw-calibration-access=READ-ONLY, type=RCD_stWkuMainRelSt
  34 x sender receiver interface:
    IF_CREPE
      data CREPE: sw-calibration-access=READ-ONLY, type=ARDT_CREPE, init-value=constant-reference={short-label=IV_CREPE, constant=IV_CREPE}
    IF_ChPress
      data ChPress: sw-calibration-access=READ-ONLY, type=APDT_ChPress, init-value=constant-reference={short-label=IV_ChPress, constant=IV_ChPress}
    IF_ChTemp
      data ChTemp: sw-calibration-access=READ-ONLY, type=APDT_ChTemp, init-value=constant-reference={short-label=IV_ChTemp, constant=IV_ChTemp}
    IF_CompPress
      data CompPress: sw-calibration-access=READ-ONLY, type=APDT_CompPress, init-value=constant-reference={short-label=IV_CompPress, constant=IV_CompPress}
    IF_CompTemp
      data CompTemp: sw-calibration-access=READ-ONLY, type=APDT_CompTemp, init-value=constant-reference={short-label=IV_CompTemp, constant=IV_CompTemp}
    IF_ERV1Cmd
      data ERV1Cmd: sw-calibration-access=READ-ONLY, type=ARDT_ERV1Cmd, init-value=constant-reference={short-label=IV_ERV1Cmd, constant=IV_ERV1Cmd}
    IF_ERV1State
      data ERV1State: sw-calibration-access=READ-ONLY, type=ARDT_ERV1State, init-value=constant-reference={short-label=IV_ERV1State, constant=IV_ERV1State}
    IF_ERV2Cmd
      data ERV2Cmd: sw-calibration-access=READ-ONLY, type=ARDT_ERV2Cmd, init-value=constant-reference={short-label=IV_ERV2Cmd, constant=IV_ERV2Cmd}
    IF_ERV2State
      data ERV2State: sw-calibration-access=READ-ONLY, type=ARDT_ERV2State, init-value=constant-reference={short-label=IV_ERV2State, constant=IV_ERV2State}
    IF_ERV3Cmd
      data ERV3Cmd: sw-calibration-access=READ-ONLY, type=ARDT_ERV3Cmd, init-value=constant-reference={short-label=IV_ERV3Cmd, constant=IV_ERV3Cmd}
    IF_ERV3State
      data ERV3State: sw-calibration-access=READ-ONLY, type=ARDT_ERV3State, init-value=constant-reference={short-label=IV_ERV3State, constant=IV_ERV3State}
    IF_EVAPPress
      data EVAPPress: sw-calibration-access=READ-ONLY, type=APDT_EVAPPress, init-value=constant-reference={short-label=IV_EVAPPress, constant=IV_EVAPPress}
    IF_EVAPTemp
      data EVAPTemp: sw-calibration-access=READ-ONLY, type=APDT_EVAPTemp, init-value=constant-reference={short-label=IV_EVAPTemp, constant=IV_EVAPTemp}
    IF_EXV1Cmd
      data EXV1Cmd: sw-calibration-access=READ-ONLY, type=ARDT_EXV1Cmd, init-value=constant-reference={short-label=IV_EXV1Cmd, constant=IV_EXV1Cmd}
    IF_EXV1State
      data EXV1State: sw-calibration-access=READ-ONLY, type=ARDT_EXV1State, init-value=constant-reference={short-label=IV_EXV1State, constant=IV_EXV1State}
    IF_EXV2Cmd
      data EXV2Cmd: sw-calibration-access=READ-ONLY, type=ARDT_EXV2Cmd, init-value=constant-reference={short-label=IV_EXV2Cmd, constant=IV_EXV2Cmd}
    IF_EXV2State
      data EXV2State: sw-calibration-access=READ-ONLY, type=ARDT_EXV2State, init-value=constant-reference={short-label=IV_EXV2State, constant=IV_EXV2State}
    IF_EXV3Cmd
      data EXV3Cmd: sw-calibration-access=READ-ONLY, type=ARDT_EXV3Cmd, init-value=constant-reference={short-label=IV_EXV3Cmd, constant=IV_EXV3Cmd}
    IF_EXV3State
      data EXV3State: sw-calibration-access=READ-ONLY, type=ARDT_EXV3State, init-value=constant-reference={short-label=IV_EXV3State, constant=IV_EXV3State}
    IF_EXV4Cmd
      data EXV4Cmd: sw-calibration-access=READ-ONLY, type=ARDT_EXV4Cmd, init-value=constant-reference={short-label=IV_EXV4Cmd, constant=IV_EXV4Cmd}
    IF_EXV4State
      data EXV4State: sw-calibration-access=READ-ONLY, type=ARDT_EXV4State, init-value=constant-reference={short-label=IV_EXV4State, constant=IV_EXV4State}
    IF_Ext
      data Ext: sw-calibration-access=READ-ONLY, type=ARDT_Ext, init-value=constant-reference={short-label=IV_Ext, constant=IV_Ext}
    IF_HTPC_CH
      data HTPC_CH: sw-calibration-access=READ-ONLY, type=ARDT_HTPC_CH, init-value=constant-reference={short-label=IV_HTPC_CH, constant=IV_HTPC_CH}
    IF_HTPC_Comp
      data HTPC_Comp: sw-calibration-access=READ-ONLY, type=ARDT_HTPC_Comp, init-value=constant-reference={short-label=IV_HTPC_Comp, constant=IV_HTPC_Comp}
    IF_HTPC_ICDS
      data HTPC_ICDS: sw-calibration-access=READ-ONLY, type=ARDT_HTPC_ICDS, init-value=constant-reference={short-label=IV_HTPC_ICDS, constant=IV_HTPC_ICDS}
    IF_HTPC_NBI
      data HTPC_NBI: sw-calibration-access=READ-ONLY, type=ARDT_HTPC_NBI, init-value=constant-reference={short-label=IV_HTPC_NBI, constant=IV_HTPC_NBI}
    IF_HTPC_OHX
      data HTPC_OHX: sw-calibration-access=READ-ONLY, type=ARDT_HTPC_OHX, init-value=constant-reference={short-label=IV_HTPC_CH, constant=IV_HTPC_OHX}
    IF_HVEC2HTPC
      data HVEC2HTPC: sw-calibration-access=READ-ONLY, type=ARDT_HVEC2HTPC, init-value=constant-reference={short-label=IV_HVEC2HTPC, constant=IV_HVEC2HTPC}
    IF_HvecCmd
      data HvecCmd: sw-calibration-access=READ-ONLY, type=ARDT_HvecCmd, init-value=constant-reference={short-label=IV_HvecCmd, constant=IV_HvecCmd}
    IF_ICDSPress
      data ICDSPress: sw-calibration-access=READ-ONLY, type=APDT_ICDSPress, init-value=constant-reference={short-label=IV_ICDSPress, constant=IV_ICDSPress}
    IF_ICDSTemp
      data ICDSTemp: sw-calibration-access=READ-ONLY, type=APDT_ICDSTemp, init-value=constant-reference={short-label=IV_ICDSTemp, constant=IV_ICDSTemp}
    IF_OHXPress
      data OHXPress: sw-calibration-access=READ-ONLY, type=APDT_OHXPress, init-value=constant-reference={short-label=IV_OHXPress, constant=IV_OHXPress}
    IF_OHXTemp
      data OHXTemp: sw-calibration-access=READ-ONLY, type=APDT_OHXTemp, init-value=constant-reference={short-label=IV_OHXTemp, constant=IV_OHXTemp}
    IF_SUCRE
      data SUCRE: sw-calibration-access=READ-ONLY, type=ARDT_SUCRE, init-value=constant-reference={short-label=IV_SUCRE, constant=IV_SUCRE}
package /SoftwareTypes/SwcImplementations
  swc implementation IMP_HTPC: programming-language=C, sw-version=1.0.0.0, vendor-id=0, behavior=IB_HTPC
    code-descriptors:
      code CodeDescriptor
